BO_ 2565406709 ACKM_F5: 8 NODE_F5
 SG_ Pgn_Ack_E8FFF5 m0 : 40|24@1+ (1,0) [0|16777215] "binary"  PCM
 SG_ Pgn_Nack_E8FFF5 m1 : 40|24@1+ (1,0) [0|16777215] "binary"  PCM
 SG_ Pgn_Ad_E8FFF5 m2 : 40|24@1+ (1,0) [0|16777215] "binary"  PCM
 SG_ Pgn_Busy_E8FFF5 m3 : 40|24@1+ (1,0) [0|16777215] "binary"  PCM
 SG_ AddrAckd_E8FFF5 m0 : 32|8@1+ (1,0) [0|255] ""  PCM
 SG_ AddrNack_E8FFF5 m1 : 32|8@1+ (1,0) [0|255] ""  PCM
 SG_ AddrAccessDenied_E8FFF5 m2 : 32|8@1+ (1,0) [0|255] ""  PCM
 SG_ AddrBusy_E8FFF5 m3 : 32|8@1+ (1,0) [0|255] ""  PCM
 SG_ CtrlByte_Ackm_E8FFF5 M : 0|8@1+ (1,0) [0|255] "binary"  PCM

BO_ 2565406710 ACKM_F6: 8 NODE_F6
 SG_ Pgn_Ack_E8FFF6 m0 : 40|24@1+ (1,0) [0|16777215] "binary"  PCM
 SG_ Pgn_Nack_E8FFF6 m1 : 40|24@1+ (1,0) [0|16777215] "binary"  PCM
 SG_ Pgn_Ad_E8FFF6 m2 : 40|24@1+ (1,0) [0|16777215] "binary"  PCM
 SG_ Pgn_Busy_E8FFF6 m3 : 40|24@1+ (1,0) [0|16777215] "binary"  PCM
 SG_ AddrAckd_E8FFF6 m0 : 32|8@1+ (1,0) [0|255] ""  PCM
 SG_ AddrNack_E8FFF6 m1 : 32|8@1+ (1,0) [0|255] ""  PCM
 SG_ AddrAccessDenied_E8FFF6 m2 : 32|8@1+ (1,0) [0|255] ""  PCM
 SG_ AddrBusy_E8FFF6 m3 : 32|8@1+ (1,0) [0|255] ""  PCM
 SG_ CtrlByte_Ackm_E8FFF6 M : 0|8@1+ (1,0) [0|255] "binary"  PCM

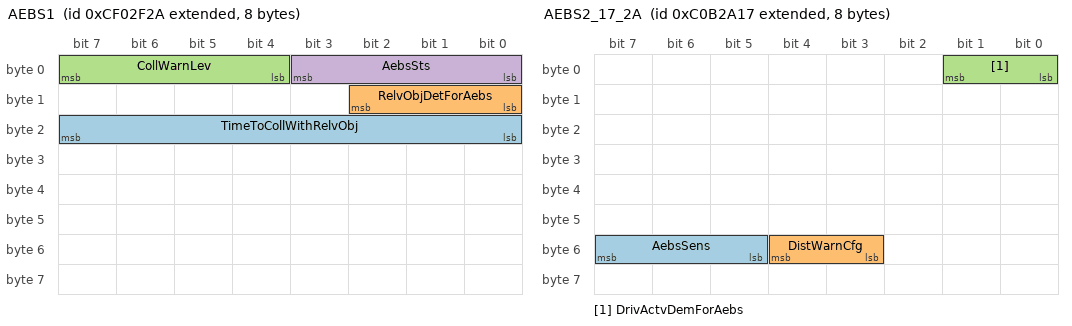
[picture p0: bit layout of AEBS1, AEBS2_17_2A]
BO_ 2364550954 AEBS1: 8 LDW
 SG_ TimeToCollWithRelvObj : 16|8@1+ (0.05,0) [0|12.5] "s"  PCM
 SG_ RelvObjDetForAebs : 8|3@1+ (1,0) [0|7] ""  PCM
 SG_ CollWarnLev : 4|4@1+ (1,0) [0|15] ""  PCM
 SG_ AebsSts : 0|4@1+ (1,0) [0|15] ""  PCM

BO_ 2349541911 AEBS2_17_2A: 8 ICC
 SG_ AebsSens : 53|3@1+ (1,0) [0|7] ""  PCM,LDW
 SG_ DistWarnCfg : 51|2@1+ (1,0) [0|3] ""  PCM,LDW
 SG_ DrivActvDemForAebs : 0|2@1+ (1,0) [0|3] ""  PCM,LDW

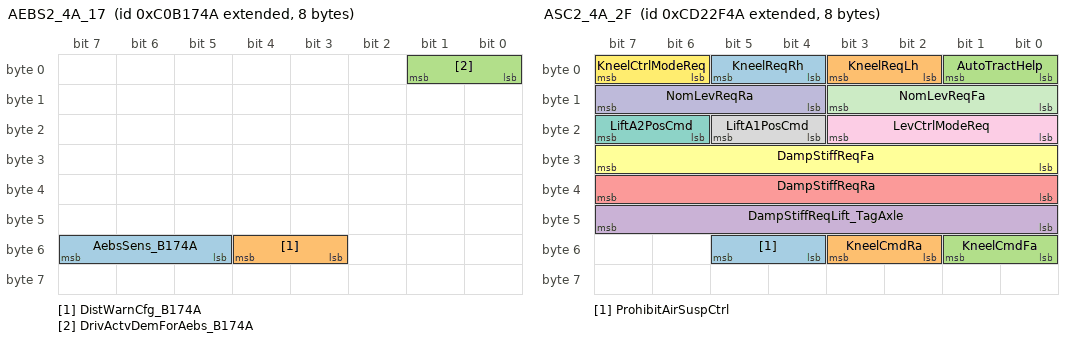
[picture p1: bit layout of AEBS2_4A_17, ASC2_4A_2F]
BO_ 2349537098 AEBS2_4A_17: 8 PCM
 SG_ AebsSens_B174A : 53|3@1+ (1,0) [0|7] ""  ICC
 SG_ DistWarnCfg_B174A : 51|2@1+ (1,0) [0|3] ""  ICC
 SG_ DrivActvDemForAebs_B174A : 0|2@1+ (1,0) [0|3] ""  ICC

BO_ 2566845696 AMB_00: 8 ECM
 SG_ BaromPrs : 0|8@1+ (0.5,0) [0|125] "kPa"  PCM

BO_ 2566845729 AMB_21: 8 BCM
 SG_ AmbAirTemp : 24|16@1+ (0.03125,-273) [-273|1734.96875] "�C"  PCM

BO_ 2566774807 AMB2_17: 8 ICC
 SG_ SolarIntensPc : 0|8@1+ (0.4,0) [0|100] "%"  PCM

BO_ 2566837537 AS_21: 8 BCM
 SG_ Altern1Sts : 16|2@1+ (1,0) [0|3] ""  PCM

BO_ 2365479471 ASC1_2F: 8 ECAS
 SG_ SuspCtrlRefusalInfo : 56|4@1+ (1,0) [0|15] ""  PCM
 SG_ SpeedDepLevCtrlSts : 54|2@1+ (1,0) [0|3] ""  PCM
 SG_ AllowLevCtrlDurBrkSts : 52|2@1+ (1,0) [0|3] ""  PCM
 SG_ SuspRemCtrl2 : 50|2@1+ (1,0) [0|3] ""  PCM
 SG_ SuspRemCtrl1 : 48|2@1+ (1,0) [0|3] ""  PCM
 SG_ LiftA2Pos : 46|2@1+ (1,0) [0|3] ""  PCM
 SG_ RaInBumperRng : 42|2@1+ (1,0) [0|3] ""  PCM
 SG_ FaInBumperRng : 40|2@1+ (1,0) [0|3] ""  PCM
 SG_ LiftA1Pos : 38|2@1+ (1,0) [0|3] ""  PCM
 SG_ DoorRels : 36|2@1+ (1,0) [0|3] ""  PCM
 SG_ VehMotInh : 34|2@1+ (1,0) [0|3] ""  PCM
 SG_ SecurDev : 32|2@1+ (1,0) [0|3] ""  PCM
 SG_ LevCtrlMode : 28|4@1+ (1,0) [0|15] ""  PCM
 SG_ KneelInfo : 24|4@1+ (1,0) [0|15] ""  PCM
 SG_ LiftCtrlModeRa : 22|2@1+ (1,0) [0|3] ""  PCM
 SG_ LiftCtrlModeFa : 20|2@1+ (1,0) [0|3] ""  PCM
 SG_ LowCtrlModeRa : 18|2@1+ (1,0) [0|3] ""  PCM
 SG_ LowCtrlModeFa : 16|2@1+ (1,0) [0|3] ""  PCM
 SG_ AbvNomLevRa : 14|2@1+ (1,0) [0|3] ""  PCM
 SG_ AbvNomLevFa : 12|2@1+ (1,0) [0|3] ""  PCM
 SG_ BlwNomLevRa : 10|2@1+ (1,0) [0|3] ""  PCM
 SG_ BlwNomLevFa : 8|2@1+ (1,0) [0|3] ""  PCM
 SG_ NomLevRa : 4|4@1+ (1,0) [0|15] ""  PCM
 SG_ NomLevFa : 0|4@1+ (1,0) [0|15] ""  PCM

BO_ 2362584906 ASC2_4A_2F: 8 PCM
 SG_ ProhibitAirSuspCtrl : 52|2@1+ (1,0) [0|3] ""  ECAS
 SG_ KneelCmdRa : 50|2@1+ (1,0) [0|3] ""  ECAS
 SG_ KneelCmdFa : 48|2@1+ (1,0) [0|3] ""  ECAS
 SG_ DampStiffReqLift_TagAxle : 40|8@1+ (0.4,0) [0|100] "%"  ECAS
 SG_ DampStiffReqRa : 32|8@1+ (0.4,0) [0|100] "%"  ECAS
 SG_ DampStiffReqFa : 24|8@1+ (0.4,0) [0|100] "%"  ECAS
 SG_ LiftA2PosCmd : 22|2@1+ (1,0) [0|3] ""  ECAS
 SG_ LiftA1PosCmd : 20|2@1+ (1,0) [0|3] ""  ECAS
 SG_ LevCtrlModeReq : 16|4@1+ (1,0) [0|15] ""  ECAS
 SG_ NomLevReqRa : 12|4@1+ (1,0) [0|15] ""  ECAS
 SG_ NomLevReqFa : 8|4@1+ (1,0) [0|15] ""  ECAS
 SG_ KneelCtrlModeReq : 6|2@1+ (1,0) [0|3] ""  ECAS
 SG_ KneelReqRh : 4|2@1+ (1,0) [0|3] ""  ECAS
 SG_ KneelReqLh : 2|2@1+ (1,0) [0|3] ""  ECAS
 SG_ AutoTractHelp : 0|2@1+ (1,0) [0|3] ""  ECAS

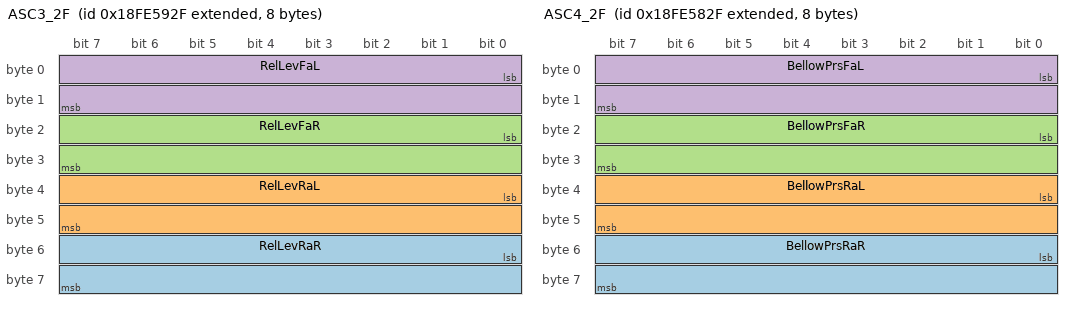
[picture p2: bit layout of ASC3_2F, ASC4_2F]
BO_ 2566805807 ASC3_2F: 8 ECAS
 SG_ RelLevRaR : 48|16@1+ (0.1,-3200) [-3200|3225.5] "mm"  PCM
 SG_ RelLevRaL : 32|16@1+ (0.1,-3200) [-3200|3225.5] "mm"  PCM
 SG_ RelLevFaR : 16|16@1+ (0.1,-3200) [-3200|3225.5] "mm"  PCM
 SG_ RelLevFaL : 0|16@1+ (0.1,-3200) [-3200|3225.5] "mm"  PCM

BO_ 2566805551 ASC4_2F: 8 ECAS
 SG_ BellowPrsRaR : 48|16@1+ (0.1,0) [0|6425.5] "kPa"  PCM
 SG_ BellowPrsRaL : 32|16@1+ (0.1,0) [0|6425.5] "kPa"  PCM
 SG_ BellowPrsFaR : 16|16@1+ (0.1,0) [0|6425.5] "kPa"  PCM
 SG_ BellowPrsFaL : 0|16@1+ (0.1,0) [0|6425.5] "kPa"  PCM

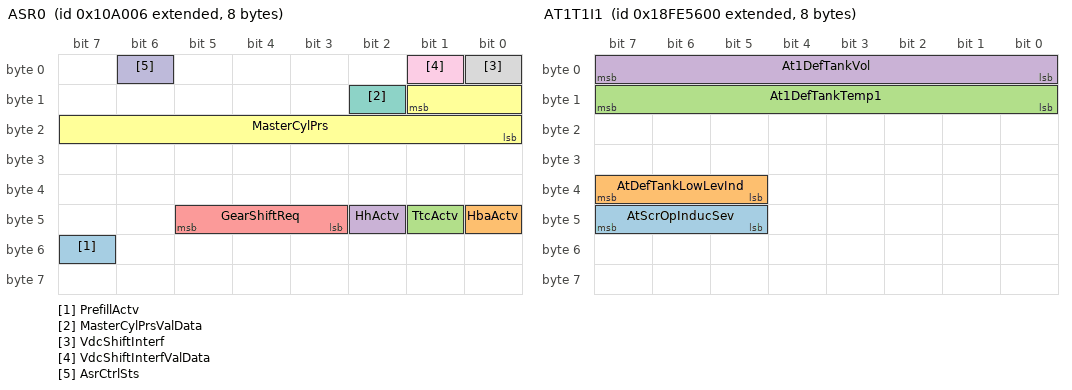
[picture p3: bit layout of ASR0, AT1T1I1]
BO_ 2148573190 ASR0: 8 NODE_6
 SG_ PrefillActv : 55|1@0+ (1,0) [0|1] ""  PCM,AEBS
 SG_ HbaActv : 40|1@0+ (1,0) [0|1] ""  PCM,AEBS
 SG_ TtcActv : 41|1@0+ (1,0) [0|1] ""  PCM,AEBS
 SG_ HhActv : 42|1@0+ (1,0) [0|1] ""  PCM,AEBS
 SG_ GearShiftReq : 45|3@0+ (1,0) [0|7] ""  PCM,AEBS
 SG_ MasterCylPrs : 9|10@0+ (0.25,0) [0|200] "bar"  PCM,AEBS
 SG_ MasterCylPrsValData : 10|1@0+ (1,0) [0|1] ""  PCM,AEBS
 SG_ VdcShiftInterf : 0|1@0+ (1,0) [0|1] ""  PCM,AEBS
 SG_ VdcShiftInterfValData : 1|1@0+ (1,0) [0|1] ""  PCM,AEBS
 SG_ AsrCtrlSts : 6|1@0+ (1,0) [0|1] ""  PCM,AEBS

BO_ 2566763008 AT1IMG: 8 ECM
 SG_ At1DpfDiffPrs : 32|16@1+ (0.1,0) [0|6425.5] "kPa"  PCM

BO_ 2566804992 AT1T1I1: 8 ECM
 SG_ AtScrOpInducSev : 45|3@1+ (1,0) [0|7] ""  PCM
 SG_ AtDefTankLowLevInd : 37|3@1+ (1,0) [0|7] ""  PCM
 SG_ At1DefTankTemp1 : 8|8@1+ (1,-40) [-40|210] "�C"  PCM
 SG_ At1DefTankVol : 0|8@1+ (0.4,0) [0|100] "%"  PCM

BO_ 2564685591 ATR_17: 8 ICC
 SG_ AntiTheftPswRepr : 8|56@1+ (1,0) [0|255] "ASCII"  PCM
 SG_ AntiTheftCmdSts : 5|3@1+ (1,0) [0|7] ""  PCM

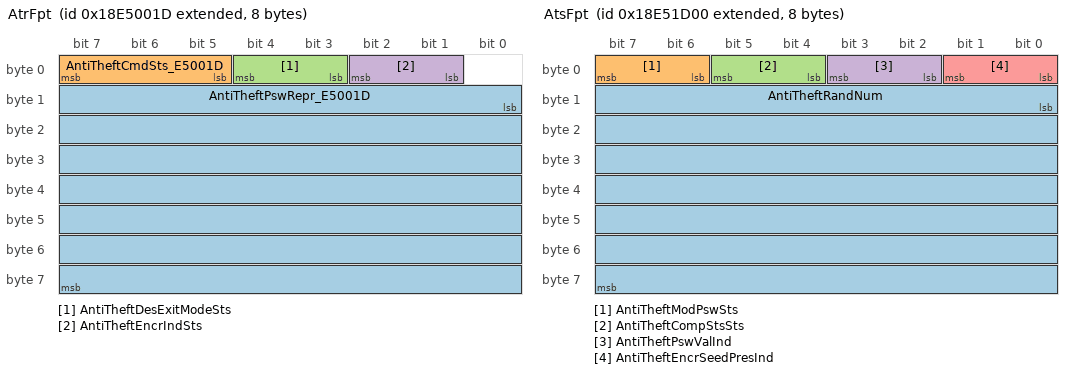
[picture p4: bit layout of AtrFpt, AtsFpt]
BO_ 2565144605 AtrFpt: 8 SGW
 SG_ AntiTheftPswRepr_E5001D : 8|56@1+ (1,0) [0|255] "ASCII"  PCM,ECM
 SG_ AntiTheftCmdSts_E5001D : 5|3@1+ (1,0) [0|7] ""  PCM,ECM
 SG_ AntiTheftDesExitModeSts : 3|2@1+ (1,0) [0|3] ""  PCM,ECM
 SG_ AntiTheftEncrIndSts : 1|2@1+ (1,0) [0|3] ""  PCM,ECM

BO_ 2565152000 AtsFpt: 8 ECM
 SG_ AntiTheftRandNum : 8|56@1+ (1,0) [0|255] "ASCII"  PCM,SGW
 SG_ AntiTheftModPswSts : 6|2@1+ (1,0) [0|3] ""  PCM,SGW
 SG_ AntiTheftCompStsSts : 4|2@1+ (1,0) [0|3] ""  PCM,SGW
 SG_ AntiTheftPswValInd : 2|2@1+ (1,0) [0|3] ""  PCM,SGW
 SG_ AntiTheftEncrSeedPresInd : 0|2@1+ (1,0) [0|3] ""  PCM,SGW

BO_ 2561146657 AUXIO2_SW_21: 8 BCM
 SG_ MsgCks : 60|4@1+ (1,0) [0|15] "count"  PCM
 SG_ MsgCnt : 56|4@1+ (1,0) [0|15] "count"  PCM
 SG_ RightStackBtn : 54|2@1+ (1,0) [0|3] ""  PCM
 SG_ Sw8_Vsla_IcMenuRtn : 46|2@1+ (1,0) [0|3] ""  PCM
 SG_ Sw7_AccDist_IcMenu2 : 44|2@1+ (1,0) [0|3] ""  PCM
 SG_ Sw6_AccEna_IcMenu1 : 42|2@1+ (1,0) [0|3] ""  PCM
 SG_ Sw2_CcEna_AccEna : 40|2@1+ (1,0) [0|3] ""  PCM
 SG_ Sw3_CcRes_Canc : 38|2@1+ (1,0) [0|3] ""  PCM
 SG_ Sw5_CcCanc_Vsla : 36|2@1+ (1,0) [0|3] ""  PCM
 SG_ Sw4_CcSetDec : 34|2@1+ (1,0) [0|3] ""  PCM
 SG_ Sw1_CcSetAcc : 32|2@1+ (1,0) [0|3] ""  PCM
 SG_ SwB_NextSrc : 28|2@1+ (1,0) [0|3] ""  PCM
 SG_ SwC_ScanDw : 26|2@1+ (1,0) [0|3] ""  PCM
 SG_ SwA_ScanUp : 24|2@1+ (1,0) [0|3] ""  PCM
 SG_ SwE_Mute : 20|2@1+ (1,0) [0|3] ""  PCM
 SG_ SwF_VolDw : 18|2@1+ (1,0) [0|3] ""  PCM
 SG_ SwD_VolUp : 16|2@1+ (1,0) [0|3] ""  PCM
 SG_ SwR_IcMenu_Hwa : 14|2@1+ (1,0) [0|3] ""  PCM
 SG_ SwQ_VoiceRec : 12|2@1+ (1,0) [0|3] ""  PCM
 SG_ SwP_PhoneCall : 10|2@1+ (1,0) [0|3] ""  PCM
 SG_ SwN_Ok : 8|2@1+ (1,0) [0|3] ""  PCM
 SG_ SwH_Right : 6|2@1+ (1,0) [0|3] ""  PCM
 SG_ SwM_Left : 4|2@1+ (1,0) [0|3] ""  PCM
 SG_ SwL_Dw : 2|2@1+ (1,0) [0|3] ""  PCM
 SG_ SwG_Up : 0|2@1+ (1,0) [0|3] ""  PCM

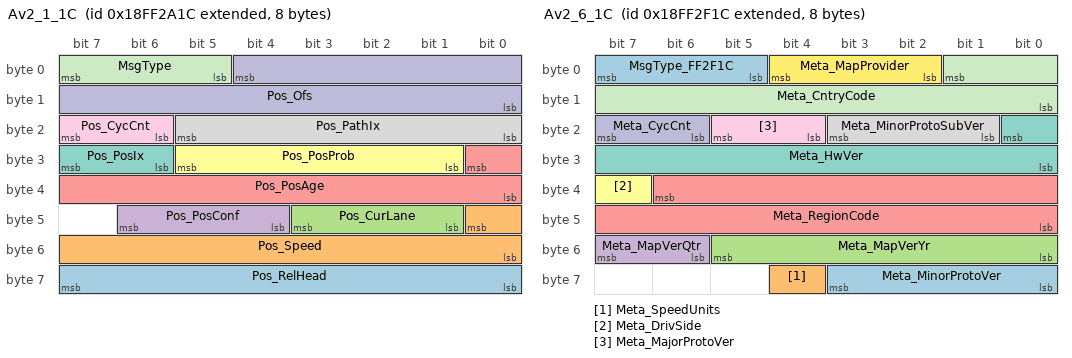
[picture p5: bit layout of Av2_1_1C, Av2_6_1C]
BO_ 2566859292 Av2_1_1C: 8 PCM
 SG_ Pos_RelHead : 63|8@0+ (1.41732283464567,0) [0|358.583] "deg" Vector__XXX
 SG_ Pos_Speed : 40|9@0+ (0.2,-12.8) [-12.8|89.4] "m/s" Vector__XXX
 SG_ Pos_CurLane : 43|3@0+ (1,0) [0|7] "" Vector__XXX
 SG_ Pos_PosConf : 46|3@0+ (1,0) [0|7] "" Vector__XXX
 SG_ Pos_PosAge : 24|9@0+ (5,0) [0|2545] "ms" Vector__XXX
 SG_ Pos_PosProb : 29|5@0+ (3.33333333333333,0) [0|100] "%" Vector__XXX
 SG_ Pos_PosIx : 31|2@0+ (1,0) [0|3] "" Vector__XXX
 SG_ Pos_PathIx : 21|6@0+ (1,0) [8|63] "" Vector__XXX
 SG_ Pos_CycCnt : 23|2@0+ (1,0) [0|3] "" Vector__XXX
 SG_ Pos_Ofs : 4|13@0+ (1,0) [0|8190] "m" Vector__XXX
 SG_ MsgType : 7|3@0+ (1,0) [0|7] "" Vector__XXX

BO_ 2566859548 Av2_2_1C: 8 PCM
 SG_ Seg_NumOfLanesInDrivDir : 58|3@0+ (1,0) [0|7] "" Vector__XXX
 SG_ Seg_NumOfLanesInOppDir : 60|2@0+ (1,0) [0|3] "" Vector__XXX
 SG_ Seg_DividedRoad : 62|2@0+ (1,0) [0|3] "" Vector__XXX
 SG_ Seg_EffSpeedLimType : 50|3@0+ (1,0) [0|7] "" Vector__XXX
 SG_ Seg_EffSpeedLim : 55|5@0+ (1,0) [0|31] "km/h or mph" Vector__XXX
 SG_ Seg_FormOfWay : 43|4@0+ (1,0) [0|14] "" Vector__XXX
 SG_ Seg_ComplexInters : 45|2@0+ (1,0) [0|3] "" Vector__XXX
 SG_ Seg_PartOfCalcRoute : 47|2@0+ (1,0) [0|3] "" Vector__XXX
 SG_ Seg_FunctRoadClass : 34|3@0+ (1,0) [0|6] "" Vector__XXX
 SG_ Seg_RelProb : 39|5@0+ (3.33333333333333,0) [0|100] "%" Vector__XXX
 SG_ Seg_Update : 24|1@0+ (1,0) [0|1] "" Vector__XXX
 SG_ Seg_Retr : 25|1@0+ (1,0) [0|1] "" Vector__XXX
 SG_ Seg_BuiltUpArea : 27|2@0+ (1,0) [0|3] "" Vector__XXX
 SG_ Seg_Bridge : 29|2@0+ (1,0) [0|3] "" Vector__XXX
 SG_ Seg_Tunnel : 31|2@0+ (1,0) [0|3] "" Vector__XXX
 SG_ Seg_PathIx : 21|6@0+ (1,0) [8|63] "" Vector__XXX
 SG_ Seg_CycCnt : 23|2@0+ (1,0) [0|3] "" Vector__XXX
 SG_ Seg_Ofs : 4|13@0+ (1,0) [0|8190] "m" Vector__XXX
 SG_ MsgType_FF2B1C : 7|3@0+ (1,0) [0|7] "" Vector__XXX

BO_ 2566859804 Av2_3_1C: 8 PCM
 SG_ Stub_NumOfLanesInDrivDir : 58|3@0+ (1,0) [0|7] "" Vector__XXX
 SG_ Stub_NumOfLanesInOppDir : 60|2@0+ (1,0) [0|3] "" Vector__XXX
 SG_ Stub_RightOfWay : 62|2@0+ (1,0) [0|3] "" Vector__XXX
 SG_ Stub_LastStubAtOfs : 63|1@0+ (1,0) [0|1] "" Vector__XXX
 SG_ Stub_TurnAngle : 55|8@0+ (1.41732283464567,0) [0|358.583] "deg" Vector__XXX
 SG_ Stub_FormOfWay : 43|4@0+ (1,0) [0|14] "" Vector__XXX
 SG_ Stub_ComplexInters : 45|2@0+ (1,0) [0|3] "" Vector__XXX
 SG_ Stub_PartOfCalcRoute : 47|2@0+ (1,0) [0|3] "" Vector__XXX
 SG_ Stub_FunctRoadClass : 34|3@0+ (1,0) [0|6] "" Vector__XXX
 SG_ Stub_RelProb : 39|5@0+ (3.33333333333333,0) [0|100] "%" Vector__XXX
 SG_ Stub_Update : 24|1@0+ (1,0) [0|1] "" Vector__XXX
 SG_ Stub_Retr : 25|1@0+ (1,0) [0|1] "" Vector__XXX
 SG_ Stub_SubPathIx : 31|6@0+ (1,0) [8|63] "" Vector__XXX
 SG_ Stub_PathIx : 21|6@0+ (1,0) [8|63] "" Vector__XXX
 SG_ Stub_CycCnt : 23|2@0+ (1,0) [0|3] "" Vector__XXX
 SG_ Stub_Ofs : 4|13@0+ (1,0) [0|8190] "m" Vector__XXX
 SG_ MsgType_FF2C1C : 7|3@0+ (1,0) [0|7] "" Vector__XXX

BO_ 2566860060 Av2_4_1C: 8 PCM
 SG_ ProfShort_Val1_1_Curv m1 : 49|10@0+ (1,0) [0|1022] "1/m or m" Vector__XXX
 SG_ ProfShort_Val1_2_RouteNumTypes m2 : 49|10@0+ (1,0) [0|1022] "bit-mapped" Vector__XXX
 SG_ ProfShort_Val1_3_Slope m3 : 49|10@0+ (0.1,-51.1) [-51.1|51.1] "%" Vector__XXX
 SG_ ProfShort_Val1_4_Slope m4 : 49|10@0+ (0.1,-51.1) [-51.1|51.1] "%" Vector__XXX
 SG_ ProfShort_Val1_5_RoadAcc m5 : 49|10@0+ (1,0) [0|1022] "bit-mapped" Vector__XXX
 SG_ ProfShort_Val1_6_RoadCond m6 : 49|10@0+ (1,0) [0|1022] "bit-mapped" Vector__XXX
 SG_ ProfShort_Val1_7_VarSpeedSignPos m7 : 49|10@0+ (1,0) [0|1023] "bit-mapped" Vector__XXX
 SG_ ProfShort_Val1_8_HeadChg m8 : 49|10@0+ (1.41732283464567,0) [0|358.583] "deg" Vector__XXX
 SG_ ProfShort_Val1_9_RsvdForStdTypes m9 : 49|10@0+ (1,0) [0|1023] "" Vector__XXX
 SG_ ProfShort_Val1_16_RsvdForSysSpec m16 : 49|10@0+ (1,0) [0|1023] "" Vector__XXX
 SG_ ProfShort_Val0_1_Curv m1 : 43|10@0+ (1,0) [0|1022] "1/m or m" Vector__XXX
 SG_ ProfShort_Val0_2_RouteNumTypes m2 : 43|10@0+ (1,0) [0|1022] "bit-mapped" Vector__XXX
 SG_ ProfShort_Val0_3_Slope m3 : 43|10@0+ (0.1,-51.1) [-51.1|51.1] "%" Vector__XXX
 SG_ ProfShort_Val0_4_Slope m4 : 43|10@0+ (0.1,-51.1) [-51.1|51.1] "%" Vector__XXX
 SG_ ProfShort_Val0_5_RoadAcc m5 : 43|10@0+ (1,0) [0|1022] "bit-mapped" Vector__XXX
 SG_ ProfShort_Val0_6_RoadCond m6 : 43|10@0+ (1,0) [0|1022] "bit-mapped" Vector__XXX
 SG_ ProfShort_Val0_7_VarSpeedSignPos m7 : 43|10@0+ (1,0) [0|1023] "bit-mapped" Vector__XXX
 SG_ ProfShort_Val0_8_HeadChg m8 : 43|10@0+ (1.41732283464567,0) [0|358.583] "deg" Vector__XXX
 SG_ ProfShort_Val0_9_RsvdForStdTypes m9 : 43|10@0+ (1,0) [0|1023] "" Vector__XXX
 SG_ ProfShort_Val0_16_RsvdForSysSpec m16 : 43|10@0+ (1,0) [0|1023] "" Vector__XXX
 SG_ ProfShort_Dist1 : 37|10@0+ (1,0) [0|1022] "m" Vector__XXX
 SG_ ProfShort_Accur : 39|2@0+ (1,0) [0|3] "" Vector__XXX
 SG_ ProfShort_Update : 24|1@0+ (1,0) [0|1] "" Vector__XXX
 SG_ ProfShort_Retr : 25|1@0+ (1,0) [0|1] "" Vector__XXX
 SG_ ProfShort_CtrlPnt : 26|1@0+ (1,0) [0|1] "" Vector__XXX
 SG_ ProfShort_ProfType M : 31|5@0+ (1,0) [0|31] "" Vector__XXX
 SG_ ProfShort_PathIx : 21|6@0+ (1,0) [8|63] "" Vector__XXX
 SG_ ProfShort_CycCnt : 23|2@0+ (1,0) [0|3] "" Vector__XXX
 SG_ ProfShort_Ofs : 4|13@0+ (1,0) [0|8190] "m" Vector__XXX
 SG_ MsgType_FF2D1C : 7|3@0+ (1,0) [0|7] "" Vector__XXX

BO_ 2566860316 Av2_5_1C: 8 PCM
 SG_ ProfLong_Val96_TimeVal m9 : 57|2@0+ (1,0) [0|3] "" Vector__XXX
 SG_ ProfLong_Val97_TimeDep m9 : 58|1@0+ (1,0) [0|1] "" Vector__XXX
 SG_ ProfLong_Val93_HazardousGoods m9 : 50|3@0+ (1,0) [0|7] "" Vector__XXX
 SG_ ProfLong_Val94_WeatherRestr m9 : 53|3@0+ (1,0) [0|7] "" Vector__XXX
 SG_ ProfLong_Val95_Type m9 : 55|2@0+ (1,0) [0|3] "" Vector__XXX
 SG_ ProfLong_Val92_Wt m9 : 47|8@0+ (0.5,0) [0|127] "tons" Vector__XXX
 SG_ ProfLong_Val1_Long m1 : 39|32@0+ (1E-007,-180) [-180|241.1081215] "deg" Vector__XXX
 SG_ ProfLong_Val2_Lat m2 : 39|32@0+ (1E-007,-90) [-90|331.1081215] "deg" Vector__XXX
 SG_ ProfLong_Val3_Altitude m3 : 39|32@0+ (0.01,-1000) [-1000|10000] "m" Vector__XXX
 SG_ ProfLong_Val4_CtrlPntLong m4 : 39|32@0+ (1E-007,-180) [-180|241.1081215] "deg" Vector__XXX
 SG_ ProfLong_Val5_CtrlPntLat m5 : 39|32@0+ (1E-007,-90) [-90|331.1081215] "deg" Vector__XXX
 SG_ ProfLong_Val6_CtrlPntAltitude m6 : 39|32@0+ (0.01,-1000) [-1000|10000] "m" Vector__XXX
 SG_ ProfLong_Val7_LinkId m7 : 39|32@0+ (1,0) [0|4211081215] "" Vector__XXX
 SG_ ProfLong_Val8_TrafficSign m8 : 39|32@0+ (1,0) [0|4211081215] "" Vector__XXX
 SG_ ProfLong_Val91_Speed m9 : 39|8@0+ (1,0) [0|255] "km/h or mph" Vector__XXX
 SG_ ProfLong_Val10_ExLane m10 : 39|32@0+ (1,0) [0|4211081215] "" Vector__XXX
 SG_ ProfLong_Val11_RsvdForStdTypes m11 : 39|32@0+ (1,0) [0|0] "" Vector__XXX
 SG_ ProfLong_Val12_RsvdForStdTypes m12 : 39|32@0+ (1,0) [0|0] "" Vector__XXX
 SG_ ProfLong_Val13_RsvdForStdTypes m13 : 39|32@0+ (1,0) [0|0] "" Vector__XXX
 SG_ ProfLong_Val14_RsvdForStdTypes m14 : 39|32@0+ (1,0) [0|0] "" Vector__XXX
 SG_ ProfLong_Val15_RsvdForStdTypes m15 : 39|32@0+ (1,0) [0|0] "" Vector__XXX
 SG_ ProfLong_Val16_RsvdForSysSpecTyp m16 : 39|32@0+ (1,0) [0|0] "" Vector__XXX
 SG_ ProfLong_Val17_RsvdForSysSpecTyp m17 : 39|32@0+ (1,0) [0|0] "" Vector__XXX
 SG_ ProfLong_Val18_RsvdForSysSpecTyp m18 : 39|32@0+ (1,0) [0|0] "" Vector__XXX
 SG_ ProfLong_Val19_RsvdForSysSpecTyp m19 : 39|32@0+ (1,0) [0|0] "" Vector__XXX
 SG_ ProfLong_Val20_RsvdForSysSpecTyp m20 : 39|32@0+ (1,0) [0|0] "" Vector__XXX
 SG_ ProfLong_Val21_RsvdForSysSpecTyp m21 : 39|32@0+ (1,0) [0|0] "" Vector__XXX
 SG_ ProfLong_Val22_RsvdForSysSpecTyp m22 : 39|32@0+ (1,0) [0|0] "" Vector__XXX
 SG_ ProfLong_Val23_RsvdForSysSpecTyp m23 : 39|32@0+ (1,0) [0|0] "" Vector__XXX
 SG_ ProfLong_Val24_RsvdForSysSpecTyp m24 : 39|32@0+ (1,0) [0|0] "" Vector__XXX
 SG_ ProfLong_Val25_RsvdForSysSpecTyp m25 : 39|32@0+ (1,0) [0|0] "" Vector__XXX
 SG_ ProfLong_Val26_RsvdForSysSpecTyp m26 : 39|32@0+ (1,0) [0|0] "" Vector__XXX
 SG_ ProfLong_Val27_RsvdForSysSpecTyp m27 : 39|32@0+ (1,0) [0|0] "" Vector__XXX
 SG_ ProfLong_Val28_RsvdForSysSpecTyp m28 : 39|32@0+ (1,0) [0|0] "" Vector__XXX
 SG_ ProfLong_Val29_RsvdForSysSpecTyp m29 : 39|32@0+ (1,0) [0|0] "" Vector__XXX
 SG_ ProfLong_Val30_RsvdForSysSpecTyp m30 : 39|32@0+ (1,0) [0|0] "" Vector__XXX
 SG_ ProfLong_Val31_RsvdForSysSpecTyp m31 : 39|32@0+ (1,0) [0|0] "" Vector__XXX
 SG_ ProfLong_Update : 24|1@0+ (1,0) [0|1] "" Vector__XXX
 SG_ ProfLong_Retr : 25|1@0+ (1,0) [0|1] "" Vector__XXX
 SG_ ProfLong_CtrlPnt : 26|1@0+ (1,0) [0|1] "" Vector__XXX
 SG_ ProfLong_ProfType M : 31|5@0+ (1,0) [0|31] "" Vector__XXX
 SG_ ProfLong_PathIx : 21|6@0+ (1,0) [8|63] "" Vector__XXX
 SG_ ProfLong_CycCnt : 23|2@0+ (1,0) [0|3] "" Vector__XXX
 SG_ ProfLong_Ofs : 4|13@0+ (1,0) [0|8190] "m" Vector__XXX
 SG_ MsgType_FF2E1C : 7|3@0+ (1,0) [0|7] "" Vector__XXX

BO_ 2566860572 Av2_6_1C: 8 PCM
 SG_ Meta_MinorProtoVer : 59|4@0+ (1,0) [0|15] "" Vector__XXX
 SG_ Meta_SpeedUnits : 60|1@0+ (1,0) [0|1] "" Vector__XXX
 SG_ Meta_MapVerYr : 53|6@0+ (1,2000) [2000|2063] "year" Vector__XXX
 SG_ Meta_MapVerQtr : 55|2@0+ (1,1) [1|4] "Quarter" Vector__XXX
 SG_ Meta_RegionCode : 38|15@0+ (1,0) [0|32767] "" Vector__XXX
 SG_ Meta_DrivSide : 39|1@0+ (1,0) [0|1] "" Vector__XXX
 SG_ Meta_HwVer : 16|9@0+ (1,0) [0|511] "" Vector__XXX
 SG_ Meta_MinorProtoSubVer : 19|3@0+ (1,0) [0|7] "" Vector__XXX
 SG_ Meta_MajorProtoVer : 21|2@0+ (1,0) [0|3] "" Vector__XXX
 SG_ Meta_CycCnt : 23|2@0+ (1,0) [0|3] "" Vector__XXX
 SG_ Meta_CntryCode : 1|10@0+ (1,0) [0|1023] "" Vector__XXX
 SG_ Meta_MapProvider : 4|3@0+ (1,0) [0|7] "" Vector__XXX
 SG_ MsgType_FF2F1C : 7|3@0+ (1,0) [0|7] "" Vector__XXX

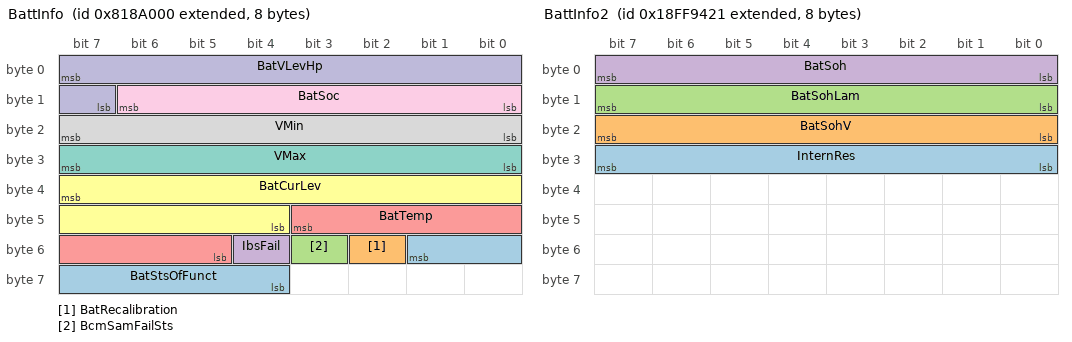
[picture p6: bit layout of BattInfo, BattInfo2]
BO_ 2283315200 BattInfo: 8 ECM
 SG_ BatStsOfFunct : 49|6@0+ (0.094,6) [0|63] "V"  PCM,AEBS
 SG_ BatRecalibration : 50|1@0+ (1,0) [0|1] ""  PCM,AEBS
 SG_ BcmSamFailSts : 51|1@0+ (1,0) [0|1] ""  PCM,AEBS
 SG_ IbsFail : 52|1@0+ (1,0) [0|1] ""  PCM,AEBS
 SG_ BatTemp : 43|7@0+ (1,-30) [-30|97] "�C"  PCM,AEBS
 SG_ BatCurLev : 39|12@0+ (0.1,-250) [-250|159.5] "A"  PCM,AEBS
 SG_ VMax : 31|8@0+ (0.025,10.6) [10.6|16.975] "V"  PCM,AEBS
 SG_ VMin : 23|8@0+ (0.025,10.6) [10.6|16.975] "V"  PCM,AEBS
 SG_ BatSoc : 14|7@0+ (1,0) [0|100] "%"  PCM,AEBS
 SG_ BatVLevHp : 7|9@0+ (0.025,4) [4|16.775] "V"  PCM,AEBS

BO_ 2566886433 BattInfo2: 8 BCM
 SG_ InternRes : 24|8@1+ (0.1,0) [0|25] "mOhm"  PCM
 SG_ BatSohV : 16|8@1+ (0.5,0) [0|125] "%"  PCM
 SG_ BatSohLam : 8|8@1+ (0.5,0) [0|125] "%"  PCM
 SG_ BatSoh : 0|8@1+ (0.5,0) [0|125] "%"  PCM

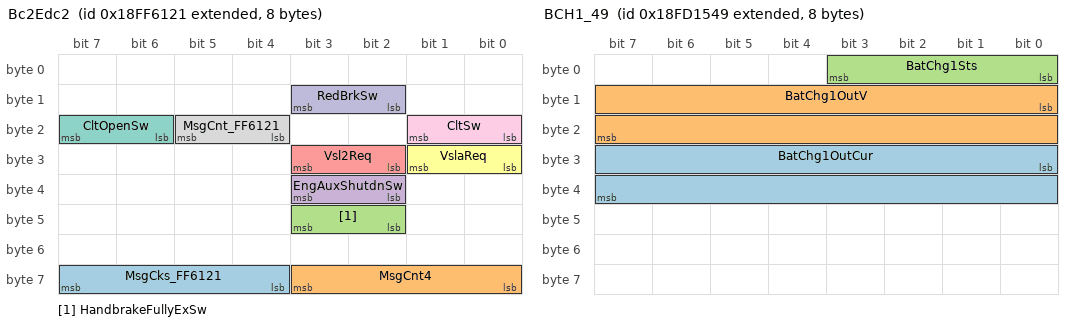
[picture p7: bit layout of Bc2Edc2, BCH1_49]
BO_ 2566873377 Bc2Edc2: 8 BCM
 SG_ MsgCks_FF6121 : 60|4@1+ (1,0) [0|15] "count"  PCM
 SG_ MsgCnt4 : 56|4@1+ (1,0) [0|15] "count"  PCM
 SG_ HandbrakeFullyExSw : 42|2@1+ (1,0) [0|3] ""  PCM
 SG_ EngAuxShutdnSw : 34|2@1+ (1,0) [0|3] ""  PCM
 SG_ Vsl2Req : 26|2@1+ (1,0) [0|3] ""  PCM
 SG_ VslaReq : 24|2@1+ (1,0) [0|3] ""  PCM
 SG_ CltOpenSw : 22|2@1+ (1,0) [0|3] ""  PCM
 SG_ MsgCnt_FF6121 : 20|2@1+ (1,0) [0|3] ""  PCM
 SG_ CltSw : 16|2@1+ (1,0) [0|3] ""  PCM
 SG_ RedBrkSw : 10|2@1+ (1,0) [0|3] ""  PCM

BO_ 2566722889 BCH1_49: 8 NODE_49
 SG_ BatChg1OutCur : 24|16@1+ (0.05,-1600) [-1600|1612.75] "A"  PCM
 SG_ BatChg1OutV : 8|16@1+ (0.05,0) [0|3212.75] "V"  PCM
 SG_ BatChg1Sts : 0|4@1+ (1,0) [0|15] ""  PCM

BO_ 2566723351 BDS_17: 8 ICC
 SG_ AllAirbagDeactSwSts : 46|2@1+ (1,0) [0|3] ""  PCM
 SG_ PassAirbagDeactSwSts : 20|2@1+ (1,0) [0|3] ""  PCM

BO_ 2566723361 BDS_21: 8 BCM
 SG_ PassBeltlockSts : 2|2@1+ (1,0) [0|3] ""  PCM
 SG_ DrivBeltlockSts : 0|2@1+ (1,0) [0|3] ""  PCM

CM_ BO_ 2565406709 "- NACK required as a response to a destination specific request that cannot be served, ACK/NACK not permitted for a global request (SAE J1939/21).";
CM_ SG_ 2565406709 Pgn_Ack_E8FFF5 "- Value Table filled with the most commonly used PGNs in Iveco applications, ECU implementation may differ";
CM_ SG_ 2565406709 Pgn_Nack_E8FFF5 "- Value Table filled with the most commonly used PGNs in Iveco applications, ECU implementation may differ";
CM_ SG_ 2565406709 Pgn_Ad_E8FFF5 "- Value Table filled with the most commonly used PGNs in Iveco applications, ECU implementation may differ";
CM_ SG_ 2565406709 Pgn_Busy_E8FFF5 "- Value Table filled with the most commonly used PGNs in Iveco applications, ECU implementation may differ";
CM_ BO_ 2565406710 "- NACK required as a response to a destination specific request that cannot be served, ACK/NACK not permitted for a global request (SAE J1939/21).";
CM_ SG_ 2565406710 Pgn_Ack_E8FFF6 "- Value Table filled with the most commonly used PGNs in Iveco applications, ECU implementation may differ";
CM_ SG_ 2565406710 Pgn_Nack_E8FFF6 "- Value Table filled with the most commonly used PGNs in Iveco applications, ECU implementation may differ";
CM_ SG_ 2565406710 Pgn_Ad_E8FFF6 "- Value Table filled with the most commonly used PGNs in Iveco applications, ECU implementation may differ";
CM_ SG_ 2565406710 Pgn_Busy_E8FFF6 "- Value Table filled with the most commonly used PGNs in Iveco applications, ECU implementation may differ";
CM_ SG_ 2364550954 RelvObjDetForAebs "- Proprietary Value Table, as a deviation from SAE";
CM_ SG_ 2566837537 Altern1Sts "- Error Indicator value also used for No Battery recharge condition";
CM_ SG_ 2365479471 NomLevRa "- 0010b = Lower Level 2
-  0011b = Upper Level 2";
CM_ SG_ 2362584906 NomLevReqRa "- 0x0 No Request
-  0x1 Norm Lev Requested
-  0x5 Cust Lev requested
-  0x6 Upper Level requested
-  0x7 Lower Level requested
-  0x8 Stop actuation
-  0x9 Manual raise while true
-  0xA Manual lower while true";
CM_ BO_ 2566805807 "- Only Enabled at EOL for Debug purposes";
CM_ BO_ 2566805551 "- Only Enabled at EOL for Debug purposes";
CM_ SG_ 2566804992 AtScrOpInducSev "- FPT used values are: 0 No Inducement, 1 Warning, 3 Torque red. (75%), 5 Creep mode (, 20km/h)
-  Vehicle speed limited to 20km/h when Severity==5 (Creep mode)";
CM_ SG_ 2564685591 AntiTheftPswRepr "- 5 digits PIN code for Lock/unlock, sent in bytes 4..8 as string in left-to-right reading order. Bytes 2..3 set to 0x20 but not used by the receiver.";
CM_ SG_ 2564685591 AntiTheftCmdSts "- 3 for Lock/Unlock";
CM_ BO_ 2565144605 "- SAE conflicting PGN, shall be replaced by 0x00DD00 (ATR)";
CM_ BO_ 2565152000 "- SAE conflicting PGN, shall be replaced by 0x00DC00 (ATS)";
CM_ BO_ 2561146657 "- Transmission repeated 2 times for each asynchronous trigger (unless another change occurs). Users of the message may then use the first, for quick reaction, or the last for confirmation.
-  Transmitted every 1s and on change of state but no faster than every 100 ms";
CM_ SG_ 2561146657 Sw3_CcRes_Canc "- Used as Res/Off toggle on Heavy Range";
CM_ SG_ 2561146657 SwP_PhoneCall "- Set to 00 if Button Not Pressed";
CM_ SG_ 2566859292 Pos_PosIx "- Always 0 in Iveco application";
CM_ SG_ 2566859292 Pos_PathIx "- Values 1, 2, 6, 8-63 supported";
CM_ SG_ 2566859292 MsgType "- Always 1";
CM_ SG_ 2566859548 MsgType_FF2B1C "- Always 2";
CM_ SG_ 2566859804 MsgType_FF2C1C "- Always 3";
CM_ SG_ 2566860060 ProfShort_Val1_1_Curv "- Not used in Iveco application";
CM_ SG_ 2566860060 ProfShort_Val1_2_RouteNumTypes "- Not used in Iveco application";
CM_ SG_ 2566860060 ProfShort_Val1_3_Slope "- Not used in Iveco application";
CM_ SG_ 2566860060 ProfShort_Val1_5_RoadAcc "- Not used in Iveco application";
CM_ SG_ 2566860060 ProfShort_Val1_6_RoadCond "- Not used in Iveco application";
CM_ SG_ 2566860060 ProfShort_Val1_7_VarSpeedSignPos "- Not used in Iveco application";
CM_ SG_ 2566860060 ProfShort_Val1_8_HeadChg "- Not used in Iveco application";
CM_ SG_ 2566860060 ProfShort_Val1_9_RsvdForStdTypes "- Not used in Iveco application";
CM_ SG_ 2566860060 ProfShort_Val1_16_RsvdForSysSpec "- Not used in Iveco application";
CM_ SG_ 2566860060 ProfShort_Val0_1_Curv "- Not used in Iveco application";
CM_ SG_ 2566860060 ProfShort_Val0_2_RouteNumTypes "- Not used in Iveco application";
CM_ SG_ 2566860060 ProfShort_Val0_3_Slope "- Not used in Iveco application";
CM_ SG_ 2566860060 ProfShort_Val0_5_RoadAcc "- Not used in Iveco application";
CM_ SG_ 2566860060 ProfShort_Val0_6_RoadCond "- Not used in Iveco application";
CM_ SG_ 2566860060 ProfShort_Val0_7_VarSpeedSignPos "- Not used in Iveco application";
CM_ SG_ 2566860060 ProfShort_Val0_8_HeadChg "- Not used in Iveco application";
CM_ SG_ 2566860060 ProfShort_Val0_9_RsvdForStdTypes "- Not used in Iveco application";
CM_ SG_ 2566860060 ProfShort_Val0_16_RsvdForSysSpec "- Not used in Iveco application";
CM_ SG_ 2566860060 ProfShort_Update "- Always 0 in Iveco application";
CM_ SG_ 2566860060 ProfShort_ProfType "- Always 4 in Iveco application";
CM_ SG_ 2566860060 MsgType_FF2D1C "- Always 4";
CM_ SG_ 2566860316 MsgType_FF2E1C "- Always 5";
CM_ SG_ 2566860572 Meta_RegionCode "- Not used in Iveco application";
CM_ SG_ 2566860572 MsgType_FF2F1C "- Always 6";
CM_ BO_ 2566873377 "- Conflicting with BCAO1";
CM_ SG_ 2566723351 AllAirbagDeactSwSts "- Proprietary Addition";
CM_ SG_ 2566723361 PassBeltlockSts "- 00b (Unlocked) only set if the seat is occupied
-  Used for  all passenger front seats";
BA_DEF_ BO_  "CI_MsgDefinition" STRING ;
BA_DEF_ BO_  "CI_MsgId" INT 0 2147483647;
BA_DEF_ BO_  "CI_MsgName" STRING ;
BA_DEF_ BO_  "GenMsgCycleTime" INT 0 3600000;
BA_DEF_ BO_  "GenMsgCycleTimeFast" INT 0 3600000;
BA_DEF_ BO_  "GenMsgDelayTime" INT 0 3600000;
BA_DEF_ BO_  "GenMsgILSupport" ENUM  "No","Yes";
BA_DEF_ BO_  "GenMsgNrOfRepetition" INT 0 1000000;
BA_DEF_ BO_  "GenMsgRequestable" INT 0 1;
BA_DEF_ BO_  "GenMsgSendType" ENUM  "cyclic","NotUsed","NotUsed","NotUsed","NotUsed","NotUsed","NotUsed","IfActive","noMsgSendType";
BA_DEF_ BO_  "GenMsgStartDelayTime" INT 0 100000;
BA_DEF_ BO_  "TpJ1939VarDlc" ENUM  "No","Yes";
BA_DEF_ BO_  "VFrameFormat" ENUM  "StandardCAN","ExtendedCAN","reserved","J1939PG";
BA_DEF_ SG_  "CI_ParId" STRING ;
BA_DEF_ SG_  "CI_SigId" INT 0 2147483647;
BA_DEF_ SG_  "CI_SigName" STRING ;
BA_DEF_ SG_  "GenSigEVName" STRING ;
BA_DEF_ SG_  "GenSigILSupport" ENUM  "No","Yes";
BA_DEF_ SG_  "GenSigInactiveValue" INT 0 2147483647;
BA_DEF_ SG_  "GenSigSendType" ENUM  "Cyclic","OnWrite","OnWriteWithRepetition","OnChange","OnChangeWithRepetition","IfActive","IfActiveWithRepetition","NoSigSendType";
BA_DEF_ SG_  "GenSigStartValue" INT 0 2147483647;
BA_DEF_ SG_  "GenSigTimeoutTime_PCM" INT 0 3600000;
BA_DEF_ SG_  "GenSigTimeoutTime_SGW" INT 0 3600000;
BA_DEF_ SG_  "SPN" INT 0 524287;
BA_DEF_ SG_  "SigType" ENUM  "Default","Range","RangeSigned","ASCII","Discrete","Control","ReferencePGN","DTC","StringDelimiter","StringLength","StringLengthControl";
BA_DEF_DEF_  "CI_MsgDefinition" "";
BA_DEF_DEF_  "CI_MsgId" 0;
BA_DEF_DEF_  "CI_MsgName" "";
BA_DEF_DEF_  "GenMsgCycleTime" 0;
BA_DEF_DEF_  "GenMsgCycleTimeFast" 0;
BA_DEF_DEF_  "GenMsgDelayTime" 1;
BA_DEF_DEF_  "GenMsgILSupport" "Yes";
BA_DEF_DEF_  "GenMsgNrOfRepetition" 0;
BA_DEF_DEF_  "GenMsgRequestable" 0;
BA_DEF_DEF_  "GenMsgSendType" "noMsgSendType";
BA_DEF_DEF_  "GenMsgStartDelayTime" 0;
BA_DEF_DEF_  "TpJ1939VarDlc" "No";
BA_DEF_DEF_  "VFrameFormat" "J1939PG";
BA_DEF_DEF_  "CI_ParId" "";
BA_DEF_DEF_  "CI_SigId" 0;
BA_DEF_DEF_  "CI_SigName" "";
BA_DEF_DEF_  "GenSigEVName" "Env@Nodename_@Signame";
BA_DEF_DEF_  "GenSigILSupport" "Yes";
BA_DEF_DEF_  "GenSigInactiveValue" 0;
BA_DEF_DEF_  "GenSigSendType" "NoSigSendType";
BA_DEF_DEF_  "GenSigStartValue" 0;
BA_DEF_DEF_  "GenSigTimeoutTime_PCM" 0;
BA_DEF_DEF_  "GenSigTimeoutTime_SGW" 0;
BA_DEF_DEF_  "SPN" 0;
BA_DEF_DEF_  "SigType" "Default";
BA_ "CI_MsgDefinition" BO_ 2565406709 "J1939-21";
BA_ "CI_MsgId" BO_ 2565406709 32919;
BA_ "CI_MsgName" BO_ 2565406709 "ACKM_F5 - Acknowledgment Message";
BA_ "CI_MsgDefinition" BO_ 2565406710 "J1939-21";
BA_ "CI_MsgId" BO_ 2565406710 32933;
BA_ "CI_MsgName" BO_ 2565406710 "ACKM_F6 - Acknowledgment Message";
BA_ "CI_MsgDefinition" BO_ 2364550954 "J1939DA";
BA_ "CI_MsgId" BO_ 2364550954 43739;
BA_ "CI_MsgName" BO_ 2364550954 "AEBS1 - Advanced Emergency Braking System 1";
BA_ "GenMsgCycleTime" BO_ 2364550954 50;
BA_ "GenMsgCycleTimeFast" BO_ 2364550954 50;
BA_ "GenMsgDelayTime" BO_ 2364550954 10;
BA_ "GenMsgSendType" BO_ 2364550954 0;
BA_ "GenMsgStartDelayTime" BO_ 2364550954 36;
BA_ "CI_MsgDefinition" BO_ 2349541911 "J1939DA";
BA_ "CI_MsgId" BO_ 2349541911 42823;
BA_ "CI_MsgName" BO_ 2349541911 "AEBS2_17_2A - Advanced Emergency Braking System 2";
BA_ "GenMsgCycleTime" BO_ 2349541911 250;
BA_ "GenMsgCycleTimeFast" BO_ 2349541911 250;
BA_ "GenMsgDelayTime" BO_ 2349541911 125;
BA_ "GenMsgSendType" BO_ 2349541911 0;
BA_ "GenMsgStartDelayTime" BO_ 2349541911 102;
BA_ "CI_MsgDefinition" BO_ 2349537098 "J1939DA";
BA_ "CI_MsgId" BO_ 2349537098 42829;
BA_ "CI_MsgName" BO_ 2349537098 "AEBS2_4A_17 - Advanced Emergency Braking System 2";
BA_ "CI_MsgDefinition" BO_ 2566845696 "J1939DA";
BA_ "CI_MsgId" BO_ 2566845696 2995;
BA_ "CI_MsgName" BO_ 2566845696 "AMB_00 - Ambient Conditions";
BA_ "GenMsgCycleTime" BO_ 2566845696 1000;
BA_ "GenMsgCycleTimeFast" BO_ 2566845696 1000;
BA_ "GenMsgDelayTime" BO_ 2566845696 500;
BA_ "GenMsgSendType" BO_ 2566845696 0;
BA_ "GenMsgStartDelayTime" BO_ 2566845696 239;
BA_ "CI_MsgDefinition" BO_ 2566845729 "J1939DA";
BA_ "CI_MsgId" BO_ 2566845729 3005;
BA_ "CI_MsgName" BO_ 2566845729 "AMB_21 - Ambient Conditions";
BA_ "GenMsgCycleTime" BO_ 2566845729 1000;
BA_ "GenMsgCycleTimeFast" BO_ 2566845729 1000;
BA_ "GenMsgDelayTime" BO_ 2566845729 500;
BA_ "GenMsgSendType" BO_ 2566845729 0;
BA_ "GenMsgStartDelayTime" BO_ 2566845729 241;
BA_ "CI_MsgDefinition" BO_ 2566774807 "J1939DA";
BA_ "CI_MsgId" BO_ 2566774807 3012;
BA_ "CI_MsgName" BO_ 2566774807 "AMB2_17 - Ambient Conditions 2";
BA_ "GenMsgCycleTime" BO_ 2566774807 1000;
BA_ "GenMsgCycleTimeFast" BO_ 2566774807 1000;
BA_ "GenMsgDelayTime" BO_ 2566774807 500;
BA_ "GenMsgSendType" BO_ 2566774807 0;
BA_ "GenMsgStartDelayTime" BO_ 2566774807 174;
BA_ "CI_MsgDefinition" BO_ 2566837537 "J1939DA";
BA_ "CI_MsgId" BO_ 2566837537 3525;
BA_ "CI_MsgName" BO_ 2566837537 "AS_21 - Alternator Information";
BA_ "GenMsgCycleTime" BO_ 2566837537 1000;
BA_ "GenMsgCycleTimeFast" BO_ 2566837537 1000;
BA_ "GenMsgDelayTime" BO_ 2566837537 100;
BA_ "GenMsgSendType" BO_ 2566837537 0;
BA_ "GenMsgStartDelayTime" BO_ 2566837537 226;
BA_ "CI_MsgDefinition" BO_ 2365479471 "J1939DA";
BA_ "CI_MsgId" BO_ 2365479471 33050;
BA_ "CI_MsgName" BO_ 2365479471 "ASC1_2F - Air Suspension Control 1";
BA_ "GenMsgCycleTime" BO_ 2365479471 100;
BA_ "GenMsgCycleTimeFast" BO_ 2365479471 100;
BA_ "GenMsgDelayTime" BO_ 2365479471 50;
BA_ "GenMsgSendType" BO_ 2365479471 0;
BA_ "GenMsgStartDelayTime" BO_ 2365479471 61;
BA_ "CI_MsgDefinition" BO_ 2362584906 "J1939DA";
BA_ "CI_MsgId" BO_ 2362584906 33101;
BA_ "CI_MsgName" BO_ 2362584906 "ASC2_4A_2F - Air Suspension Control 2";
BA_ "GenMsgCycleTime" BO_ 2362584906 100;
BA_ "GenMsgCycleTimeFast" BO_ 2362584906 100;
BA_ "GenMsgDelayTime" BO_ 2362584906 50;
BA_ "GenMsgSendType" BO_ 2362584906 0;
BA_ "GenMsgStartDelayTime" BO_ 2362584906 4;
BA_ "CI_MsgDefinition" BO_ 2566805807 "J1939DA";
BA_ "CI_MsgId" BO_ 2566805807 33075;
BA_ "CI_MsgName" BO_ 2566805807 "ASC3_2F - Air Suspension Control 3";
BA_ "GenMsgCycleTime" BO_ 2566805807 100;
BA_ "GenMsgCycleTimeFast" BO_ 2566805807 100;
BA_ "GenMsgDelayTime" BO_ 2566805807 50;
BA_ "GenMsgSendType" BO_ 2566805807 0;
BA_ "GenMsgStartDelayTime" BO_ 2566805807 74;
BA_ "CI_MsgDefinition" BO_ 2566805551 "J1939DA";
BA_ "CI_MsgId" BO_ 2566805551 33080;
BA_ "CI_MsgName" BO_ 2566805551 "ASC4_2F - Air Suspension Control 4";
BA_ "GenMsgCycleTime" BO_ 2566805551 100;
BA_ "GenMsgCycleTimeFast" BO_ 2566805551 100;
BA_ "GenMsgDelayTime" BO_ 2566805551 50;
BA_ "GenMsgSendType" BO_ 2566805551 0;
BA_ "GenMsgStartDelayTime" BO_ 2566805551 73;
BA_ "CI_MsgDefinition" BO_ 2148573190 "Iveco Daily Proprietary";
BA_ "CI_MsgId" BO_ 2148573190 43075;
BA_ "CI_MsgName" BO_ 2148573190 "ASR0 - ASR0";
BA_ "GenMsgCycleTime" BO_ 2148573190 50;
BA_ "GenMsgCycleTimeFast" BO_ 2148573190 50;
BA_ "GenMsgDelayTime" BO_ 2148573190 20;
BA_ "GenMsgSendType" BO_ 2148573190 0;
BA_ "GenMsgStartDelayTime" BO_ 2148573190 31;
BA_ "VFrameFormat" BO_ 2148573190 1;
BA_ "CI_MsgDefinition" BO_ 2566763008 "J1939DA";
BA_ "CI_MsgId" BO_ 2566763008 2369;
BA_ "CI_MsgName" BO_ 2566763008 "AT1IMG - Aftertreatment 1 Intermediate Gas";
BA_ "GenMsgCycleTime" BO_ 2566763008 500;
BA_ "GenMsgCycleTimeFast" BO_ 2566763008 500;
BA_ "GenMsgDelayTime" BO_ 2566763008 250;
BA_ "GenMsgSendType" BO_ 2566763008 0;
BA_ "GenMsgStartDelayTime" BO_ 2566763008 125;
BA_ "CI_MsgDefinition" BO_ 2566804992 "J1939DA";
BA_ "CI_MsgId" BO_ 2566804992 2412;
BA_ "CI_MsgName" BO_ 2566804992 "AT1T1I1 - Aftertreatment 1 Diesel Exhaust Fluid Tank 1 Information 1";
BA_ "GenMsgCycleTime" BO_ 2566804992 1000;
BA_ "GenMsgCycleTimeFast" BO_ 2566804992 1000;
BA_ "GenMsgDelayTime" BO_ 2566804992 500;
BA_ "GenMsgSendType" BO_ 2566804992 0;
BA_ "GenMsgStartDelayTime" BO_ 2566804992 179;
BA_ "CI_MsgDefinition" BO_ 2564685591 "J1939DA";
BA_ "CI_MsgId" BO_ 2564685591 2973;
BA_ "CI_MsgName" BO_ 2564685591 "ATR_17 - Anti-theft Request";
BA_ "CI_MsgDefinition" BO_ 2565144605 "FPT Proprietary";
BA_ "CI_MsgId" BO_ 2565144605 2957;
BA_ "CI_MsgName" BO_ 2565144605 "AtrFpt - Anti-theft Request";
BA_ "VFrameFormat" BO_ 2565144605 1;
BA_ "CI_MsgDefinition" BO_ 2565152000 "FPT Proprietary";
BA_ "CI_MsgId" BO_ 2565152000 2962;
BA_ "CI_MsgName" BO_ 2565152000 "AtsFpt - Anti-theft Status";
BA_ "VFrameFormat" BO_ 2565152000 1;
BA_ "CI_MsgDefinition" BO_ 2561146657 "Iveco Proprietary";
BA_ "CI_MsgId" BO_ 2561146657 6677;
BA_ "CI_MsgName" BO_ 2561146657 "AUXIO2_SW_21 - Auxiliary Input/Output Status 2 - Steering Wheel Commands";
BA_ "GenMsgCycleTime" BO_ 2561146657 1000;
BA_ "GenMsgCycleTimeFast" BO_ 2561146657 1000;
BA_ "GenMsgDelayTime" BO_ 2561146657 50;
BA_ "GenMsgNrOfRepetition" BO_ 2561146657 1;
BA_ "GenMsgSendType" BO_ 2561146657 0;
BA_ "GenMsgStartDelayTime" BO_ 2561146657 149;
BA_ "CI_MsgDefinition" BO_ 2566859292 "Iveco Proprietary";
BA_ "CI_MsgId" BO_ 2566859292 10159;
BA_ "CI_MsgName" BO_ 2566859292 "Av2_1_1C - ADASIS v2 (non-multiplexed) - POSITION Type ";
BA_ "GenMsgCycleTime" BO_ 2566859292 1000;
BA_ "GenMsgCycleTimeFast" BO_ 2566859292 1000;
BA_ "GenMsgDelayTime" BO_ 2566859292 500;
BA_ "GenMsgSendType" BO_ 2566859292 0;
BA_ "GenMsgStartDelayTime" BO_ 2566859292 22;
BA_ "CI_MsgDefinition" BO_ 2566859548 "Iveco Proprietary";
BA_ "CI_MsgId" BO_ 2566859548 10171;
BA_ "CI_MsgName" BO_ 2566859548 "Av2_2_1C - ADASIS v2 (non-multiplexed) - SEGMENT Type ";
BA_ "GenMsgDelayTime" BO_ 2566859548 100;
BA_ "CI_MsgDefinition" BO_ 2566859804 "Iveco Proprietary";
BA_ "CI_MsgId" BO_ 2566859804 10191;
BA_ "CI_MsgName" BO_ 2566859804 "Av2_3_1C - ADASIS v2 (non-multiplexed) - STUB Type ";
BA_ "GenMsgDelayTime" BO_ 2566859804 100;
BA_ "CI_MsgDefinition" BO_ 2566860060 "Iveco Proprietary";
BA_ "CI_MsgId" BO_ 2566860060 10209;
BA_ "CI_MsgName" BO_ 2566860060 "Av2_4_1C - ADASIS v2 (non-multiplexed) - PROFILE SHORT Type ";
BA_ "GenMsgDelayTime" BO_ 2566860060 100;
BA_ "CI_MsgDefinition" BO_ 2566860316 "Iveco Proprietary";
BA_ "CI_MsgId" BO_ 2566860316 10242;
BA_ "CI_MsgName" BO_ 2566860316 "Av2_5_1C - ADASIS v2 (non-multiplexed) - PROFILE LONG Type ";
BA_ "GenMsgDelayTime" BO_ 2566860316 100;
BA_ "CI_MsgDefinition" BO_ 2566860572 "Iveco Proprietary";
BA_ "CI_MsgId" BO_ 2566860572 10283;
BA_ "CI_MsgName" BO_ 2566860572 "Av2_6_1C - ADASIS v2 (non-multiplexed) - META-DATA Type ";
BA_ "GenMsgCycleTime" BO_ 2566860572 5000;
BA_ "GenMsgCycleTimeFast" BO_ 2566860572 5000;
BA_ "GenMsgDelayTime" BO_ 2566860572 2500;
BA_ "GenMsgSendType" BO_ 2566860572 0;
BA_ "GenMsgStartDelayTime" BO_ 2566860572 40;
BA_ "CI_MsgDefinition" BO_ 2283315200 "Iveco Daily Proprietary";
BA_ "CI_MsgId" BO_ 2283315200 43070;
BA_ "CI_MsgName" BO_ 2283315200 "BattInfo - Battery Info";
BA_ "GenMsgCycleTime" BO_ 2283315200 500;
BA_ "GenMsgCycleTimeFast" BO_ 2283315200 500;
BA_ "GenMsgDelayTime" BO_ 2283315200 250;
BA_ "GenMsgSendType" BO_ 2283315200 0;
BA_ "GenMsgStartDelayTime" BO_ 2283315200 123;
BA_ "VFrameFormat" BO_ 2283315200 1;
BA_ "CI_MsgDefinition" BO_ 2566886433 "Iveco Proprietary";
BA_ "CI_MsgId" BO_ 2566886433 44462;
BA_ "CI_MsgName" BO_ 2566886433 "BattInfo2 - Proprietary B - Battery Information 2";
BA_ "GenMsgCycleTime" BO_ 2566886433 1000;
BA_ "GenMsgCycleTimeFast" BO_ 2566886433 1000;
BA_ "GenMsgDelayTime" BO_ 2566886433 500;
BA_ "GenMsgSendType" BO_ 2566886433 0;
BA_ "GenMsgStartDelayTime" BO_ 2566886433 256;
BA_ "CI_MsgDefinition" BO_ 2566873377 "Iveco SPR1 Proprietary";
BA_ "CI_MsgId" BO_ 2566873377 11495;
BA_ "CI_MsgName" BO_ 2566873377 "Bc2Edc2 - BC2EDC2";
BA_ "GenMsgCycleTime" BO_ 2566873377 50;
BA_ "GenMsgCycleTimeFast" BO_ 2566873377 50;
BA_ "GenMsgDelayTime" BO_ 2566873377 25;
BA_ "GenMsgSendType" BO_ 2566873377 0;
BA_ "GenMsgStartDelayTime" BO_ 2566873377 45;
BA_ "CI_MsgDefinition" BO_ 2566722889 "J1939DA";
BA_ "CI_MsgId" BO_ 2566722889 33787;
BA_ "CI_MsgName" BO_ 2566722889 "BCH1_49 - Battery Charger 1";
BA_ "GenMsgCycleTime" BO_ 2566722889 1000;
BA_ "GenMsgCycleTimeFast" BO_ 2566722889 1000;
BA_ "GenMsgDelayTime" BO_ 2566722889 500;
BA_ "GenMsgSendType" BO_ 2566722889 0;
BA_ "GenMsgStartDelayTime" BO_ 2566722889 165;
BA_ "CI_MsgDefinition" BO_ 2566723351 "J1939DA";
BA_ "CI_MsgId" BO_ 2566723351 4403;
BA_ "CI_MsgName" BO_ 2566723351 "BDS_17 - Beltlock and Airbag Deactivation Switch Information";
BA_ "GenMsgCycleTime" BO_ 2566723351 250;
BA_ "GenMsgCycleTimeFast" BO_ 2566723351 250;
BA_ "GenMsgDelayTime" BO_ 2566723351 100;
BA_ "GenMsgSendType" BO_ 2566723351 0;
BA_ "GenMsgStartDelayTime" BO_ 2566723351 105;
BA_ "CI_MsgDefinition" BO_ 2566723361 "J1939DA";
BA_ "CI_MsgId" BO_ 2566723361 4405;
BA_ "CI_MsgName" BO_ 2566723361 "BDS_21 - Beltlock and Airbag Deactivation Switch Information";
BA_ "GenMsgCycleTime" BO_ 2566723361 250;
BA_ "GenMsgCycleTimeFast" BO_ 2566723361 250;
BA_ "GenMsgDelayTime" BO_ 2566723361 100;
BA_ "GenMsgSendType" BO_ 2566723361 0;
BA_ "GenMsgStartDelayTime" BO_ 2566723361 106;
BA_ "CI_ParId" SG_ 2565406709 Pgn_Ack_E8FFF5 "2543";
BA_ "CI_SigId" SG_ 2565406709 Pgn_Ack_E8FFF5 32929;
BA_ "CI_SigName" SG_ 2565406709 Pgn_Ack_E8FFF5 "Parameter Group Number (ACK)";
BA_ "SPN" SG_ 2565406709 Pgn_Ack_E8FFF5 2543;
BA_ "CI_ParId" SG_ 2565406709 Pgn_Nack_E8FFF5 "2545";
BA_ "CI_SigId" SG_ 2565406709 Pgn_Nack_E8FFF5 32930;
BA_ "CI_SigName" SG_ 2565406709 Pgn_Nack_E8FFF5 "Parameter Group Number (NACK)";
BA_ "SPN" SG_ 2565406709 Pgn_Nack_E8FFF5 2545;
BA_ "CI_ParId" SG_ 2565406709 Pgn_Ad_E8FFF5 "2547";
BA_ "CI_SigId" SG_ 2565406709 Pgn_Ad_E8FFF5 32931;
BA_ "CI_SigName" SG_ 2565406709 Pgn_Ad_E8FFF5 "Parameter Group Number (NACK_AD)";
BA_ "SPN" SG_ 2565406709 Pgn_Ad_E8FFF5 2547;
BA_ "CI_ParId" SG_ 2565406709 Pgn_Busy_E8FFF5 "2549";
BA_ "CI_SigId" SG_ 2565406709 Pgn_Busy_E8FFF5 32932;
BA_ "CI_SigName" SG_ 2565406709 Pgn_Busy_E8FFF5 "Parameter Group Number (NACK_Busy)";
BA_ "SPN" SG_ 2565406709 Pgn_Busy_E8FFF5 2549;
BA_ "CI_ParId" SG_ 2565406709 AddrAckd_E8FFF5 "3290";
BA_ "CI_SigId" SG_ 2565406709 AddrAckd_E8FFF5 32925;
BA_ "CI_SigName" SG_ 2565406709 AddrAckd_E8FFF5 "Address Acknowledged";
BA_ "SPN" SG_ 2565406709 AddrAckd_E8FFF5 3290;
BA_ "CI_ParId" SG_ 2565406709 AddrNack_E8FFF5 "3291";
BA_ "CI_SigId" SG_ 2565406709 AddrNack_E8FFF5 32926;
BA_ "CI_SigName" SG_ 2565406709 AddrNack_E8FFF5 "Address Negative Acknowledgement";
BA_ "SPN" SG_ 2565406709 AddrNack_E8FFF5 3291;
BA_ "CI_ParId" SG_ 2565406709 AddrAccessDenied_E8FFF5 "3292";
BA_ "CI_SigId" SG_ 2565406709 AddrAccessDenied_E8FFF5 32927;
BA_ "CI_SigName" SG_ 2565406709 AddrAccessDenied_E8FFF5 "Address Access Denied";
BA_ "SPN" SG_ 2565406709 AddrAccessDenied_E8FFF5 3292;
BA_ "CI_ParId" SG_ 2565406709 AddrBusy_E8FFF5 "3293";
BA_ "CI_SigId" SG_ 2565406709 AddrBusy_E8FFF5 32928;
BA_ "CI_SigName" SG_ 2565406709 AddrBusy_E8FFF5 "Address Busy";
BA_ "SPN" SG_ 2565406709 AddrBusy_E8FFF5 3293;
BA_ "CI_ParId" SG_ 2565406709 CtrlByte_Ackm_E8FFF5 "2541";
BA_ "CI_SigId" SG_ 2565406709 CtrlByte_Ackm_E8FFF5 32920;
BA_ "CI_SigName" SG_ 2565406709 CtrlByte_Ackm_E8FFF5 "Control Byte (ACKM)";
BA_ "SPN" SG_ 2565406709 CtrlByte_Ackm_E8FFF5 2541;
BA_ "CI_ParId" SG_ 2565406710 Pgn_Ack_E8FFF6 "2543";
BA_ "CI_SigId" SG_ 2565406710 Pgn_Ack_E8FFF6 32943;
BA_ "CI_SigName" SG_ 2565406710 Pgn_Ack_E8FFF6 "Parameter Group Number (ACK)";
BA_ "SPN" SG_ 2565406710 Pgn_Ack_E8FFF6 2543;
BA_ "CI_ParId" SG_ 2565406710 Pgn_Nack_E8FFF6 "2545";
BA_ "CI_SigId" SG_ 2565406710 Pgn_Nack_E8FFF6 32944;
BA_ "CI_SigName" SG_ 2565406710 Pgn_Nack_E8FFF6 "Parameter Group Number (NACK)";
BA_ "SPN" SG_ 2565406710 Pgn_Nack_E8FFF6 2545;
BA_ "CI_ParId" SG_ 2565406710 Pgn_Ad_E8FFF6 "2547";
BA_ "CI_SigId" SG_ 2565406710 Pgn_Ad_E8FFF6 32945;
BA_ "CI_SigName" SG_ 2565406710 Pgn_Ad_E8FFF6 "Parameter Group Number (NACK_AD)";
BA_ "SPN" SG_ 2565406710 Pgn_Ad_E8FFF6 2547;
BA_ "CI_ParId" SG_ 2565406710 Pgn_Busy_E8FFF6 "2549";
BA_ "CI_SigId" SG_ 2565406710 Pgn_Busy_E8FFF6 32946;
BA_ "CI_SigName" SG_ 2565406710 Pgn_Busy_E8FFF6 "Parameter Group Number (NACK_Busy)";
BA_ "SPN" SG_ 2565406710 Pgn_Busy_E8FFF6 2549;
BA_ "CI_ParId" SG_ 2565406710 AddrAckd_E8FFF6 "3290";
BA_ "CI_SigId" SG_ 2565406710 AddrAckd_E8FFF6 32939;
BA_ "CI_SigName" SG_ 2565406710 AddrAckd_E8FFF6 "Address Acknowledged";
BA_ "SPN" SG_ 2565406710 AddrAckd_E8FFF6 3290;
BA_ "CI_ParId" SG_ 2565406710 AddrNack_E8FFF6 "3291";
BA_ "CI_SigId" SG_ 2565406710 AddrNack_E8FFF6 32940;
BA_ "CI_SigName" SG_ 2565406710 AddrNack_E8FFF6 "Address Negative Acknowledgement";
BA_ "SPN" SG_ 2565406710 AddrNack_E8FFF6 3291;
BA_ "CI_ParId" SG_ 2565406710 AddrAccessDenied_E8FFF6 "3292";
BA_ "CI_SigId" SG_ 2565406710 AddrAccessDenied_E8FFF6 32941;
BA_ "CI_SigName" SG_ 2565406710 AddrAccessDenied_E8FFF6 "Address Access Denied";
BA_ "SPN" SG_ 2565406710 AddrAccessDenied_E8FFF6 3292;
BA_ "CI_ParId" SG_ 2565406710 AddrBusy_E8FFF6 "3293";
BA_ "CI_SigId" SG_ 2565406710 AddrBusy_E8FFF6 32942;
BA_ "CI_SigName" SG_ 2565406710 AddrBusy_E8FFF6 "Address Busy";
BA_ "SPN" SG_ 2565406710 AddrBusy_E8FFF6 3293;
BA_ "CI_ParId" SG_ 2565406710 CtrlByte_Ackm_E8FFF6 "2541";
BA_ "CI_SigId" SG_ 2565406710 CtrlByte_Ackm_E8FFF6 32934;
BA_ "CI_SigName" SG_ 2565406710 CtrlByte_Ackm_E8FFF6 "Control Byte (ACKM)";
BA_ "SPN" SG_ 2565406710 CtrlByte_Ackm_E8FFF6 2541;
BA_ "CI_ParId" SG_ 2364550954 TimeToCollWithRelvObj "5680";
BA_ "CI_SigId" SG_ 2364550954 TimeToCollWithRelvObj 861;
BA_ "CI_SigName" SG_ 2364550954 TimeToCollWithRelvObj "Time to collision with relevant object";
BA_ "GenSigSendType" SG_ 2364550954 TimeToCollWithRelvObj 3;
BA_ "GenSigTimeoutTime_PCM" SG_ 2364550954 TimeToCollWithRelvObj 500;
BA_ "SPN" SG_ 2364550954 TimeToCollWithRelvObj 5680;
BA_ "SigType" SG_ 2364550954 TimeToCollWithRelvObj 1;
BA_ "CI_ParId" SG_ 2364550954 RelvObjDetForAebs "5678";
BA_ "CI_SigId" SG_ 2364550954 RelvObjDetForAebs 43018;
BA_ "CI_SigName" SG_ 2364550954 RelvObjDetForAebs "Relevant object detected for advanced emergency braking system";
BA_ "GenSigSendType" SG_ 2364550954 RelvObjDetForAebs 3;
BA_ "GenSigTimeoutTime_PCM" SG_ 2364550954 RelvObjDetForAebs 500;
BA_ "SPN" SG_ 2364550954 RelvObjDetForAebs 5678;
BA_ "CI_ParId" SG_ 2364550954 CollWarnLev "5677";
BA_ "CI_SigId" SG_ 2364550954 CollWarnLev 858;
BA_ "CI_SigName" SG_ 2364550954 CollWarnLev "Collision warning level";
BA_ "GenSigSendType" SG_ 2364550954 CollWarnLev 3;
BA_ "GenSigTimeoutTime_PCM" SG_ 2364550954 CollWarnLev 500;
BA_ "SPN" SG_ 2364550954 CollWarnLev 5677;
BA_ "CI_ParId" SG_ 2364550954 AebsSts "5676";
BA_ "CI_SigId" SG_ 2364550954 AebsSts 857;
BA_ "CI_SigName" SG_ 2364550954 AebsSts "Forward Collision Advanced Emergency Braking System State";
BA_ "GenSigSendType" SG_ 2364550954 AebsSts 3;
BA_ "GenSigTimeoutTime_PCM" SG_ 2364550954 AebsSts 500;
BA_ "SPN" SG_ 2364550954 AebsSts 5676;
BA_ "CI_ParId" SG_ 2349541911 AebsSens "I376";
BA_ "CI_SigId" SG_ 2349541911 AebsSens 42826;
BA_ "CI_SigName" SG_ 2349541911 AebsSens "Advanced Emergency Braking System sensitivity";
BA_ "GenSigTimeoutTime_PCM" SG_ 2349541911 AebsSens 1250;
BA_ "CI_ParId" SG_ 2349541911 DistWarnCfg "ID2338";
BA_ "CI_SigId" SG_ 2349541911 DistWarnCfg 42825;
BA_ "CI_SigName" SG_ 2349541911 DistWarnCfg "Distance Warning Configuration";
BA_ "GenSigTimeoutTime_PCM" SG_ 2349541911 DistWarnCfg 1250;
BA_ "SigType" SG_ 2349541911 DistWarnCfg 4;
BA_ "CI_ParId" SG_ 2349541911 DrivActvDemForAebs "5681";
BA_ "CI_SigId" SG_ 2349541911 DrivActvDemForAebs 42824;
BA_ "CI_SigName" SG_ 2349541911 DrivActvDemForAebs "Driver activation demand for Advanced Emergency Braking System";
BA_ "GenSigTimeoutTime_PCM" SG_ 2349541911 DrivActvDemForAebs 1250;
BA_ "SPN" SG_ 2349541911 DrivActvDemForAebs 5681;
BA_ "SigType" SG_ 2349541911 DrivActvDemForAebs 4;
BA_ "CI_ParId" SG_ 2349537098 AebsSens_B174A "I376";
BA_ "CI_SigId" SG_ 2349537098 AebsSens_B174A 42832;
BA_ "CI_SigName" SG_ 2349537098 AebsSens_B174A "Advanced Emergency Braking System sensitivity";
BA_ "CI_ParId" SG_ 2349537098 DistWarnCfg_B174A "ID2338";
BA_ "CI_SigId" SG_ 2349537098 DistWarnCfg_B174A 42831;
BA_ "CI_SigName" SG_ 2349537098 DistWarnCfg_B174A "Distance Warning Configuration";
BA_ "SigType" SG_ 2349537098 DistWarnCfg_B174A 4;
BA_ "CI_ParId" SG_ 2349537098 DrivActvDemForAebs_B174A "5681";
BA_ "CI_SigId" SG_ 2349537098 DrivActvDemForAebs_B174A 42830;
BA_ "CI_SigName" SG_ 2349537098 DrivActvDemForAebs_B174A "Driver activation demand for Advanced Emergency Braking System";
BA_ "SPN" SG_ 2349537098 DrivActvDemForAebs_B174A 5681;
BA_ "SigType" SG_ 2349537098 DrivActvDemForAebs_B174A 4;
BA_ "CI_ParId" SG_ 2566845696 BaromPrs "108";
BA_ "CI_SigId" SG_ 2566845696 BaromPrs 2996;
BA_ "CI_SigName" SG_ 2566845696 BaromPrs "Barometric Pressure";
BA_ "GenSigTimeoutTime_PCM" SG_ 2566845696 BaromPrs 5000;
BA_ "SPN" SG_ 2566845696 BaromPrs 108;
BA_ "SigType" SG_ 2566845696 BaromPrs 1;
BA_ "CI_ParId" SG_ 2566845729 AmbAirTemp "171";
BA_ "CI_SigId" SG_ 2566845729 AmbAirTemp 3008;
BA_ "CI_SigName" SG_ 2566845729 AmbAirTemp "Ambient Air Temperature";
BA_ "GenSigTimeoutTime_PCM" SG_ 2566845729 AmbAirTemp 5000;
BA_ "SPN" SG_ 2566845729 AmbAirTemp 171;
BA_ "SigType" SG_ 2566845729 AmbAirTemp 1;
BA_ "CI_ParId" SG_ 2566774807 SolarIntensPc "2610";
BA_ "CI_SigId" SG_ 2566774807 SolarIntensPc 3013;
BA_ "CI_SigName" SG_ 2566774807 SolarIntensPc "Solar Intensity Percent";
BA_ "GenSigTimeoutTime_PCM" SG_ 2566774807 SolarIntensPc 5000;
BA_ "SPN" SG_ 2566774807 SolarIntensPc 2610;
BA_ "SigType" SG_ 2566774807 SolarIntensPc 1;
BA_ "CI_ParId" SG_ 2566837537 Altern1Sts "3353";
BA_ "CI_SigId" SG_ 2566837537 Altern1Sts 3527;
BA_ "CI_SigName" SG_ 2566837537 Altern1Sts "Alternator 1 Status";
BA_ "GenSigSendType" SG_ 2566837537 Altern1Sts 3;
BA_ "GenSigTimeoutTime_PCM" SG_ 2566837537 Altern1Sts 5000;
BA_ "SPN" SG_ 2566837537 Altern1Sts 3353;
BA_ "SigType" SG_ 2566837537 Altern1Sts 4;
BA_ "CI_ParId" SG_ 2365479471 SuspCtrlRefusalInfo "1827";
BA_ "CI_SigId" SG_ 2365479471 SuspCtrlRefusalInfo 33074;
BA_ "CI_SigName" SG_ 2365479471 SuspCtrlRefusalInfo "Suspension Control Refusal Information";
BA_ "GenSigTimeoutTime_PCM" SG_ 2365479471 SuspCtrlRefusalInfo 500;
BA_ "SPN" SG_ 2365479471 SuspCtrlRefusalInfo 1827;
BA_ "CI_ParId" SG_ 2365479471 SpeedDepLevCtrlSts "5296";
BA_ "CI_SigId" SG_ 2365479471 SpeedDepLevCtrlSts 33073;
BA_ "CI_SigName" SG_ 2365479471 SpeedDepLevCtrlSts "Speed Dependant Level Control Status";
BA_ "GenSigTimeoutTime_PCM" SG_ 2365479471 SpeedDepLevCtrlSts 500;
BA_ "SPN" SG_ 2365479471 SpeedDepLevCtrlSts 5296;
BA_ "SigType" SG_ 2365479471 SpeedDepLevCtrlSts 4;
BA_ "CI_ParId" SG_ 2365479471 AllowLevCtrlDurBrkSts "5294";
BA_ "CI_SigId" SG_ 2365479471 AllowLevCtrlDurBrkSts 33072;
BA_ "CI_SigName" SG_ 2365479471 AllowLevCtrlDurBrkSts "Allow Level Control During Braking Status";
BA_ "GenSigTimeoutTime_PCM" SG_ 2365479471 AllowLevCtrlDurBrkSts 500;
BA_ "SPN" SG_ 2365479471 AllowLevCtrlDurBrkSts 5294;
BA_ "SigType" SG_ 2365479471 AllowLevCtrlDurBrkSts 4;
BA_ "CI_ParId" SG_ 2365479471 SuspRemCtrl2 "1825";
BA_ "CI_SigId" SG_ 2365479471 SuspRemCtrl2 33071;
BA_ "CI_SigName" SG_ 2365479471 SuspRemCtrl2 "Suspension Remote control 2";
BA_ "GenSigTimeoutTime_PCM" SG_ 2365479471 SuspRemCtrl2 500;
BA_ "SPN" SG_ 2365479471 SuspRemCtrl2 1825;
BA_ "SigType" SG_ 2365479471 SuspRemCtrl2 4;
BA_ "CI_ParId" SG_ 2365479471 SuspRemCtrl1 "1826";
BA_ "CI_SigId" SG_ 2365479471 SuspRemCtrl1 33070;
BA_ "CI_SigName" SG_ 2365479471 SuspRemCtrl1 "Suspension Remote Control 1";
BA_ "GenSigTimeoutTime_PCM" SG_ 2365479471 SuspRemCtrl1 500;
BA_ "SPN" SG_ 2365479471 SuspRemCtrl1 1826;
BA_ "SigType" SG_ 2365479471 SuspRemCtrl1 4;
BA_ "CI_ParId" SG_ 2365479471 LiftA2Pos "1822";
BA_ "CI_SigId" SG_ 2365479471 LiftA2Pos 33069;
BA_ "CI_SigName" SG_ 2365479471 LiftA2Pos "Lift Axle 2 Position";
BA_ "GenSigTimeoutTime_PCM" SG_ 2365479471 LiftA2Pos 500;
BA_ "SPN" SG_ 2365479471 LiftA2Pos 1822;
BA_ "SigType" SG_ 2365479471 LiftA2Pos 4;
BA_ "CI_ParId" SG_ 2365479471 RaInBumperRng "1823";
BA_ "CI_SigId" SG_ 2365479471 RaInBumperRng 33068;
BA_ "CI_SigName" SG_ 2365479471 RaInBumperRng "Rear Axle in Bumper Range";
BA_ "GenSigTimeoutTime_PCM" SG_ 2365479471 RaInBumperRng 500;
BA_ "SPN" SG_ 2365479471 RaInBumperRng 1823;
BA_ "SigType" SG_ 2365479471 RaInBumperRng 4;
BA_ "CI_ParId" SG_ 2365479471 FaInBumperRng "1824";
BA_ "CI_SigId" SG_ 2365479471 FaInBumperRng 33067;
BA_ "CI_SigName" SG_ 2365479471 FaInBumperRng "Front Axle in Bumper Range";
BA_ "GenSigTimeoutTime_PCM" SG_ 2365479471 FaInBumperRng 500;
BA_ "SPN" SG_ 2365479471 FaInBumperRng 1824;
BA_ "SigType" SG_ 2365479471 FaInBumperRng 4;
BA_ "CI_ParId" SG_ 2365479471 LiftA1Pos "1743";
BA_ "CI_SigId" SG_ 2365479471 LiftA1Pos 33066;
BA_ "CI_SigName" SG_ 2365479471 LiftA1Pos "Lift Axle 1 Position";
BA_ "GenSigTimeoutTime_PCM" SG_ 2365479471 LiftA1Pos 500;
BA_ "SPN" SG_ 2365479471 LiftA1Pos 1743;
BA_ "SigType" SG_ 2365479471 LiftA1Pos 4;
BA_ "CI_ParId" SG_ 2365479471 DoorRels "1744";
BA_ "CI_SigId" SG_ 2365479471 DoorRels 33065;
BA_ "CI_SigName" SG_ 2365479471 DoorRels "Door Release";
BA_ "GenSigTimeoutTime_PCM" SG_ 2365479471 DoorRels 500;
BA_ "SPN" SG_ 2365479471 DoorRels 1744;
BA_ "SigType" SG_ 2365479471 DoorRels 4;
BA_ "CI_ParId" SG_ 2365479471 VehMotInh "1745";
BA_ "CI_SigId" SG_ 2365479471 VehMotInh 33064;
BA_ "CI_SigName" SG_ 2365479471 VehMotInh "Vehicle Motion Inhibit";
BA_ "GenSigTimeoutTime_PCM" SG_ 2365479471 VehMotInh 500;
BA_ "SPN" SG_ 2365479471 VehMotInh 1745;
BA_ "SigType" SG_ 2365479471 VehMotInh 4;
BA_ "CI_ParId" SG_ 2365479471 SecurDev "1746";
BA_ "CI_SigId" SG_ 2365479471 SecurDev 33063;
BA_ "CI_SigName" SG_ 2365479471 SecurDev "Security Device";
BA_ "GenSigTimeoutTime_PCM" SG_ 2365479471 SecurDev 500;
BA_ "SPN" SG_ 2365479471 SecurDev 1746;
BA_ "SigType" SG_ 2365479471 SecurDev 4;
BA_ "CI_ParId" SG_ 2365479471 LevCtrlMode "1741";
BA_ "CI_SigId" SG_ 2365479471 LevCtrlMode 33062;
BA_ "CI_SigName" SG_ 2365479471 LevCtrlMode "Level Control Mode";
BA_ "GenSigTimeoutTime_PCM" SG_ 2365479471 LevCtrlMode 500;
BA_ "SPN" SG_ 2365479471 LevCtrlMode 1741;
BA_ "CI_ParId" SG_ 2365479471 KneelInfo "1742";
BA_ "CI_SigId" SG_ 2365479471 KneelInfo 33061;
BA_ "CI_SigName" SG_ 2365479471 KneelInfo "Kneeling Information";
BA_ "GenSigTimeoutTime_PCM" SG_ 2365479471 KneelInfo 500;
BA_ "SPN" SG_ 2365479471 KneelInfo 1742;
BA_ "CI_ParId" SG_ 2365479471 LiftCtrlModeRa "1756";
BA_ "CI_SigId" SG_ 2365479471 LiftCtrlModeRa 33060;
BA_ "CI_SigName" SG_ 2365479471 LiftCtrlModeRa "Lifting Control Mode Rear Axle";
BA_ "GenSigTimeoutTime_PCM" SG_ 2365479471 LiftCtrlModeRa 500;
BA_ "SPN" SG_ 2365479471 LiftCtrlModeRa 1756;
BA_ "SigType" SG_ 2365479471 LiftCtrlModeRa 4;
BA_ "CI_ParId" SG_ 2365479471 LiftCtrlModeFa "1739";
BA_ "CI_SigId" SG_ 2365479471 LiftCtrlModeFa 33059;
BA_ "CI_SigName" SG_ 2365479471 LiftCtrlModeFa "Lifting Control Mode Front Axle";
BA_ "GenSigTimeoutTime_PCM" SG_ 2365479471 LiftCtrlModeFa 500;
BA_ "SPN" SG_ 2365479471 LiftCtrlModeFa 1739;
BA_ "SigType" SG_ 2365479471 LiftCtrlModeFa 4;
BA_ "CI_ParId" SG_ 2365479471 LowCtrlModeRa "1755";
BA_ "CI_SigId" SG_ 2365479471 LowCtrlModeRa 33058;
BA_ "CI_SigName" SG_ 2365479471 LowCtrlModeRa "Lowering Control Mode Rear Axle";
BA_ "GenSigTimeoutTime_PCM" SG_ 2365479471 LowCtrlModeRa 500;
BA_ "SPN" SG_ 2365479471 LowCtrlModeRa 1755;
BA_ "SigType" SG_ 2365479471 LowCtrlModeRa 4;
BA_ "CI_ParId" SG_ 2365479471 LowCtrlModeFa "1740";
BA_ "CI_SigId" SG_ 2365479471 LowCtrlModeFa 33057;
BA_ "CI_SigName" SG_ 2365479471 LowCtrlModeFa "Lowering Control Mode Front Axle";
BA_ "GenSigTimeoutTime_PCM" SG_ 2365479471 LowCtrlModeFa 500;
BA_ "SPN" SG_ 2365479471 LowCtrlModeFa 1740;
BA_ "SigType" SG_ 2365479471 LowCtrlModeFa 4;
BA_ "CI_ParId" SG_ 2365479471 AbvNomLevRa "1736";
BA_ "CI_SigId" SG_ 2365479471 AbvNomLevRa 33056;
BA_ "CI_SigName" SG_ 2365479471 AbvNomLevRa "Above Nominal Level Rear Axle";
BA_ "GenSigTimeoutTime_PCM" SG_ 2365479471 AbvNomLevRa 500;
BA_ "SPN" SG_ 2365479471 AbvNomLevRa 1736;
BA_ "SigType" SG_ 2365479471 AbvNomLevRa 4;
BA_ "CI_ParId" SG_ 2365479471 AbvNomLevFa "1737";
BA_ "CI_SigId" SG_ 2365479471 AbvNomLevFa 33055;
BA_ "CI_SigName" SG_ 2365479471 AbvNomLevFa "Above Nominal Level Front Axle";
BA_ "GenSigTimeoutTime_PCM" SG_ 2365479471 AbvNomLevFa 500;
BA_ "SPN" SG_ 2365479471 AbvNomLevFa 1737;
BA_ "SigType" SG_ 2365479471 AbvNomLevFa 4;
BA_ "CI_ParId" SG_ 2365479471 BlwNomLevRa "1754";
BA_ "CI_SigId" SG_ 2365479471 BlwNomLevRa 33054;
BA_ "CI_SigName" SG_ 2365479471 BlwNomLevRa "Below Nominal Level Rear Axle";
BA_ "GenSigTimeoutTime_PCM" SG_ 2365479471 BlwNomLevRa 500;
BA_ "SPN" SG_ 2365479471 BlwNomLevRa 1754;
BA_ "SigType" SG_ 2365479471 BlwNomLevRa 4;
BA_ "CI_ParId" SG_ 2365479471 BlwNomLevFa "1738";
BA_ "CI_SigId" SG_ 2365479471 BlwNomLevFa 33053;
BA_ "CI_SigName" SG_ 2365479471 BlwNomLevFa "Below Nominal Level Front Axle";
BA_ "GenSigTimeoutTime_PCM" SG_ 2365479471 BlwNomLevFa 500;
BA_ "SPN" SG_ 2365479471 BlwNomLevFa 1738;
BA_ "SigType" SG_ 2365479471 BlwNomLevFa 4;
BA_ "CI_ParId" SG_ 2365479471 NomLevRa "1733";
BA_ "CI_SigId" SG_ 2365479471 NomLevRa 33052;
BA_ "CI_SigName" SG_ 2365479471 NomLevRa "Nominal Level Rear Axle";
BA_ "GenSigTimeoutTime_PCM" SG_ 2365479471 NomLevRa 500;
BA_ "SPN" SG_ 2365479471 NomLevRa 1733;
BA_ "CI_ParId" SG_ 2365479471 NomLevFa "1734";
BA_ "CI_SigId" SG_ 2365479471 NomLevFa 33051;
BA_ "CI_SigName" SG_ 2365479471 NomLevFa "Nominal Level Front Axle";
BA_ "GenSigTimeoutTime_PCM" SG_ 2365479471 NomLevFa 500;
BA_ "SPN" SG_ 2365479471 NomLevFa 1734;
BA_ "CI_ParId" SG_ 2362584906 ProhibitAirSuspCtrl "3215";
BA_ "CI_SigId" SG_ 2362584906 ProhibitAirSuspCtrl 33116;
BA_ "CI_SigName" SG_ 2362584906 ProhibitAirSuspCtrl "Prohibit air suspension control";
BA_ "GenSigTimeoutTime_SGW" SG_ 2362584906 ProhibitAirSuspCtrl 500;
BA_ "SPN" SG_ 2362584906 ProhibitAirSuspCtrl 3215;
BA_ "SigType" SG_ 2362584906 ProhibitAirSuspCtrl 4;
BA_ "CI_ParId" SG_ 2362584906 KneelCmdRa "1829";
BA_ "CI_SigId" SG_ 2362584906 KneelCmdRa 33115;
BA_ "CI_SigName" SG_ 2362584906 KneelCmdRa "Kneeling Command - Rear Axle";
BA_ "GenSigTimeoutTime_SGW" SG_ 2362584906 KneelCmdRa 500;
BA_ "SPN" SG_ 2362584906 KneelCmdRa 1829;
BA_ "SigType" SG_ 2362584906 KneelCmdRa 4;
BA_ "CI_ParId" SG_ 2362584906 KneelCmdFa "1830";
BA_ "CI_SigId" SG_ 2362584906 KneelCmdFa 33114;
BA_ "CI_SigName" SG_ 2362584906 KneelCmdFa "Kneeling Command - Front Axle";
BA_ "GenSigTimeoutTime_SGW" SG_ 2362584906 KneelCmdFa 500;
BA_ "SPN" SG_ 2362584906 KneelCmdFa 1830;
BA_ "SigType" SG_ 2362584906 KneelCmdFa 4;
BA_ "CI_ParId" SG_ 2362584906 DampStiffReqLift_TagAxle "1720";
BA_ "CI_SigId" SG_ 2362584906 DampStiffReqLift_TagAxle 33113;
BA_ "CI_SigName" SG_ 2362584906 DampStiffReqLift_TagAxle "Damper Stiffness Request Lift / Tag Axle";
BA_ "GenSigTimeoutTime_SGW" SG_ 2362584906 DampStiffReqLift_TagAxle 500;
BA_ "SPN" SG_ 2362584906 DampStiffReqLift_TagAxle 1720;
BA_ "SigType" SG_ 2362584906 DampStiffReqLift_TagAxle 1;
BA_ "CI_ParId" SG_ 2362584906 DampStiffReqRa "1719";
BA_ "CI_SigId" SG_ 2362584906 DampStiffReqRa 33112;
BA_ "CI_SigName" SG_ 2362584906 DampStiffReqRa "Damper Stiffness Request Rear Axle";
BA_ "GenSigTimeoutTime_SGW" SG_ 2362584906 DampStiffReqRa 500;
BA_ "SPN" SG_ 2362584906 DampStiffReqRa 1719;
BA_ "SigType" SG_ 2362584906 DampStiffReqRa 1;
BA_ "CI_ParId" SG_ 2362584906 DampStiffReqFa "1718";
BA_ "CI_SigId" SG_ 2362584906 DampStiffReqFa 33111;
BA_ "CI_SigName" SG_ 2362584906 DampStiffReqFa "Damper Stiffness Request Front Axle";
BA_ "GenSigTimeoutTime_SGW" SG_ 2362584906 DampStiffReqFa 500;
BA_ "SPN" SG_ 2362584906 DampStiffReqFa 1718;
BA_ "SigType" SG_ 2362584906 DampStiffReqFa 1;
BA_ "CI_ParId" SG_ 2362584906 LiftA2PosCmd "1828";
BA_ "CI_SigId" SG_ 2362584906 LiftA2PosCmd 33110;
BA_ "CI_SigName" SG_ 2362584906 LiftA2PosCmd "Lift Axle 2 Position Command";
BA_ "GenSigTimeoutTime_SGW" SG_ 2362584906 LiftA2PosCmd 500;
BA_ "SPN" SG_ 2362584906 LiftA2PosCmd 1828;
BA_ "SigType" SG_ 2362584906 LiftA2PosCmd 4;
BA_ "CI_ParId" SG_ 2362584906 LiftA1PosCmd "1752";
BA_ "CI_SigId" SG_ 2362584906 LiftA1PosCmd 33109;
BA_ "CI_SigName" SG_ 2362584906 LiftA1PosCmd "Lift Axle 1 Position Command";
BA_ "GenSigTimeoutTime_SGW" SG_ 2362584906 LiftA1PosCmd 500;
BA_ "SPN" SG_ 2362584906 LiftA1PosCmd 1752;
BA_ "SigType" SG_ 2362584906 LiftA1PosCmd 4;
BA_ "CI_ParId" SG_ 2362584906 LevCtrlModeReq "1753";
BA_ "CI_SigId" SG_ 2362584906 LevCtrlModeReq 33108;
BA_ "CI_SigName" SG_ 2362584906 LevCtrlModeReq "Level Control Mode Request";
BA_ "GenSigTimeoutTime_SGW" SG_ 2362584906 LevCtrlModeReq 500;
BA_ "SPN" SG_ 2362584906 LevCtrlModeReq 1753;
BA_ "CI_ParId" SG_ 2362584906 NomLevReqRa "1750";
BA_ "CI_SigId" SG_ 2362584906 NomLevReqRa 33107;
BA_ "CI_SigName" SG_ 2362584906 NomLevReqRa "Nominal Level Request Rear Axle";
BA_ "GenSigTimeoutTime_SGW" SG_ 2362584906 NomLevReqRa 500;
BA_ "SPN" SG_ 2362584906 NomLevReqRa 1750;
BA_ "CI_ParId" SG_ 2362584906 NomLevReqFa "1751";
BA_ "CI_SigId" SG_ 2362584906 NomLevReqFa 33106;
BA_ "CI_SigName" SG_ 2362584906 NomLevReqFa "Nominal Level Request Front Axle";
BA_ "GenSigTimeoutTime_SGW" SG_ 2362584906 NomLevReqFa 500;
BA_ "SPN" SG_ 2362584906 NomLevReqFa 1751;
BA_ "CI_ParId" SG_ 2362584906 KneelCtrlModeReq "1747";
BA_ "CI_SigId" SG_ 2362584906 KneelCtrlModeReq 33105;
BA_ "CI_SigName" SG_ 2362584906 KneelCtrlModeReq "Kneeling Control Mode Request";
BA_ "GenSigTimeoutTime_SGW" SG_ 2362584906 KneelCtrlModeReq 500;
BA_ "SPN" SG_ 2362584906 KneelCtrlModeReq 1747;
BA_ "SigType" SG_ 2362584906 KneelCtrlModeReq 4;
BA_ "CI_ParId" SG_ 2362584906 KneelReqRh "1748";
BA_ "CI_SigId" SG_ 2362584906 KneelReqRh 33104;
BA_ "CI_SigName" SG_ 2362584906 KneelReqRh "Kneeling Request Right Side";
BA_ "GenSigTimeoutTime_SGW" SG_ 2362584906 KneelReqRh 500;
BA_ "SPN" SG_ 2362584906 KneelReqRh 1748;
BA_ "SigType" SG_ 2362584906 KneelReqRh 4;
BA_ "CI_ParId" SG_ 2362584906 KneelReqLh "1749";
BA_ "CI_SigId" SG_ 2362584906 KneelReqLh 33103;
BA_ "CI_SigName" SG_ 2362584906 KneelReqLh "Kneeling Request Left Side";
BA_ "GenSigTimeoutTime_SGW" SG_ 2362584906 KneelReqLh 500;
BA_ "SPN" SG_ 2362584906 KneelReqLh 1749;
BA_ "SigType" SG_ 2362584906 KneelReqLh 4;
BA_ "CI_ParId" SG_ 2362584906 AutoTractHelp "2984";
BA_ "CI_SigId" SG_ 2362584906 AutoTractHelp 33102;
BA_ "CI_SigName" SG_ 2362584906 AutoTractHelp "Automatic traction help (load transfer)";
BA_ "GenSigTimeoutTime_SGW" SG_ 2362584906 AutoTractHelp 500;
BA_ "SPN" SG_ 2362584906 AutoTractHelp 2984;
BA_ "SigType" SG_ 2362584906 AutoTractHelp 4;
BA_ "CI_ParId" SG_ 2566805807 RelLevRaR "1723";
BA_ "CI_SigId" SG_ 2566805807 RelLevRaR 33079;
BA_ "CI_SigName" SG_ 2566805807 RelLevRaR "Relative Level Rear Axle Right";
BA_ "GenSigTimeoutTime_PCM" SG_ 2566805807 RelLevRaR 500;
BA_ "SPN" SG_ 2566805807 RelLevRaR 1723;
BA_ "SigType" SG_ 2566805807 RelLevRaR 1;
BA_ "CI_ParId" SG_ 2566805807 RelLevRaL "1724";
BA_ "CI_SigId" SG_ 2566805807 RelLevRaL 33078;
BA_ "CI_SigName" SG_ 2566805807 RelLevRaL "Relative Level Rear Axle Left";
BA_ "GenSigTimeoutTime_PCM" SG_ 2566805807 RelLevRaL 500;
BA_ "SPN" SG_ 2566805807 RelLevRaL 1724;
BA_ "SigType" SG_ 2566805807 RelLevRaL 1;
BA_ "CI_ParId" SG_ 2566805807 RelLevFaR "1722";
BA_ "CI_SigId" SG_ 2566805807 RelLevFaR 33077;
BA_ "CI_SigName" SG_ 2566805807 RelLevFaR "Relative Level Front Axle Right";
BA_ "GenSigTimeoutTime_PCM" SG_ 2566805807 RelLevFaR 500;
BA_ "SPN" SG_ 2566805807 RelLevFaR 1722;
BA_ "SigType" SG_ 2566805807 RelLevFaR 1;
BA_ "CI_ParId" SG_ 2566805807 RelLevFaL "1721";
BA_ "CI_SigId" SG_ 2566805807 RelLevFaL 33076;
BA_ "CI_SigName" SG_ 2566805807 RelLevFaL "Relative Level Front Axle Left";
BA_ "GenSigTimeoutTime_PCM" SG_ 2566805807 RelLevFaL 500;
BA_ "SPN" SG_ 2566805807 RelLevFaL 1721;
BA_ "SigType" SG_ 2566805807 RelLevFaL 1;
BA_ "CI_ParId" SG_ 2566805551 BellowPrsRaR "1728";
BA_ "CI_SigId" SG_ 2566805551 BellowPrsRaR 33084;
BA_ "CI_SigName" SG_ 2566805551 BellowPrsRaR "Bellow Pressure Rear Axle Right";
BA_ "GenSigTimeoutTime_PCM" SG_ 2566805551 BellowPrsRaR 500;
BA_ "SPN" SG_ 2566805551 BellowPrsRaR 1728;
BA_ "SigType" SG_ 2566805551 BellowPrsRaR 1;
BA_ "CI_ParId" SG_ 2566805551 BellowPrsRaL "1727";
BA_ "CI_SigId" SG_ 2566805551 BellowPrsRaL 33083;
BA_ "CI_SigName" SG_ 2566805551 BellowPrsRaL "Bellow Pressure Rear Axle Left";
BA_ "GenSigTimeoutTime_PCM" SG_ 2566805551 BellowPrsRaL 500;
BA_ "SPN" SG_ 2566805551 BellowPrsRaL 1727;
BA_ "SigType" SG_ 2566805551 BellowPrsRaL 1;
BA_ "CI_ParId" SG_ 2566805551 BellowPrsFaR "1726";
BA_ "CI_SigId" SG_ 2566805551 BellowPrsFaR 33082;
BA_ "CI_SigName" SG_ 2566805551 BellowPrsFaR "Bellow Pressure Front Axle Right";
BA_ "GenSigTimeoutTime_PCM" SG_ 2566805551 BellowPrsFaR 500;
BA_ "SPN" SG_ 2566805551 BellowPrsFaR 1726;
BA_ "SigType" SG_ 2566805551 BellowPrsFaR 1;
BA_ "CI_ParId" SG_ 2566805551 BellowPrsFaL "1725";
BA_ "CI_SigId" SG_ 2566805551 BellowPrsFaL 33081;
BA_ "CI_SigName" SG_ 2566805551 BellowPrsFaL "Bellow Pressure Front Axle Left";
BA_ "GenSigTimeoutTime_PCM" SG_ 2566805551 BellowPrsFaL 500;
BA_ "SPN" SG_ 2566805551 BellowPrsFaL 1725;
BA_ "SigType" SG_ 2566805551 BellowPrsFaL 1;
BA_ "CI_ParId" SG_ 2148573190 PrefillActv "ID0020";
BA_ "CI_SigId" SG_ 2148573190 PrefillActv 29451;
BA_ "CI_SigName" SG_ 2148573190 PrefillActv "Prefill Active";
BA_ "GenSigSendType" SG_ 2148573190 PrefillActv 3;
BA_ "GenSigTimeoutTime_PCM" SG_ 2148573190 PrefillActv 500;
BA_ "CI_ParId" SG_ 2148573190 HbaActv "ID0016";
BA_ "CI_SigId" SG_ 2148573190 HbaActv 29447;
BA_ "CI_SigName" SG_ 2148573190 HbaActv "HBA Active";
BA_ "GenSigSendType" SG_ 2148573190 HbaActv 3;
BA_ "GenSigTimeoutTime_PCM" SG_ 2148573190 HbaActv 500;
BA_ "CI_ParId" SG_ 2148573190 TtcActv "ID0017";
BA_ "CI_SigId" SG_ 2148573190 TtcActv 29448;
BA_ "CI_SigName" SG_ 2148573190 TtcActv "TTC Active";
BA_ "GenSigSendType" SG_ 2148573190 TtcActv 3;
BA_ "GenSigTimeoutTime_PCM" SG_ 2148573190 TtcActv 500;
BA_ "CI_ParId" SG_ 2148573190 HhActv "ID0018";
BA_ "CI_SigId" SG_ 2148573190 HhActv 29449;
BA_ "CI_SigName" SG_ 2148573190 HhActv "Hill Holder Active";
BA_ "GenSigSendType" SG_ 2148573190 HhActv 3;
BA_ "GenSigTimeoutTime_PCM" SG_ 2148573190 HhActv 500;
BA_ "CI_ParId" SG_ 2148573190 GearShiftReq "ID2223";
BA_ "CI_SigId" SG_ 2148573190 GearShiftReq 43963;
BA_ "CI_SigName" SG_ 2148573190 GearShiftReq "Gear Shift Request";
BA_ "GenSigSendType" SG_ 2148573190 GearShiftReq 3;
BA_ "GenSigTimeoutTime_PCM" SG_ 2148573190 GearShiftReq 500;
BA_ "CI_ParId" SG_ 2148573190 MasterCylPrs "ID0006";
BA_ "CI_SigId" SG_ 2148573190 MasterCylPrs 29437;
BA_ "CI_SigName" SG_ 2148573190 MasterCylPrs "Master Cylinder Pressure (unfiltered)";
BA_ "GenSigSendType" SG_ 2148573190 MasterCylPrs 3;
BA_ "GenSigTimeoutTime_PCM" SG_ 2148573190 MasterCylPrs 500;
BA_ "CI_ParId" SG_ 2148573190 MasterCylPrsValData "ID0007";
BA_ "CI_SigId" SG_ 2148573190 MasterCylPrsValData 29438;
BA_ "CI_SigName" SG_ 2148573190 MasterCylPrsValData "Master Cylinder Pressure Valid Data";
BA_ "GenSigSendType" SG_ 2148573190 MasterCylPrsValData 3;
BA_ "GenSigTimeoutTime_PCM" SG_ 2148573190 MasterCylPrsValData 500;
BA_ "CI_ParId" SG_ 2148573190 VdcShiftInterf "ID0001";
BA_ "CI_SigId" SG_ 2148573190 VdcShiftInterf 29432;
BA_ "CI_SigName" SG_ 2148573190 VdcShiftInterf "VDC Shift Interference";
BA_ "GenSigSendType" SG_ 2148573190 VdcShiftInterf 3;
BA_ "GenSigTimeoutTime_PCM" SG_ 2148573190 VdcShiftInterf 500;
BA_ "CI_ParId" SG_ 2148573190 VdcShiftInterfValData "ID0002";
BA_ "CI_SigId" SG_ 2148573190 VdcShiftInterfValData 29433;
BA_ "CI_SigName" SG_ 2148573190 VdcShiftInterfValData "VDC Shift Interference Valid Data";
BA_ "GenSigSendType" SG_ 2148573190 VdcShiftInterfValData 3;
BA_ "GenSigTimeoutTime_PCM" SG_ 2148573190 VdcShiftInterfValData 500;
BA_ "CI_ParId" SG_ 2148573190 AsrCtrlSts "ID0005";
BA_ "CI_SigId" SG_ 2148573190 AsrCtrlSts 29436;
BA_ "CI_SigName" SG_ 2148573190 AsrCtrlSts "ASR Control Status";
BA_ "GenSigSendType" SG_ 2148573190 AsrCtrlSts 3;
BA_ "GenSigTimeoutTime_PCM" SG_ 2148573190 AsrCtrlSts 500;
BA_ "CI_ParId" SG_ 2566763008 At1DpfDiffPrs "3251";
BA_ "CI_SigId" SG_ 2566763008 At1DpfDiffPrs 2372;
BA_ "CI_SigName" SG_ 2566763008 At1DpfDiffPrs "Aftertreatment 1 Diesel Particulate Filter Differential Pressure";
BA_ "GenSigTimeoutTime_PCM" SG_ 2566763008 At1DpfDiffPrs 2500;
BA_ "SPN" SG_ 2566763008 At1DpfDiffPrs 3251;
BA_ "SigType" SG_ 2566763008 At1DpfDiffPrs 1;
BA_ "CI_ParId" SG_ 2566804992 AtScrOpInducSev "5246";
BA_ "CI_SigId" SG_ 2566804992 AtScrOpInducSev 2419;
BA_ "CI_SigName" SG_ 2566804992 AtScrOpInducSev "Aftertreatment SCR Operator Inducement Severity";
BA_ "GenSigTimeoutTime_PCM" SG_ 2566804992 AtScrOpInducSev 5000;
BA_ "SPN" SG_ 2566804992 AtScrOpInducSev 5246;
BA_ "CI_ParId" SG_ 2566804992 AtDefTankLowLevInd "5245";
BA_ "CI_SigId" SG_ 2566804992 AtDefTankLowLevInd 2417;
BA_ "CI_SigName" SG_ 2566804992 AtDefTankLowLevInd "Aftertreatment Diesel Exhaust Fluid Tank Low Level Indicator";
BA_ "GenSigTimeoutTime_PCM" SG_ 2566804992 AtDefTankLowLevInd 5000;
BA_ "SPN" SG_ 2566804992 AtDefTankLowLevInd 5245;
BA_ "CI_ParId" SG_ 2566804992 At1DefTankTemp1 "3031";
BA_ "CI_SigId" SG_ 2566804992 At1DefTankTemp1 2414;
BA_ "CI_SigName" SG_ 2566804992 At1DefTankTemp1 "Aftertreatment 1 Diesel Exhaust Fluid Tank Temperature 1";
BA_ "GenSigTimeoutTime_PCM" SG_ 2566804992 At1DefTankTemp1 5000;
BA_ "SPN" SG_ 2566804992 At1DefTankTemp1 3031;
BA_ "SigType" SG_ 2566804992 At1DefTankTemp1 1;
BA_ "CI_ParId" SG_ 2566804992 At1DefTankVol "1761";
BA_ "CI_SigId" SG_ 2566804992 At1DefTankVol 2413;
BA_ "CI_SigName" SG_ 2566804992 At1DefTankVol "Aftertreatment 1 Diesel Exhaust Fluid Tank Volume";
BA_ "GenSigTimeoutTime_PCM" SG_ 2566804992 At1DefTankVol 5000;
BA_ "SPN" SG_ 2566804992 At1DefTankVol 1761;
BA_ "SigType" SG_ 2566804992 At1DefTankVol 1;
BA_ "CI_ParId" SG_ 2564685591 AntiTheftPswRepr "1202";
BA_ "CI_SigId" SG_ 2564685591 AntiTheftPswRepr 2977;
BA_ "CI_SigName" SG_ 2564685591 AntiTheftPswRepr "Anti-theft Password Representation";
BA_ "SPN" SG_ 2564685591 AntiTheftPswRepr 1202;
BA_ "SigType" SG_ 2564685591 AntiTheftPswRepr 3;
BA_ "CI_ParId" SG_ 2564685591 AntiTheftCmdSts "1201";
BA_ "CI_SigId" SG_ 2564685591 AntiTheftCmdSts 2976;
BA_ "CI_SigName" SG_ 2564685591 AntiTheftCmdSts "Anti-theft Command States";
BA_ "SPN" SG_ 2564685591 AntiTheftCmdSts 1201;
BA_ "CI_ParId" SG_ 2565144605 AntiTheftPswRepr_E5001D "1202";
BA_ "CI_SigId" SG_ 2565144605 AntiTheftPswRepr_E5001D 2961;
BA_ "CI_SigName" SG_ 2565144605 AntiTheftPswRepr_E5001D "Anti-theft Password Representation";
BA_ "SPN" SG_ 2565144605 AntiTheftPswRepr_E5001D 1202;
BA_ "SigType" SG_ 2565144605 AntiTheftPswRepr_E5001D 3;
BA_ "CI_ParId" SG_ 2565144605 AntiTheftCmdSts_E5001D "1201";
BA_ "CI_SigId" SG_ 2565144605 AntiTheftCmdSts_E5001D 2960;
BA_ "CI_SigName" SG_ 2565144605 AntiTheftCmdSts_E5001D "Anti-theft Command States";
BA_ "SPN" SG_ 2565144605 AntiTheftCmdSts_E5001D 1201;
BA_ "CI_ParId" SG_ 2565144605 AntiTheftDesExitModeSts "1200";
BA_ "CI_SigId" SG_ 2565144605 AntiTheftDesExitModeSts 2959;
BA_ "CI_SigName" SG_ 2565144605 AntiTheftDesExitModeSts "Anti-theft Desired Exit Mode States";
BA_ "SPN" SG_ 2565144605 AntiTheftDesExitModeSts 1200;
BA_ "SigType" SG_ 2565144605 AntiTheftDesExitModeSts 4;
BA_ "CI_ParId" SG_ 2565144605 AntiTheftEncrIndSts "1199";
BA_ "CI_SigId" SG_ 2565144605 AntiTheftEncrIndSts 2958;
BA_ "CI_SigName" SG_ 2565144605 AntiTheftEncrIndSts "Anti-theft Encryption Indicator States";
BA_ "SPN" SG_ 2565144605 AntiTheftEncrIndSts 1199;
BA_ "SigType" SG_ 2565144605 AntiTheftEncrIndSts 4;
BA_ "CI_ParId" SG_ 2565152000 AntiTheftRandNum "1198";
BA_ "CI_SigId" SG_ 2565152000 AntiTheftRandNum 2967;
BA_ "CI_SigName" SG_ 2565152000 AntiTheftRandNum "Anti-theft Random Number";
BA_ "SPN" SG_ 2565152000 AntiTheftRandNum 1198;
BA_ "SigType" SG_ 2565152000 AntiTheftRandNum 3;
BA_ "CI_ParId" SG_ 2565152000 AntiTheftModPswSts "1197";
BA_ "CI_SigId" SG_ 2565152000 AntiTheftModPswSts 2966;
BA_ "CI_SigName" SG_ 2565152000 AntiTheftModPswSts "Anti-theft Modify Password States";
BA_ "SPN" SG_ 2565152000 AntiTheftModPswSts 1197;
BA_ "SigType" SG_ 2565152000 AntiTheftModPswSts 4;
BA_ "CI_ParId" SG_ 2565152000 AntiTheftCompStsSts "1196";
BA_ "CI_SigId" SG_ 2565152000 AntiTheftCompStsSts 2965;
BA_ "CI_SigName" SG_ 2565152000 AntiTheftCompStsSts "Anti-theft Component Status States";
BA_ "SPN" SG_ 2565152000 AntiTheftCompStsSts 1196;
BA_ "SigType" SG_ 2565152000 AntiTheftCompStsSts 4;
BA_ "CI_ParId" SG_ 2565152000 AntiTheftPswValInd "1195";
BA_ "CI_SigId" SG_ 2565152000 AntiTheftPswValInd 2964;
BA_ "CI_SigName" SG_ 2565152000 AntiTheftPswValInd "Anti-theft Password Valid Indicator";
BA_ "SPN" SG_ 2565152000 AntiTheftPswValInd 1195;
BA_ "SigType" SG_ 2565152000 AntiTheftPswValInd 4;
BA_ "CI_ParId" SG_ 2565152000 AntiTheftEncrSeedPresInd "1194";
BA_ "CI_SigId" SG_ 2565152000 AntiTheftEncrSeedPresInd 2963;
BA_ "CI_SigName" SG_ 2565152000 AntiTheftEncrSeedPresInd "Anti-theft Encryption Seed Present Indicator";
BA_ "SPN" SG_ 2565152000 AntiTheftEncrSeedPresInd 1194;
BA_ "SigType" SG_ 2565152000 AntiTheftEncrSeedPresInd 4;
BA_ "CI_ParId" SG_ 2561146657 MsgCks "4207";
BA_ "CI_SigId" SG_ 2561146657 MsgCks 6707;
BA_ "CI_SigName" SG_ 2561146657 MsgCks "Message Checksum";
BA_ "GenSigSendType" SG_ 2561146657 MsgCks 3;
BA_ "GenSigTimeoutTime_PCM" SG_ 2561146657 MsgCks 5000;
BA_ "SPN" SG_ 2561146657 MsgCks 4207;
BA_ "CI_ParId" SG_ 2561146657 MsgCnt "4206";
BA_ "CI_SigId" SG_ 2561146657 MsgCnt 6706;
BA_ "CI_SigName" SG_ 2561146657 MsgCnt "Message Counter";
BA_ "GenSigSendType" SG_ 2561146657 MsgCnt 3;
BA_ "GenSigTimeoutTime_PCM" SG_ 2561146657 MsgCnt 5000;
BA_ "SPN" SG_ 2561146657 MsgCnt 4206;
BA_ "CI_ParId" SG_ 2561146657 RightStackBtn "ID2565";
BA_ "CI_SigId" SG_ 2561146657 RightStackBtn 6705;
BA_ "CI_SigName" SG_ 2561146657 RightStackBtn "Right Stack Button";
BA_ "GenSigSendType" SG_ 2561146657 RightStackBtn 3;
BA_ "GenSigTimeoutTime_PCM" SG_ 2561146657 RightStackBtn 5000;
BA_ "SigType" SG_ 2561146657 RightStackBtn 4;
BA_ "CI_ParId" SG_ 2561146657 Sw8_Vsla_IcMenuRtn "I484";
BA_ "CI_SigId" SG_ 2561146657 Sw8_Vsla_IcMenuRtn 6701;
BA_ "CI_SigName" SG_ 2561146657 Sw8_Vsla_IcMenuRtn "Switch 8 � Adjustable Speed Limiter / IC Menu Return";
BA_ "GenSigSendType" SG_ 2561146657 Sw8_Vsla_IcMenuRtn 3;
BA_ "GenSigTimeoutTime_PCM" SG_ 2561146657 Sw8_Vsla_IcMenuRtn 5000;
BA_ "SigType" SG_ 2561146657 Sw8_Vsla_IcMenuRtn 4;
BA_ "CI_ParId" SG_ 2561146657 Sw7_AccDist_IcMenu2 "I396";
BA_ "CI_SigId" SG_ 2561146657 Sw7_AccDist_IcMenu2 6700;
BA_ "CI_SigName" SG_ 2561146657 Sw7_AccDist_IcMenu2 "Switch 7 � Adaptive Cruise Control Distance / IC Menu 2";
BA_ "GenSigSendType" SG_ 2561146657 Sw7_AccDist_IcMenu2 3;
BA_ "GenSigTimeoutTime_PCM" SG_ 2561146657 Sw7_AccDist_IcMenu2 5000;
BA_ "SigType" SG_ 2561146657 Sw7_AccDist_IcMenu2 4;
BA_ "CI_ParId" SG_ 2561146657 Sw6_AccEna_IcMenu1 "I395";
BA_ "CI_SigId" SG_ 2561146657 Sw6_AccEna_IcMenu1 6699;
BA_ "CI_SigName" SG_ 2561146657 Sw6_AccEna_IcMenu1 "Switch 6 � Adaptive Cruise Control Enable / IC Menu 1";
BA_ "GenSigSendType" SG_ 2561146657 Sw6_AccEna_IcMenu1 3;
BA_ "GenSigTimeoutTime_PCM" SG_ 2561146657 Sw6_AccEna_IcMenu1 5000;
BA_ "SigType" SG_ 2561146657 Sw6_AccEna_IcMenu1 4;
BA_ "CI_ParId" SG_ 2561146657 Sw2_CcEna_AccEna "I392";
BA_ "CI_SigId" SG_ 2561146657 Sw2_CcEna_AccEna 6698;
BA_ "CI_SigName" SG_ 2561146657 Sw2_CcEna_AccEna "Switch 2 � Cruise Control Enable / Adaptive Cruise Control Enable";
BA_ "GenSigSendType" SG_ 2561146657 Sw2_CcEna_AccEna 3;
BA_ "GenSigTimeoutTime_PCM" SG_ 2561146657 Sw2_CcEna_AccEna 5000;
BA_ "SigType" SG_ 2561146657 Sw2_CcEna_AccEna 4;
BA_ "CI_ParId" SG_ 2561146657 Sw3_CcRes_Canc "I394";
BA_ "CI_SigId" SG_ 2561146657 Sw3_CcRes_Canc 6697;
BA_ "CI_SigName" SG_ 2561146657 Sw3_CcRes_Canc "Switch 3 � Cruise Control Resume / Cancel";
BA_ "GenSigSendType" SG_ 2561146657 Sw3_CcRes_Canc 3;
BA_ "GenSigTimeoutTime_PCM" SG_ 2561146657 Sw3_CcRes_Canc 5000;
BA_ "SigType" SG_ 2561146657 Sw3_CcRes_Canc 4;
BA_ "CI_ParId" SG_ 2561146657 Sw5_CcCanc_Vsla "I393";
BA_ "CI_SigId" SG_ 2561146657 Sw5_CcCanc_Vsla 6696;
BA_ "CI_SigName" SG_ 2561146657 Sw5_CcCanc_Vsla "Switch 5 � Cruise Control Cancel / Adjustable Speed Limiter";
BA_ "GenSigSendType" SG_ 2561146657 Sw5_CcCanc_Vsla 3;
BA_ "GenSigTimeoutTime_PCM" SG_ 2561146657 Sw5_CcCanc_Vsla 5000;
BA_ "SigType" SG_ 2561146657 Sw5_CcCanc_Vsla 4;
BA_ "CI_ParId" SG_ 2561146657 Sw4_CcSetDec "I491";
BA_ "CI_SigId" SG_ 2561146657 Sw4_CcSetDec 6695;
BA_ "CI_SigName" SG_ 2561146657 Sw4_CcSetDec "Switch 4 � Cruise Control Set Dec";
BA_ "GenSigSendType" SG_ 2561146657 Sw4_CcSetDec 3;
BA_ "GenSigTimeoutTime_PCM" SG_ 2561146657 Sw4_CcSetDec 5000;
BA_ "SigType" SG_ 2561146657 Sw4_CcSetDec 4;
BA_ "CI_ParId" SG_ 2561146657 Sw1_CcSetAcc "I490";
BA_ "CI_SigId" SG_ 2561146657 Sw1_CcSetAcc 6694;
BA_ "CI_SigName" SG_ 2561146657 Sw1_CcSetAcc "Switch 1 � Cruise Control Set Acc";
BA_ "GenSigSendType" SG_ 2561146657 Sw1_CcSetAcc 3;
BA_ "GenSigTimeoutTime_PCM" SG_ 2561146657 Sw1_CcSetAcc 5000;
BA_ "SigType" SG_ 2561146657 Sw1_CcSetAcc 4;
BA_ "CI_ParId" SG_ 2561146657 SwB_NextSrc "I391";
BA_ "CI_SigId" SG_ 2561146657 SwB_NextSrc 6692;
BA_ "CI_SigName" SG_ 2561146657 SwB_NextSrc "Switch B � Next Source";
BA_ "GenSigSendType" SG_ 2561146657 SwB_NextSrc 3;
BA_ "GenSigTimeoutTime_PCM" SG_ 2561146657 SwB_NextSrc 5000;
BA_ "SigType" SG_ 2561146657 SwB_NextSrc 4;
BA_ "CI_ParId" SG_ 2561146657 SwC_ScanDw "I390";
BA_ "CI_SigId" SG_ 2561146657 SwC_ScanDw 6691;
BA_ "CI_SigName" SG_ 2561146657 SwC_ScanDw "Switch C � Scan Down";
BA_ "GenSigSendType" SG_ 2561146657 SwC_ScanDw 3;
BA_ "GenSigTimeoutTime_PCM" SG_ 2561146657 SwC_ScanDw 5000;
BA_ "SigType" SG_ 2561146657 SwC_ScanDw 4;
BA_ "CI_ParId" SG_ 2561146657 SwA_ScanUp "I389";
BA_ "CI_SigId" SG_ 2561146657 SwA_ScanUp 6690;
BA_ "CI_SigName" SG_ 2561146657 SwA_ScanUp "Switch A � Scan Up";
BA_ "GenSigSendType" SG_ 2561146657 SwA_ScanUp 3;
BA_ "GenSigTimeoutTime_PCM" SG_ 2561146657 SwA_ScanUp 5000;
BA_ "SigType" SG_ 2561146657 SwA_ScanUp 4;
BA_ "CI_ParId" SG_ 2561146657 SwE_Mute "I383";
BA_ "CI_SigId" SG_ 2561146657 SwE_Mute 6688;
BA_ "CI_SigName" SG_ 2561146657 SwE_Mute "Switch E � Mute";
BA_ "GenSigSendType" SG_ 2561146657 SwE_Mute 3;
BA_ "GenSigTimeoutTime_PCM" SG_ 2561146657 SwE_Mute 5000;
BA_ "SigType" SG_ 2561146657 SwE_Mute 4;
BA_ "CI_ParId" SG_ 2561146657 SwF_VolDw "I388";
BA_ "CI_SigId" SG_ 2561146657 SwF_VolDw 6687;
BA_ "CI_SigName" SG_ 2561146657 SwF_VolDw "Switch F � Volume Down";
BA_ "GenSigSendType" SG_ 2561146657 SwF_VolDw 3;
BA_ "GenSigTimeoutTime_PCM" SG_ 2561146657 SwF_VolDw 5000;
BA_ "SigType" SG_ 2561146657 SwF_VolDw 4;
BA_ "CI_ParId" SG_ 2561146657 SwD_VolUp "I387";
BA_ "CI_SigId" SG_ 2561146657 SwD_VolUp 6686;
BA_ "CI_SigName" SG_ 2561146657 SwD_VolUp "Switch D � Volume Up";
BA_ "GenSigSendType" SG_ 2561146657 SwD_VolUp 3;
BA_ "GenSigTimeoutTime_PCM" SG_ 2561146657 SwD_VolUp 5000;
BA_ "SigType" SG_ 2561146657 SwD_VolUp 4;
BA_ "CI_ParId" SG_ 2561146657 SwR_IcMenu_Hwa "I385";
BA_ "CI_SigId" SG_ 2561146657 SwR_IcMenu_Hwa 42148;
BA_ "CI_SigName" SG_ 2561146657 SwR_IcMenu_Hwa "Switch R � IC Menu / Highway Assist";
BA_ "GenSigSendType" SG_ 2561146657 SwR_IcMenu_Hwa 3;
BA_ "GenSigTimeoutTime_PCM" SG_ 2561146657 SwR_IcMenu_Hwa 5000;
BA_ "SigType" SG_ 2561146657 SwR_IcMenu_Hwa 4;
BA_ "CI_ParId" SG_ 2561146657 SwQ_VoiceRec "I386";
BA_ "CI_SigId" SG_ 2561146657 SwQ_VoiceRec 6684;
BA_ "CI_SigName" SG_ 2561146657 SwQ_VoiceRec "Switch Q � Voice Recognition";
BA_ "GenSigSendType" SG_ 2561146657 SwQ_VoiceRec 3;
BA_ "GenSigTimeoutTime_PCM" SG_ 2561146657 SwQ_VoiceRec 5000;
BA_ "SigType" SG_ 2561146657 SwQ_VoiceRec 4;
BA_ "CI_ParId" SG_ 2561146657 SwP_PhoneCall "I384";
BA_ "CI_SigId" SG_ 2561146657 SwP_PhoneCall 6683;
BA_ "CI_SigName" SG_ 2561146657 SwP_PhoneCall "Switch P � Phone Call";
BA_ "GenSigSendType" SG_ 2561146657 SwP_PhoneCall 3;
BA_ "GenSigTimeoutTime_PCM" SG_ 2561146657 SwP_PhoneCall 5000;
BA_ "SigType" SG_ 2561146657 SwP_PhoneCall 4;
BA_ "CI_ParId" SG_ 2561146657 SwN_Ok "I489";
BA_ "CI_SigId" SG_ 2561146657 SwN_Ok 6682;
BA_ "CI_SigName" SG_ 2561146657 SwN_Ok "Switch N � OK";
BA_ "GenSigSendType" SG_ 2561146657 SwN_Ok 3;
BA_ "GenSigTimeoutTime_PCM" SG_ 2561146657 SwN_Ok 5000;
BA_ "SigType" SG_ 2561146657 SwN_Ok 4;
BA_ "CI_ParId" SG_ 2561146657 SwH_Right "I488";
BA_ "CI_SigId" SG_ 2561146657 SwH_Right 6681;
BA_ "CI_SigName" SG_ 2561146657 SwH_Right "Switch H � Right";
BA_ "GenSigSendType" SG_ 2561146657 SwH_Right 3;
BA_ "GenSigTimeoutTime_PCM" SG_ 2561146657 SwH_Right 5000;
BA_ "SigType" SG_ 2561146657 SwH_Right 4;
BA_ "CI_ParId" SG_ 2561146657 SwM_Left "I487";
BA_ "CI_SigId" SG_ 2561146657 SwM_Left 6680;
BA_ "CI_SigName" SG_ 2561146657 SwM_Left "Switch M � Left";
BA_ "GenSigSendType" SG_ 2561146657 SwM_Left 3;
BA_ "GenSigTimeoutTime_PCM" SG_ 2561146657 SwM_Left 5000;
BA_ "SigType" SG_ 2561146657 SwM_Left 4;
BA_ "CI_ParId" SG_ 2561146657 SwL_Dw "I486";
BA_ "CI_SigId" SG_ 2561146657 SwL_Dw 6679;
BA_ "CI_SigName" SG_ 2561146657 SwL_Dw "Switch L � Down";
BA_ "GenSigSendType" SG_ 2561146657 SwL_Dw 3;
BA_ "GenSigTimeoutTime_PCM" SG_ 2561146657 SwL_Dw 5000;
BA_ "SigType" SG_ 2561146657 SwL_Dw 4;
BA_ "CI_ParId" SG_ 2561146657 SwG_Up "I485";
BA_ "CI_SigId" SG_ 2561146657 SwG_Up 6678;
BA_ "CI_SigName" SG_ 2561146657 SwG_Up "Switch G � Up";
BA_ "GenSigSendType" SG_ 2561146657 SwG_Up 3;
BA_ "GenSigTimeoutTime_PCM" SG_ 2561146657 SwG_Up 5000;
BA_ "SigType" SG_ 2561146657 SwG_Up 4;
BA_ "CI_ParId" SG_ 2566859292 Pos_RelHead "AS008";
BA_ "CI_SigId" SG_ 2566859292 Pos_RelHead 10170;
BA_ "CI_SigName" SG_ 2566859292 Pos_RelHead "Position � Relative Heading";
BA_ "GenSigStartValue" SG_ 2566859292 Pos_RelHead 255;
BA_ "GenSigTimeoutTime_SGW" SG_ 2566859292 Pos_RelHead 5000;
BA_ "SigType" SG_ 2566859292 Pos_RelHead 1;
BA_ "CI_ParId" SG_ 2566859292 Pos_Speed "AS007";
BA_ "CI_SigId" SG_ 2566859292 Pos_Speed 10169;
BA_ "CI_SigName" SG_ 2566859292 Pos_Speed "Position � Speed";
BA_ "GenSigStartValue" SG_ 2566859292 Pos_Speed 511;
BA_ "GenSigTimeoutTime_SGW" SG_ 2566859292 Pos_Speed 5000;
BA_ "CI_ParId" SG_ 2566859292 Pos_CurLane "AS011";
BA_ "CI_SigId" SG_ 2566859292 Pos_CurLane 10167;
BA_ "CI_SigName" SG_ 2566859292 Pos_CurLane "Position � Current Lane";
BA_ "GenSigTimeoutTime_SGW" SG_ 2566859292 Pos_CurLane 5000;
BA_ "CI_ParId" SG_ 2566859292 Pos_PosConf "AS010";
BA_ "CI_SigId" SG_ 2566859292 Pos_PosConf 10168;
BA_ "CI_SigName" SG_ 2566859292 Pos_PosConf "Position � Position Confidence";
BA_ "GenSigStartValue" SG_ 2566859292 Pos_PosConf 7;
BA_ "GenSigTimeoutTime_SGW" SG_ 2566859292 Pos_PosConf 5000;
BA_ "CI_ParId" SG_ 2566859292 Pos_PosAge "AS006";
BA_ "CI_SigId" SG_ 2566859292 Pos_PosAge 10166;
BA_ "CI_SigName" SG_ 2566859292 Pos_PosAge "Position � Position Age";
BA_ "GenSigStartValue" SG_ 2566859292 Pos_PosAge 511;
BA_ "GenSigTimeoutTime_SGW" SG_ 2566859292 Pos_PosAge 5000;
BA_ "CI_ParId" SG_ 2566859292 Pos_PosProb "AS009";
BA_ "CI_SigId" SG_ 2566859292 Pos_PosProb 10164;
BA_ "CI_SigName" SG_ 2566859292 Pos_PosProb "Position � Position Probability";
BA_ "GenSigStartValue" SG_ 2566859292 Pos_PosProb 31;
BA_ "GenSigTimeoutTime_SGW" SG_ 2566859292 Pos_PosProb 5000;
BA_ "CI_ParId" SG_ 2566859292 Pos_PosIx "AS005";
BA_ "CI_SigId" SG_ 2566859292 Pos_PosIx 10165;
BA_ "CI_SigName" SG_ 2566859292 Pos_PosIx "Position � Position Index";
BA_ "GenSigTimeoutTime_SGW" SG_ 2566859292 Pos_PosIx 5000;
BA_ "CI_ParId" SG_ 2566859292 Pos_PathIx "AS003";
BA_ "CI_SigId" SG_ 2566859292 Pos_PathIx 10162;
BA_ "CI_SigName" SG_ 2566859292 Pos_PathIx "Position � Path Index";
BA_ "GenSigStartValue" SG_ 2566859292 Pos_PathIx 8;
BA_ "GenSigTimeoutTime_SGW" SG_ 2566859292 Pos_PathIx 5000;
BA_ "CI_ParId" SG_ 2566859292 Pos_CycCnt "AS002";
BA_ "CI_SigId" SG_ 2566859292 Pos_CycCnt 10163;
BA_ "CI_SigName" SG_ 2566859292 Pos_CycCnt "Position � Cyclic Counter";
BA_ "GenSigTimeoutTime_SGW" SG_ 2566859292 Pos_CycCnt 5000;
BA_ "CI_ParId" SG_ 2566859292 Pos_Ofs "AS004";
BA_ "CI_SigId" SG_ 2566859292 Pos_Ofs 10161;
BA_ "CI_SigName" SG_ 2566859292 Pos_Ofs "Position � Offset";
BA_ "GenSigStartValue" SG_ 2566859292 Pos_Ofs 8191;
BA_ "GenSigTimeoutTime_SGW" SG_ 2566859292 Pos_Ofs 5000;
BA_ "CI_ParId" SG_ 2566859292 MsgType "AS001";
BA_ "CI_SigId" SG_ 2566859292 MsgType 10160;
BA_ "CI_SigName" SG_ 2566859292 MsgType "Message Type";
BA_ "GenSigStartValue" SG_ 2566859292 MsgType 6;
BA_ "GenSigTimeoutTime_SGW" SG_ 2566859292 MsgType 5000;
BA_ "CI_ParId" SG_ 2566859548 Seg_NumOfLanesInDrivDir "AS021";
BA_ "CI_SigId" SG_ 2566859548 Seg_NumOfLanesInDrivDir 10188;
BA_ "CI_SigName" SG_ 2566859548 Seg_NumOfLanesInDrivDir "Segment � Number of lanes in driving direction";
BA_ "GenSigStartValue" SG_ 2566859548 Seg_NumOfLanesInDrivDir 7;
BA_ "CI_ParId" SG_ 2566859548 Seg_NumOfLanesInOppDir "AS022";
BA_ "CI_SigId" SG_ 2566859548 Seg_NumOfLanesInOppDir 10189;
BA_ "CI_SigName" SG_ 2566859548 Seg_NumOfLanesInOppDir "Segment � Number of lanes in opposite direction";
BA_ "GenSigStartValue" SG_ 2566859548 Seg_NumOfLanesInOppDir 3;
BA_ "SigType" SG_ 2566859548 Seg_NumOfLanesInOppDir 4;
BA_ "CI_ParId" SG_ 2566859548 Seg_DividedRoad "AS025";
BA_ "CI_SigId" SG_ 2566859548 Seg_DividedRoad 10190;
BA_ "CI_SigName" SG_ 2566859548 Seg_DividedRoad "Segment � Divided Road";
BA_ "GenSigStartValue" SG_ 2566859548 Seg_DividedRoad 3;
BA_ "SigType" SG_ 2566859548 Seg_DividedRoad 4;
BA_ "CI_ParId" SG_ 2566859548 Seg_EffSpeedLimType "AS020";
BA_ "CI_SigId" SG_ 2566859548 Seg_EffSpeedLimType 10186;
BA_ "CI_SigName" SG_ 2566859548 Seg_EffSpeedLimType "Segment � Effective Speed Limit Type";
BA_ "GenSigStartValue" SG_ 2566859548 Seg_EffSpeedLimType 7;
BA_ "CI_ParId" SG_ 2566859548 Seg_EffSpeedLim "AS019";
BA_ "CI_SigId" SG_ 2566859548 Seg_EffSpeedLim 10187;
BA_ "CI_SigName" SG_ 2566859548 Seg_EffSpeedLim "Segment � Effective Speed Limit";
BA_ "GenSigStartValue" SG_ 2566859548 Seg_EffSpeedLim 31;
BA_ "CI_ParId" SG_ 2566859548 Seg_FormOfWay "AS018";
BA_ "CI_SigId" SG_ 2566859548 Seg_FormOfWay 10183;
BA_ "CI_SigName" SG_ 2566859548 Seg_FormOfWay "Segment � Form of Way";
BA_ "GenSigStartValue" SG_ 2566859548 Seg_FormOfWay 3;
BA_ "CI_ParId" SG_ 2566859548 Seg_ComplexInters "AS027";
BA_ "CI_SigId" SG_ 2566859548 Seg_ComplexInters 10184;
BA_ "CI_SigName" SG_ 2566859548 Seg_ComplexInters "Segment � Complex Intersection";
BA_ "GenSigStartValue" SG_ 2566859548 Seg_ComplexInters 3;
BA_ "SigType" SG_ 2566859548 Seg_ComplexInters 4;
BA_ "CI_ParId" SG_ 2566859548 Seg_PartOfCalcRoute "AS029";
BA_ "CI_SigId" SG_ 2566859548 Seg_PartOfCalcRoute 10185;
BA_ "CI_SigName" SG_ 2566859548 Seg_PartOfCalcRoute "Segment � Part of Calculated Route";
BA_ "GenSigStartValue" SG_ 2566859548 Seg_PartOfCalcRoute 3;
BA_ "SigType" SG_ 2566859548 Seg_PartOfCalcRoute 4;
BA_ "CI_ParId" SG_ 2566859548 Seg_FunctRoadClass "AS017";
BA_ "CI_SigId" SG_ 2566859548 Seg_FunctRoadClass 10181;
BA_ "CI_SigName" SG_ 2566859548 Seg_FunctRoadClass "Segment � Functional Road Class";
BA_ "GenSigStartValue" SG_ 2566859548 Seg_FunctRoadClass 7;
BA_ "CI_ParId" SG_ 2566859548 Seg_RelProb "AS028";
BA_ "CI_SigId" SG_ 2566859548 Seg_RelProb 10182;
BA_ "CI_SigName" SG_ 2566859548 Seg_RelProb "Segment � Relative Probability";
BA_ "GenSigStartValue" SG_ 2566859548 Seg_RelProb 31;
BA_ "CI_ParId" SG_ 2566859548 Seg_Update "AS016";
BA_ "CI_SigId" SG_ 2566859548 Seg_Update 10176;
BA_ "CI_SigName" SG_ 2566859548 Seg_Update "Segment � Update";
BA_ "CI_ParId" SG_ 2566859548 Seg_Retr "AS013";
BA_ "CI_SigId" SG_ 2566859548 Seg_Retr 10177;
BA_ "CI_SigName" SG_ 2566859548 Seg_Retr "Segment � Retransmission";
BA_ "CI_ParId" SG_ 2566859548 Seg_BuiltUpArea "AS026";
BA_ "CI_SigId" SG_ 2566859548 Seg_BuiltUpArea 10178;
BA_ "CI_SigName" SG_ 2566859548 Seg_BuiltUpArea "Segment � Built-up Area";
BA_ "GenSigStartValue" SG_ 2566859548 Seg_BuiltUpArea 3;
BA_ "SigType" SG_ 2566859548 Seg_BuiltUpArea 4;
BA_ "CI_ParId" SG_ 2566859548 Seg_Bridge "AS024";
BA_ "CI_SigId" SG_ 2566859548 Seg_Bridge 10179;
BA_ "CI_SigName" SG_ 2566859548 Seg_Bridge "Segment � Bridge";
BA_ "GenSigStartValue" SG_ 2566859548 Seg_Bridge 3;
BA_ "SigType" SG_ 2566859548 Seg_Bridge 4;
BA_ "CI_ParId" SG_ 2566859548 Seg_Tunnel "AS023";
BA_ "CI_SigId" SG_ 2566859548 Seg_Tunnel 10180;
BA_ "CI_SigName" SG_ 2566859548 Seg_Tunnel "Segment � Tunnel";
BA_ "GenSigStartValue" SG_ 2566859548 Seg_Tunnel 3;
BA_ "SigType" SG_ 2566859548 Seg_Tunnel 4;
BA_ "CI_ParId" SG_ 2566859548 Seg_PathIx "AS014";
BA_ "CI_SigId" SG_ 2566859548 Seg_PathIx 10174;
BA_ "CI_SigName" SG_ 2566859548 Seg_PathIx "Segment � Path Index";
BA_ "GenSigStartValue" SG_ 2566859548 Seg_PathIx 8;
BA_ "CI_ParId" SG_ 2566859548 Seg_CycCnt "AS012";
BA_ "CI_SigId" SG_ 2566859548 Seg_CycCnt 10175;
BA_ "CI_SigName" SG_ 2566859548 Seg_CycCnt "Segment � Cyclic Counter";
BA_ "CI_ParId" SG_ 2566859548 Seg_Ofs "AS015";
BA_ "CI_SigId" SG_ 2566859548 Seg_Ofs 10173;
BA_ "CI_SigName" SG_ 2566859548 Seg_Ofs "Segment � Offset";
BA_ "GenSigStartValue" SG_ 2566859548 Seg_Ofs 8191;
BA_ "CI_ParId" SG_ 2566859548 MsgType_FF2B1C "AS001";
BA_ "CI_SigId" SG_ 2566859548 MsgType_FF2B1C 10172;
BA_ "CI_SigName" SG_ 2566859548 MsgType_FF2B1C "Message Type";
BA_ "GenSigStartValue" SG_ 2566859548 MsgType_FF2B1C 6;
BA_ "CI_ParId" SG_ 2566859804 Stub_NumOfLanesInDrivDir "AS039";
BA_ "CI_SigId" SG_ 2566859804 Stub_NumOfLanesInDrivDir 10205;
BA_ "CI_SigName" SG_ 2566859804 Stub_NumOfLanesInDrivDir "Stub � Number of lanes in driving direction";
BA_ "GenSigStartValue" SG_ 2566859804 Stub_NumOfLanesInDrivDir 7;
BA_ "CI_ParId" SG_ 2566859804 Stub_NumOfLanesInOppDir "AS040";
BA_ "CI_SigId" SG_ 2566859804 Stub_NumOfLanesInOppDir 10206;
BA_ "CI_SigName" SG_ 2566859804 Stub_NumOfLanesInOppDir "Stub � Number of lanes in opposite direction";
BA_ "GenSigStartValue" SG_ 2566859804 Stub_NumOfLanesInOppDir 3;
BA_ "SigType" SG_ 2566859804 Stub_NumOfLanesInOppDir 4;
BA_ "CI_ParId" SG_ 2566859804 Stub_RightOfWay "AS042";
BA_ "CI_SigId" SG_ 2566859804 Stub_RightOfWay 10207;
BA_ "CI_SigName" SG_ 2566859804 Stub_RightOfWay "Stub � Right of Way";
BA_ "GenSigStartValue" SG_ 2566859804 Stub_RightOfWay 3;
BA_ "SigType" SG_ 2566859804 Stub_RightOfWay 4;
BA_ "CI_ParId" SG_ 2566859804 Stub_LastStubAtOfs "AS045";
BA_ "CI_SigId" SG_ 2566859804 Stub_LastStubAtOfs 10208;
BA_ "CI_SigName" SG_ 2566859804 Stub_LastStubAtOfs "Stub � Last Stub at Offset";
BA_ "CI_ParId" SG_ 2566859804 Stub_TurnAngle "AS036";
BA_ "CI_SigId" SG_ 2566859804 Stub_TurnAngle 10204;
BA_ "CI_SigName" SG_ 2566859804 Stub_TurnAngle "Stub � Turn Angle";
BA_ "GenSigStartValue" SG_ 2566859804 Stub_TurnAngle 255;
BA_ "SigType" SG_ 2566859804 Stub_TurnAngle 1;
BA_ "CI_ParId" SG_ 2566859804 Stub_FormOfWay "AS038";
BA_ "CI_SigId" SG_ 2566859804 Stub_FormOfWay 10201;
BA_ "CI_SigName" SG_ 2566859804 Stub_FormOfWay "Stub � Form of Way";
BA_ "GenSigStartValue" SG_ 2566859804 Stub_FormOfWay 3;
BA_ "CI_ParId" SG_ 2566859804 Stub_ComplexInters "AS041";
BA_ "CI_SigId" SG_ 2566859804 Stub_ComplexInters 10202;
BA_ "CI_SigName" SG_ 2566859804 Stub_ComplexInters "Stub � Complex Intersection";
BA_ "GenSigStartValue" SG_ 2566859804 Stub_ComplexInters 3;
BA_ "SigType" SG_ 2566859804 Stub_ComplexInters 4;
BA_ "CI_ParId" SG_ 2566859804 Stub_PartOfCalcRoute "AS044";
BA_ "CI_SigId" SG_ 2566859804 Stub_PartOfCalcRoute 10203;
BA_ "CI_SigName" SG_ 2566859804 Stub_PartOfCalcRoute "Stub � Part of Calculated Route";
BA_ "GenSigStartValue" SG_ 2566859804 Stub_PartOfCalcRoute 3;
BA_ "SigType" SG_ 2566859804 Stub_PartOfCalcRoute 4;
BA_ "CI_ParId" SG_ 2566859804 Stub_FunctRoadClass "AS043";
BA_ "CI_SigId" SG_ 2566859804 Stub_FunctRoadClass 10199;
BA_ "CI_SigName" SG_ 2566859804 Stub_FunctRoadClass "Stub � Functional Road Class";
BA_ "GenSigStartValue" SG_ 2566859804 Stub_FunctRoadClass 7;
BA_ "CI_ParId" SG_ 2566859804 Stub_RelProb "AS037";
BA_ "CI_SigId" SG_ 2566859804 Stub_RelProb 10200;
BA_ "CI_SigName" SG_ 2566859804 Stub_RelProb "Stub � Relative Probability";
BA_ "GenSigStartValue" SG_ 2566859804 Stub_RelProb 31;
BA_ "CI_ParId" SG_ 2566859804 Stub_Update "AS034";
BA_ "CI_SigId" SG_ 2566859804 Stub_Update 10196;
BA_ "CI_SigName" SG_ 2566859804 Stub_Update "Stub � Update";
BA_ "CI_ParId" SG_ 2566859804 Stub_Retr "AS031";
BA_ "CI_SigId" SG_ 2566859804 Stub_Retr 10197;
BA_ "CI_SigName" SG_ 2566859804 Stub_Retr "Stub � Retransmission";
BA_ "CI_ParId" SG_ 2566859804 Stub_SubPathIx "AS035";
BA_ "CI_SigId" SG_ 2566859804 Stub_SubPathIx 10198;
BA_ "CI_SigName" SG_ 2566859804 Stub_SubPathIx "Stub � Sub-Path Index";
BA_ "GenSigStartValue" SG_ 2566859804 Stub_SubPathIx 8;
BA_ "CI_ParId" SG_ 2566859804 Stub_PathIx "AS032";
BA_ "CI_SigId" SG_ 2566859804 Stub_PathIx 10194;
BA_ "CI_SigName" SG_ 2566859804 Stub_PathIx "Stub � Path Index";
BA_ "GenSigStartValue" SG_ 2566859804 Stub_PathIx 8;
BA_ "CI_ParId" SG_ 2566859804 Stub_CycCnt "AS030";
BA_ "CI_SigId" SG_ 2566859804 Stub_CycCnt 10195;
BA_ "CI_SigName" SG_ 2566859804 Stub_CycCnt "Stub � Cyclic Counter";
BA_ "CI_ParId" SG_ 2566859804 Stub_Ofs "AS033";
BA_ "CI_SigId" SG_ 2566859804 Stub_Ofs 10193;
BA_ "CI_SigName" SG_ 2566859804 Stub_Ofs "Stub � Offset";
BA_ "GenSigStartValue" SG_ 2566859804 Stub_Ofs 8191;
BA_ "CI_ParId" SG_ 2566859804 MsgType_FF2C1C "AS001";
BA_ "CI_SigId" SG_ 2566859804 MsgType_FF2C1C 10192;
BA_ "CI_SigName" SG_ 2566859804 MsgType_FF2C1C "Message Type";
BA_ "GenSigStartValue" SG_ 2566859804 MsgType_FF2C1C 6;
BA_ "CI_ParId" SG_ 2566860060 ProfShort_Val1_1_Curv "AS111";
BA_ "CI_SigId" SG_ 2566860060 ProfShort_Val1_1_Curv 10232;
BA_ "CI_SigName" SG_ 2566860060 ProfShort_Val1_1_Curv "Profile Short � Value 1�1 � Curvature";
BA_ "GenSigStartValue" SG_ 2566860060 ProfShort_Val1_1_Curv 1023;
BA_ "CI_ParId" SG_ 2566860060 ProfShort_Val1_2_RouteNumTypes "AS112";
BA_ "CI_SigId" SG_ 2566860060 ProfShort_Val1_2_RouteNumTypes 10233;
BA_ "CI_SigName" SG_ 2566860060 ProfShort_Val1_2_RouteNumTypes "Profile Short � Value 1�2 � Route Number Types";
BA_ "GenSigStartValue" SG_ 2566860060 ProfShort_Val1_2_RouteNumTypes 1023;
BA_ "CI_ParId" SG_ 2566860060 ProfShort_Val1_3_Slope "AS113";
BA_ "CI_SigId" SG_ 2566860060 ProfShort_Val1_3_Slope 10234;
BA_ "CI_SigName" SG_ 2566860060 ProfShort_Val1_3_Slope "Profile Short � Value 1�3 � Slope";
BA_ "GenSigStartValue" SG_ 2566860060 ProfShort_Val1_3_Slope 1023;
BA_ "CI_ParId" SG_ 2566860060 ProfShort_Val1_4_Slope "AS114";
BA_ "CI_SigId" SG_ 2566860060 ProfShort_Val1_4_Slope 10235;
BA_ "CI_SigName" SG_ 2566860060 ProfShort_Val1_4_Slope "Profile Short � Value 1�4 � Slope";
BA_ "GenSigStartValue" SG_ 2566860060 ProfShort_Val1_4_Slope 1023;
BA_ "CI_ParId" SG_ 2566860060 ProfShort_Val1_5_RoadAcc "AS115";
BA_ "CI_SigId" SG_ 2566860060 ProfShort_Val1_5_RoadAcc 10236;
BA_ "CI_SigName" SG_ 2566860060 ProfShort_Val1_5_RoadAcc "Profile Short � Value 1�5 � Road accessibility";
BA_ "GenSigStartValue" SG_ 2566860060 ProfShort_Val1_5_RoadAcc 1023;
BA_ "CI_ParId" SG_ 2566860060 ProfShort_Val1_6_RoadCond "AS116";
BA_ "CI_SigId" SG_ 2566860060 ProfShort_Val1_6_RoadCond 10237;
BA_ "CI_SigName" SG_ 2566860060 ProfShort_Val1_6_RoadCond "Profile Short � Value 1�6 � Road condition";
BA_ "GenSigStartValue" SG_ 2566860060 ProfShort_Val1_6_RoadCond 1023;
BA_ "CI_ParId" SG_ 2566860060 ProfShort_Val1_7_VarSpeedSignPos "AS117";
BA_ "CI_SigId" SG_ 2566860060 ProfShort_Val1_7_VarSpeedSignPos 10238;
BA_ "CI_SigName" SG_ 2566860060 ProfShort_Val1_7_VarSpeedSignPos "Profile Short � Value 1�7 � Variable Speed Sign Position";
BA_ "GenSigStartValue" SG_ 2566860060 ProfShort_Val1_7_VarSpeedSignPos 1023;
BA_ "CI_ParId" SG_ 2566860060 ProfShort_Val1_8_HeadChg "AS118";
BA_ "CI_SigId" SG_ 2566860060 ProfShort_Val1_8_HeadChg 10239;
BA_ "CI_SigName" SG_ 2566860060 ProfShort_Val1_8_HeadChg "Profile Short � Value 1�8 � Heading Change";
BA_ "GenSigStartValue" SG_ 2566860060 ProfShort_Val1_8_HeadChg 1023;
BA_ "CI_ParId" SG_ 2566860060 ProfShort_Val1_9_RsvdForStdTypes "AS119";
BA_ "CI_SigId" SG_ 2566860060 ProfShort_Val1_9_RsvdForStdTypes 10240;
BA_ "CI_SigName" SG_ 2566860060 ProfShort_Val1_9_RsvdForStdTypes "Profile Short � Value 1�9 � Reserved for standard types";
BA_ "GenSigStartValue" SG_ 2566860060 ProfShort_Val1_9_RsvdForStdTypes 1023;
BA_ "CI_ParId" SG_ 2566860060 ProfShort_Val1_16_RsvdForSysSpec "AS120";
BA_ "CI_SigId" SG_ 2566860060 ProfShort_Val1_16_RsvdForSysSpec 10241;
BA_ "CI_SigName" SG_ 2566860060 ProfShort_Val1_16_RsvdForSysSpec "Profile Short � Value 1�16 � Reserved for system specific types";
BA_ "GenSigStartValue" SG_ 2566860060 ProfShort_Val1_16_RsvdForSysSpec 1023;
BA_ "CI_ParId" SG_ 2566860060 ProfShort_Val0_1_Curv "AS101";
BA_ "CI_SigId" SG_ 2566860060 ProfShort_Val0_1_Curv 10221;
BA_ "CI_SigName" SG_ 2566860060 ProfShort_Val0_1_Curv "Profile Short � Value 0�1 � Curvature";
BA_ "GenSigStartValue" SG_ 2566860060 ProfShort_Val0_1_Curv 1023;
BA_ "CI_ParId" SG_ 2566860060 ProfShort_Val0_2_RouteNumTypes "AS102";
BA_ "CI_SigId" SG_ 2566860060 ProfShort_Val0_2_RouteNumTypes 10222;
BA_ "CI_SigName" SG_ 2566860060 ProfShort_Val0_2_RouteNumTypes "Profile Short � Value 0�2 � Route Number Types";
BA_ "CI_ParId" SG_ 2566860060 ProfShort_Val0_3_Slope "AS103";
BA_ "CI_SigId" SG_ 2566860060 ProfShort_Val0_3_Slope 10223;
BA_ "CI_SigName" SG_ 2566860060 ProfShort_Val0_3_Slope "Profile Short � Value 0�3 � Slope";
BA_ "GenSigStartValue" SG_ 2566860060 ProfShort_Val0_3_Slope 1023;
BA_ "CI_ParId" SG_ 2566860060 ProfShort_Val0_4_Slope "AS104";
BA_ "CI_SigId" SG_ 2566860060 ProfShort_Val0_4_Slope 10224;
BA_ "CI_SigName" SG_ 2566860060 ProfShort_Val0_4_Slope "Profile Short � Value 0�4 � Slope";
BA_ "GenSigStartValue" SG_ 2566860060 ProfShort_Val0_4_Slope 1023;
BA_ "CI_ParId" SG_ 2566860060 ProfShort_Val0_5_RoadAcc "AS105";
BA_ "CI_SigId" SG_ 2566860060 ProfShort_Val0_5_RoadAcc 10225;
BA_ "CI_SigName" SG_ 2566860060 ProfShort_Val0_5_RoadAcc "Profile Short � Value 0�5 � Road accessibility";
BA_ "CI_ParId" SG_ 2566860060 ProfShort_Val0_6_RoadCond "AS106";
BA_ "CI_SigId" SG_ 2566860060 ProfShort_Val0_6_RoadCond 10226;
BA_ "CI_SigName" SG_ 2566860060 ProfShort_Val0_6_RoadCond "Profile Short � Value 0�6 � Road condition";
BA_ "GenSigStartValue" SG_ 2566860060 ProfShort_Val0_6_RoadCond 1023;
BA_ "CI_ParId" SG_ 2566860060 ProfShort_Val0_7_VarSpeedSignPos "AS107";
BA_ "CI_SigId" SG_ 2566860060 ProfShort_Val0_7_VarSpeedSignPos 10227;
BA_ "CI_SigName" SG_ 2566860060 ProfShort_Val0_7_VarSpeedSignPos "Profile Short � Value 0�7 � Variable Speed Sign Position";
BA_ "CI_ParId" SG_ 2566860060 ProfShort_Val0_8_HeadChg "AS108";
BA_ "CI_SigId" SG_ 2566860060 ProfShort_Val0_8_HeadChg 10228;
BA_ "CI_SigName" SG_ 2566860060 ProfShort_Val0_8_HeadChg "Profile Short � Value 0�8 � Heading Change";
BA_ "GenSigStartValue" SG_ 2566860060 ProfShort_Val0_8_HeadChg 254;
BA_ "CI_ParId" SG_ 2566860060 ProfShort_Val0_9_RsvdForStdTypes "AS109";
BA_ "CI_SigId" SG_ 2566860060 ProfShort_Val0_9_RsvdForStdTypes 10229;
BA_ "CI_SigName" SG_ 2566860060 ProfShort_Val0_9_RsvdForStdTypes "Profile Short � Value 0�9 � Reserved for standard types";
BA_ "GenSigStartValue" SG_ 2566860060 ProfShort_Val0_9_RsvdForStdTypes 1023;
BA_ "CI_ParId" SG_ 2566860060 ProfShort_Val0_16_RsvdForSysSpec "AS110";
BA_ "CI_SigId" SG_ 2566860060 ProfShort_Val0_16_RsvdForSysSpec 10230;
BA_ "CI_SigName" SG_ 2566860060 ProfShort_Val0_16_RsvdForSysSpec "Profile Short � Value 0�16 � Reserved for system specific types";
BA_ "GenSigStartValue" SG_ 2566860060 ProfShort_Val0_16_RsvdForSysSpec 1023;
BA_ "CI_ParId" SG_ 2566860060 ProfShort_Dist1 "AS054";
BA_ "CI_SigId" SG_ 2566860060 ProfShort_Dist1 10219;
BA_ "CI_SigName" SG_ 2566860060 ProfShort_Dist1 "Profile Short � Distance 1";
BA_ "CI_ParId" SG_ 2566860060 ProfShort_Accur "AS056";
BA_ "CI_SigId" SG_ 2566860060 ProfShort_Accur 10218;
BA_ "CI_SigName" SG_ 2566860060 ProfShort_Accur "Profile Short � Accuracy";
BA_ "GenSigStartValue" SG_ 2566860060 ProfShort_Accur 3;
BA_ "SigType" SG_ 2566860060 ProfShort_Accur 4;
BA_ "CI_ParId" SG_ 2566860060 ProfShort_Update "AS050";
BA_ "CI_SigId" SG_ 2566860060 ProfShort_Update 10214;
BA_ "CI_SigName" SG_ 2566860060 ProfShort_Update "Profile Short � Update";
BA_ "CI_ParId" SG_ 2566860060 ProfShort_Retr "AS047";
BA_ "CI_SigId" SG_ 2566860060 ProfShort_Retr 10215;
BA_ "CI_SigName" SG_ 2566860060 ProfShort_Retr "Profile Short � Retransmission";
BA_ "CI_ParId" SG_ 2566860060 ProfShort_CtrlPnt "AS052";
BA_ "CI_SigId" SG_ 2566860060 ProfShort_CtrlPnt 10216;
BA_ "CI_SigName" SG_ 2566860060 ProfShort_CtrlPnt "Profile Short � Control Point";
BA_ "CI_ParId" SG_ 2566860060 ProfShort_ProfType "AS051";
BA_ "CI_SigId" SG_ 2566860060 ProfShort_ProfType 10217;
BA_ "CI_SigName" SG_ 2566860060 ProfShort_ProfType "Profile Short � Profile Type";
BA_ "CI_ParId" SG_ 2566860060 ProfShort_PathIx "AS048";
BA_ "CI_SigId" SG_ 2566860060 ProfShort_PathIx 10212;
BA_ "CI_SigName" SG_ 2566860060 ProfShort_PathIx "Profile Short � Path Index";
BA_ "GenSigStartValue" SG_ 2566860060 ProfShort_PathIx 8;
BA_ "CI_ParId" SG_ 2566860060 ProfShort_CycCnt "AS046";
BA_ "CI_SigId" SG_ 2566860060 ProfShort_CycCnt 10213;
BA_ "CI_SigName" SG_ 2566860060 ProfShort_CycCnt "Profile Short � Cyclic Counter";
BA_ "CI_ParId" SG_ 2566860060 ProfShort_Ofs "AS049";
BA_ "CI_SigId" SG_ 2566860060 ProfShort_Ofs 10211;
BA_ "CI_SigName" SG_ 2566860060 ProfShort_Ofs "Profile Short � Offset";
BA_ "GenSigStartValue" SG_ 2566860060 ProfShort_Ofs 8191;
BA_ "CI_ParId" SG_ 2566860060 MsgType_FF2D1C "AS001";
BA_ "CI_SigId" SG_ 2566860060 MsgType_FF2D1C 10210;
BA_ "CI_SigName" SG_ 2566860060 MsgType_FF2D1C "Message Type";
BA_ "GenSigStartValue" SG_ 2566860060 MsgType_FF2D1C 6;
BA_ "CI_ParId" SG_ 2566860316 ProfLong_Val96_TimeVal "AS164";
BA_ "CI_SigId" SG_ 2566860316 ProfLong_Val96_TimeVal 44230;
BA_ "CI_SigName" SG_ 2566860316 ProfLong_Val96_TimeVal "Profile Long � Value 9 - 6 � Time Valid";
BA_ "SigType" SG_ 2566860316 ProfLong_Val96_TimeVal 4;
BA_ "CI_ParId" SG_ 2566860316 ProfLong_Val97_TimeDep "AS165";
BA_ "CI_SigId" SG_ 2566860316 ProfLong_Val97_TimeDep 44231;
BA_ "CI_SigName" SG_ 2566860316 ProfLong_Val97_TimeDep "Profile Long � Value 9 - 7 � Time Dependent";
BA_ "CI_ParId" SG_ 2566860316 ProfLong_Val93_HazardousGoods "AS161";
BA_ "CI_SigId" SG_ 2566860316 ProfLong_Val93_HazardousGoods 44227;
BA_ "CI_SigName" SG_ 2566860316 ProfLong_Val93_HazardousGoods "Profile Long � Value 9 - 3 � Hazardous Goods";
BA_ "CI_ParId" SG_ 2566860316 ProfLong_Val94_WeatherRestr "AS162";
BA_ "CI_SigId" SG_ 2566860316 ProfLong_Val94_WeatherRestr 44228;
BA_ "CI_SigName" SG_ 2566860316 ProfLong_Val94_WeatherRestr "Profile Long � Value 9 - 4 � Weather Restriction";
BA_ "CI_ParId" SG_ 2566860316 ProfLong_Val95_Type "AS163";
BA_ "CI_SigId" SG_ 2566860316 ProfLong_Val95_Type 44229;
BA_ "CI_SigName" SG_ 2566860316 ProfLong_Val95_Type "Profile Long � Value 9 - 5 � Type";
BA_ "SigType" SG_ 2566860316 ProfLong_Val95_Type 4;
BA_ "CI_ParId" SG_ 2566860316 ProfLong_Val92_Wt "AS160";
BA_ "CI_SigId" SG_ 2566860316 ProfLong_Val92_Wt 44226;
BA_ "CI_SigName" SG_ 2566860316 ProfLong_Val92_Wt "Profile Long � Value 9 - 2 � Weight";
BA_ "SigType" SG_ 2566860316 ProfLong_Val92_Wt 1;
BA_ "CI_ParId" SG_ 2566860316 ProfLong_Val1_Long "AS125";
BA_ "CI_SigId" SG_ 2566860316 ProfLong_Val1_Long 10252;
BA_ "CI_SigName" SG_ 2566860316 ProfLong_Val1_Long "Profile Long � Value 1 � Longitude";
BA_ "SigType" SG_ 2566860316 ProfLong_Val1_Long 1;
BA_ "CI_ParId" SG_ 2566860316 ProfLong_Val2_Lat "AS126";
BA_ "CI_SigId" SG_ 2566860316 ProfLong_Val2_Lat 10253;
BA_ "CI_SigName" SG_ 2566860316 ProfLong_Val2_Lat "Profile Long � Value 2 � Latitude";
BA_ "SigType" SG_ 2566860316 ProfLong_Val2_Lat 1;
BA_ "CI_ParId" SG_ 2566860316 ProfLong_Val3_Altitude "AS127";
BA_ "CI_SigId" SG_ 2566860316 ProfLong_Val3_Altitude 10254;
BA_ "CI_SigName" SG_ 2566860316 ProfLong_Val3_Altitude "Profile Long � Value 3 � Altitude";
BA_ "SigType" SG_ 2566860316 ProfLong_Val3_Altitude 1;
BA_ "CI_ParId" SG_ 2566860316 ProfLong_Val4_CtrlPntLong "AS128";
BA_ "CI_SigId" SG_ 2566860316 ProfLong_Val4_CtrlPntLong 10255;
BA_ "CI_SigName" SG_ 2566860316 ProfLong_Val4_CtrlPntLong "Profile Long � Value 4 � Control Point Longitude";
BA_ "SigType" SG_ 2566860316 ProfLong_Val4_CtrlPntLong 1;
BA_ "CI_ParId" SG_ 2566860316 ProfLong_Val5_CtrlPntLat "AS129";
BA_ "CI_SigId" SG_ 2566860316 ProfLong_Val5_CtrlPntLat 10256;
BA_ "CI_SigName" SG_ 2566860316 ProfLong_Val5_CtrlPntLat "Profile Long � Value 5 � Control Point Latitude";
BA_ "SigType" SG_ 2566860316 ProfLong_Val5_CtrlPntLat 1;
BA_ "CI_ParId" SG_ 2566860316 ProfLong_Val6_CtrlPntAltitude "AS130";
BA_ "CI_SigId" SG_ 2566860316 ProfLong_Val6_CtrlPntAltitude 10257;
BA_ "CI_SigName" SG_ 2566860316 ProfLong_Val6_CtrlPntAltitude "Profile Long � Value 6 � Control Point Altitude";
BA_ "SigType" SG_ 2566860316 ProfLong_Val6_CtrlPntAltitude 1;
BA_ "CI_ParId" SG_ 2566860316 ProfLong_Val7_LinkId "AS131";
BA_ "CI_SigId" SG_ 2566860316 ProfLong_Val7_LinkId 10258;
BA_ "CI_SigName" SG_ 2566860316 ProfLong_Val7_LinkId "Profile Long � Value 7 � Link Identifier";
BA_ "CI_ParId" SG_ 2566860316 ProfLong_Val8_TrafficSign "AS132";
BA_ "CI_SigId" SG_ 2566860316 ProfLong_Val8_TrafficSign 10259;
BA_ "CI_SigName" SG_ 2566860316 ProfLong_Val8_TrafficSign "Profile Long � Value 8 � Traffic Sign";
BA_ "CI_ParId" SG_ 2566860316 ProfLong_Val91_Speed "AS159";
BA_ "CI_SigId" SG_ 2566860316 ProfLong_Val91_Speed 44225;
BA_ "CI_SigName" SG_ 2566860316 ProfLong_Val91_Speed "Profile Long � Value 9 - 1 � Speed";
BA_ "SigType" SG_ 2566860316 ProfLong_Val91_Speed 1;
BA_ "CI_ParId" SG_ 2566860316 ProfLong_Val10_ExLane "AS134";
BA_ "CI_SigId" SG_ 2566860316 ProfLong_Val10_ExLane 10261;
BA_ "CI_SigName" SG_ 2566860316 ProfLong_Val10_ExLane "Profile Long � Value 10 � Extended Lane";
BA_ "CI_ParId" SG_ 2566860316 ProfLong_Val11_RsvdForStdTypes "AS135";
BA_ "CI_SigId" SG_ 2566860316 ProfLong_Val11_RsvdForStdTypes 10262;
BA_ "CI_SigName" SG_ 2566860316 ProfLong_Val11_RsvdForStdTypes "Profile Long � Value 11 � Reserved for standard types";
BA_ "CI_ParId" SG_ 2566860316 ProfLong_Val12_RsvdForStdTypes "AS136";
BA_ "CI_SigId" SG_ 2566860316 ProfLong_Val12_RsvdForStdTypes 10263;
BA_ "CI_SigName" SG_ 2566860316 ProfLong_Val12_RsvdForStdTypes "Profile Long � Value 12 � Reserved for standard types";
BA_ "CI_ParId" SG_ 2566860316 ProfLong_Val13_RsvdForStdTypes "AS137";
BA_ "CI_SigId" SG_ 2566860316 ProfLong_Val13_RsvdForStdTypes 10264;
BA_ "CI_SigName" SG_ 2566860316 ProfLong_Val13_RsvdForStdTypes "Profile Long � Value 13 � Reserved for standard types";
BA_ "CI_ParId" SG_ 2566860316 ProfLong_Val14_RsvdForStdTypes "AS138";
BA_ "CI_SigId" SG_ 2566860316 ProfLong_Val14_RsvdForStdTypes 10265;
BA_ "CI_SigName" SG_ 2566860316 ProfLong_Val14_RsvdForStdTypes "Profile Long � Value 14 � Reserved for standard types";
BA_ "CI_ParId" SG_ 2566860316 ProfLong_Val15_RsvdForStdTypes "AS139";
BA_ "CI_SigId" SG_ 2566860316 ProfLong_Val15_RsvdForStdTypes 10266;
BA_ "CI_SigName" SG_ 2566860316 ProfLong_Val15_RsvdForStdTypes "Profile Long � Value 15 � Reserved for standard types";
BA_ "CI_ParId" SG_ 2566860316 ProfLong_Val16_RsvdForSysSpecTyp "AS140";
BA_ "CI_SigId" SG_ 2566860316 ProfLong_Val16_RsvdForSysSpecTyp 10267;
BA_ "CI_SigName" SG_ 2566860316 ProfLong_Val16_RsvdForSysSpecTyp "Profile Long � Value 16 � Reserved for system specific types";
BA_ "CI_ParId" SG_ 2566860316 ProfLong_Val17_RsvdForSysSpecTyp "AS141";
BA_ "CI_SigId" SG_ 2566860316 ProfLong_Val17_RsvdForSysSpecTyp 10268;
BA_ "CI_SigName" SG_ 2566860316 ProfLong_Val17_RsvdForSysSpecTyp "Profile Long � Value 17 � Reserved for system specific types";
BA_ "CI_ParId" SG_ 2566860316 ProfLong_Val18_RsvdForSysSpecTyp "AS142";
BA_ "CI_SigId" SG_ 2566860316 ProfLong_Val18_RsvdForSysSpecTyp 10269;
BA_ "CI_SigName" SG_ 2566860316 ProfLong_Val18_RsvdForSysSpecTyp "Profile Long � Value 18 � Reserved for system specific types";
BA_ "CI_ParId" SG_ 2566860316 ProfLong_Val19_RsvdForSysSpecTyp "AS143";
BA_ "CI_SigId" SG_ 2566860316 ProfLong_Val19_RsvdForSysSpecTyp 10270;
BA_ "CI_SigName" SG_ 2566860316 ProfLong_Val19_RsvdForSysSpecTyp "Profile Long � Value 19 � Reserved for system specific types";
BA_ "CI_ParId" SG_ 2566860316 ProfLong_Val20_RsvdForSysSpecTyp "AS144";
BA_ "CI_SigId" SG_ 2566860316 ProfLong_Val20_RsvdForSysSpecTyp 10271;
BA_ "CI_SigName" SG_ 2566860316 ProfLong_Val20_RsvdForSysSpecTyp "Profile Long � Value 20 � Reserved for system specific types";
BA_ "CI_ParId" SG_ 2566860316 ProfLong_Val21_RsvdForSysSpecTyp "AS145";
BA_ "CI_SigId" SG_ 2566860316 ProfLong_Val21_RsvdForSysSpecTyp 10272;
BA_ "CI_SigName" SG_ 2566860316 ProfLong_Val21_RsvdForSysSpecTyp "Profile Long � Value 21 � Reserved for system specific types";
BA_ "CI_ParId" SG_ 2566860316 ProfLong_Val22_RsvdForSysSpecTyp "AS146";
BA_ "CI_SigId" SG_ 2566860316 ProfLong_Val22_RsvdForSysSpecTyp 10273;
BA_ "CI_SigName" SG_ 2566860316 ProfLong_Val22_RsvdForSysSpecTyp "Profile Long � Value 22 � Reserved for system specific types";
BA_ "CI_ParId" SG_ 2566860316 ProfLong_Val23_RsvdForSysSpecTyp "AS147";
BA_ "CI_SigId" SG_ 2566860316 ProfLong_Val23_RsvdForSysSpecTyp 10274;
BA_ "CI_SigName" SG_ 2566860316 ProfLong_Val23_RsvdForSysSpecTyp "Profile Long � Value 23 � Reserved for system specific types";
BA_ "CI_ParId" SG_ 2566860316 ProfLong_Val24_RsvdForSysSpecTyp "AS148";
BA_ "CI_SigId" SG_ 2566860316 ProfLong_Val24_RsvdForSysSpecTyp 10275;
BA_ "CI_SigName" SG_ 2566860316 ProfLong_Val24_RsvdForSysSpecTyp "Profile Long � Value 24 � Reserved for system specific types";
BA_ "CI_ParId" SG_ 2566860316 ProfLong_Val25_RsvdForSysSpecTyp "AS149";
BA_ "CI_SigId" SG_ 2566860316 ProfLong_Val25_RsvdForSysSpecTyp 10276;
BA_ "CI_SigName" SG_ 2566860316 ProfLong_Val25_RsvdForSysSpecTyp "Profile Long � Value 25 � Reserved for system specific types";
BA_ "CI_ParId" SG_ 2566860316 ProfLong_Val26_RsvdForSysSpecTyp "AS150";
BA_ "CI_SigId" SG_ 2566860316 ProfLong_Val26_RsvdForSysSpecTyp 10277;
BA_ "CI_SigName" SG_ 2566860316 ProfLong_Val26_RsvdForSysSpecTyp "Profile Long � Value 26 � Reserved for system specific types";
BA_ "CI_ParId" SG_ 2566860316 ProfLong_Val27_RsvdForSysSpecTyp "AS151";
BA_ "CI_SigId" SG_ 2566860316 ProfLong_Val27_RsvdForSysSpecTyp 10278;
BA_ "CI_SigName" SG_ 2566860316 ProfLong_Val27_RsvdForSysSpecTyp "Profile Long � Value 27 � Reserved for system specific types";
BA_ "CI_ParId" SG_ 2566860316 ProfLong_Val28_RsvdForSysSpecTyp "AS152";
BA_ "CI_SigId" SG_ 2566860316 ProfLong_Val28_RsvdForSysSpecTyp 10279;
BA_ "CI_SigName" SG_ 2566860316 ProfLong_Val28_RsvdForSysSpecTyp "Profile Long � Value 28 � Reserved for system specific types";
BA_ "CI_ParId" SG_ 2566860316 ProfLong_Val29_RsvdForSysSpecTyp "AS153";
BA_ "CI_SigId" SG_ 2566860316 ProfLong_Val29_RsvdForSysSpecTyp 10280;
BA_ "CI_SigName" SG_ 2566860316 ProfLong_Val29_RsvdForSysSpecTyp "Profile Long � Value 29 � Reserved for system specific types";
BA_ "CI_ParId" SG_ 2566860316 ProfLong_Val30_RsvdForSysSpecTyp "AS154";
BA_ "CI_SigId" SG_ 2566860316 ProfLong_Val30_RsvdForSysSpecTyp 10281;
BA_ "CI_SigName" SG_ 2566860316 ProfLong_Val30_RsvdForSysSpecTyp "Profile Long � Value 30 � Reserved for system specific types";
BA_ "CI_ParId" SG_ 2566860316 ProfLong_Val31_RsvdForSysSpecTyp "AS155";
BA_ "CI_SigId" SG_ 2566860316 ProfLong_Val31_RsvdForSysSpecTyp 10282;
BA_ "CI_SigName" SG_ 2566860316 ProfLong_Val31_RsvdForSysSpecTyp "Profile Long � Value 31 � Reserved for system specific types";
BA_ "CI_ParId" SG_ 2566860316 ProfLong_Update "AS061";
BA_ "CI_SigId" SG_ 2566860316 ProfLong_Update 10247;
BA_ "CI_SigName" SG_ 2566860316 ProfLong_Update "Profile Long � Update";
BA_ "CI_ParId" SG_ 2566860316 ProfLong_Retr "AS058";
BA_ "CI_SigId" SG_ 2566860316 ProfLong_Retr 10248;
BA_ "CI_SigName" SG_ 2566860316 ProfLong_Retr "Profile Long � Retransmission";
BA_ "CI_ParId" SG_ 2566860316 ProfLong_CtrlPnt "AS063";
BA_ "CI_SigId" SG_ 2566860316 ProfLong_CtrlPnt 10249;
BA_ "CI_SigName" SG_ 2566860316 ProfLong_CtrlPnt "Profile Long � Control Point";
BA_ "CI_ParId" SG_ 2566860316 ProfLong_ProfType "AS062";
BA_ "CI_SigId" SG_ 2566860316 ProfLong_ProfType 10250;
BA_ "CI_SigName" SG_ 2566860316 ProfLong_ProfType "Profile Long � Profile Type";
BA_ "CI_ParId" SG_ 2566860316 ProfLong_PathIx "AS059";
BA_ "CI_SigId" SG_ 2566860316 ProfLong_PathIx 10245;
BA_ "CI_SigName" SG_ 2566860316 ProfLong_PathIx "Profile Long � Path Index";
BA_ "GenSigStartValue" SG_ 2566860316 ProfLong_PathIx 8;
BA_ "CI_ParId" SG_ 2566860316 ProfLong_CycCnt "AS057";
BA_ "CI_SigId" SG_ 2566860316 ProfLong_CycCnt 10246;
BA_ "CI_SigName" SG_ 2566860316 ProfLong_CycCnt "Profile Long � Cyclic Counter";
BA_ "CI_ParId" SG_ 2566860316 ProfLong_Ofs "AS060";
BA_ "CI_SigId" SG_ 2566860316 ProfLong_Ofs 10244;
BA_ "CI_SigName" SG_ 2566860316 ProfLong_Ofs "Profile Long � Offset";
BA_ "GenSigStartValue" SG_ 2566860316 ProfLong_Ofs 8191;
BA_ "CI_ParId" SG_ 2566860316 MsgType_FF2E1C "AS001";
BA_ "CI_SigId" SG_ 2566860316 MsgType_FF2E1C 10243;
BA_ "CI_SigName" SG_ 2566860316 MsgType_FF2E1C "Message Type";
BA_ "GenSigStartValue" SG_ 2566860316 MsgType_FF2E1C 6;
BA_ "CI_ParId" SG_ 2566860572 Meta_MinorProtoVer "AS075";
BA_ "CI_SigId" SG_ 2566860572 Meta_MinorProtoVer 10295;
BA_ "CI_SigName" SG_ 2566860572 Meta_MinorProtoVer "Meta-Data � Minor Protocol Version";
BA_ "GenSigTimeoutTime_SGW" SG_ 2566860572 Meta_MinorProtoVer 25000;
BA_ "CI_ParId" SG_ 2566860572 Meta_SpeedUnits "AS073";
BA_ "CI_SigId" SG_ 2566860572 Meta_SpeedUnits 10296;
BA_ "CI_SigName" SG_ 2566860572 Meta_SpeedUnits "Meta-Data � Speed Units";
BA_ "GenSigTimeoutTime_SGW" SG_ 2566860572 Meta_SpeedUnits 25000;
BA_ "CI_ParId" SG_ 2566860572 Meta_MapVerYr "AS079";
BA_ "CI_SigId" SG_ 2566860572 Meta_MapVerYr 10293;
BA_ "CI_SigName" SG_ 2566860572 Meta_MapVerYr "Meta-Data � Map Version - Year";
BA_ "GenSigTimeoutTime_SGW" SG_ 2566860572 Meta_MapVerYr 25000;
BA_ "CI_ParId" SG_ 2566860572 Meta_MapVerQtr "AS080";
BA_ "CI_SigId" SG_ 2566860572 Meta_MapVerQtr 10294;
BA_ "CI_SigName" SG_ 2566860572 Meta_MapVerQtr "Meta-Data � Map Version - Year Quarter";
BA_ "GenSigTimeoutTime_SGW" SG_ 2566860572 Meta_MapVerQtr 25000;
BA_ "CI_ParId" SG_ 2566860572 Meta_RegionCode "AS071";
BA_ "CI_SigId" SG_ 2566860572 Meta_RegionCode 10292;
BA_ "CI_SigName" SG_ 2566860572 Meta_RegionCode "Meta-Data � Region Code";
BA_ "GenSigStartValue" SG_ 2566860572 Meta_RegionCode 32767;
BA_ "GenSigTimeoutTime_SGW" SG_ 2566860572 Meta_RegionCode 25000;
BA_ "CI_ParId" SG_ 2566860572 Meta_DrivSide "AS072";
BA_ "CI_SigId" SG_ 2566860572 Meta_DrivSide 10291;
BA_ "CI_SigName" SG_ 2566860572 Meta_DrivSide "Meta-Data � Driving Side";
BA_ "GenSigStartValue" SG_ 2566860572 Meta_DrivSide 1;
BA_ "GenSigTimeoutTime_SGW" SG_ 2566860572 Meta_DrivSide 25000;
BA_ "CI_ParId" SG_ 2566860572 Meta_HwVer "AS077";
BA_ "CI_SigId" SG_ 2566860572 Meta_HwVer 10290;
BA_ "CI_SigName" SG_ 2566860572 Meta_HwVer "Meta-Data � Hardware Version";
BA_ "GenSigTimeoutTime_SGW" SG_ 2566860572 Meta_HwVer 25000;
BA_ "CI_ParId" SG_ 2566860572 Meta_MinorProtoSubVer "AS076";
BA_ "CI_SigId" SG_ 2566860572 Meta_MinorProtoSubVer 10287;
BA_ "CI_SigName" SG_ 2566860572 Meta_MinorProtoSubVer "Meta-Data � Minor Protocol Sub-Version";
BA_ "GenSigTimeoutTime_SGW" SG_ 2566860572 Meta_MinorProtoSubVer 25000;
BA_ "CI_ParId" SG_ 2566860572 Meta_MajorProtoVer "AS074";
BA_ "CI_SigId" SG_ 2566860572 Meta_MajorProtoVer 10288;
BA_ "CI_SigName" SG_ 2566860572 Meta_MajorProtoVer "Meta-Data � Major Protocol Version";
BA_ "GenSigTimeoutTime_SGW" SG_ 2566860572 Meta_MajorProtoVer 25000;
BA_ "CI_ParId" SG_ 2566860572 Meta_CycCnt "AS069";
BA_ "CI_SigId" SG_ 2566860572 Meta_CycCnt 10289;
BA_ "CI_SigName" SG_ 2566860572 Meta_CycCnt "Meta-Data � Cyclic Counter";
BA_ "GenSigTimeoutTime_SGW" SG_ 2566860572 Meta_CycCnt 25000;
BA_ "CI_ParId" SG_ 2566860572 Meta_CntryCode "AS070";
BA_ "CI_SigId" SG_ 2566860572 Meta_CntryCode 10286;
BA_ "CI_SigName" SG_ 2566860572 Meta_CntryCode "Meta-Data � Country Code";
BA_ "GenSigTimeoutTime_SGW" SG_ 2566860572 Meta_CntryCode 25000;
BA_ "CI_ParId" SG_ 2566860572 Meta_MapProvider "AS078";
BA_ "CI_SigId" SG_ 2566860572 Meta_MapProvider 10285;
BA_ "CI_SigName" SG_ 2566860572 Meta_MapProvider "Meta-Data � Map Provider";
BA_ "GenSigStartValue" SG_ 2566860572 Meta_MapProvider 7;
BA_ "GenSigTimeoutTime_SGW" SG_ 2566860572 Meta_MapProvider 25000;
BA_ "CI_ParId" SG_ 2566860572 MsgType_FF2F1C "AS001";
BA_ "CI_SigId" SG_ 2566860572 MsgType_FF2F1C 10284;
BA_ "CI_SigName" SG_ 2566860572 MsgType_FF2F1C "Message Type";
BA_ "GenSigStartValue" SG_ 2566860572 MsgType_FF2F1C 6;
BA_ "GenSigTimeoutTime_SGW" SG_ 2566860572 MsgType_FF2F1C 25000;
BA_ "CI_ParId" SG_ 2283315200 BatStsOfFunct "ID2039";
BA_ "CI_SigId" SG_ 2283315200 BatStsOfFunct 40251;
BA_ "CI_SigName" SG_ 2283315200 BatStsOfFunct "Battery State Of Function";
BA_ "GenSigTimeoutTime_PCM" SG_ 2283315200 BatStsOfFunct 2500;
BA_ "CI_ParId" SG_ 2283315200 BatRecalibration "ID2040";
BA_ "CI_SigId" SG_ 2283315200 BatRecalibration 40250;
BA_ "CI_SigName" SG_ 2283315200 BatRecalibration "Battery Recalibration";
BA_ "GenSigTimeoutTime_PCM" SG_ 2283315200 BatRecalibration 2500;
BA_ "CI_ParId" SG_ 2283315200 BcmSamFailSts "ID0202";
BA_ "CI_SigId" SG_ 2283315200 BcmSamFailSts 29673;
BA_ "CI_SigName" SG_ 2283315200 BcmSamFailSts "BCM SAM Fail Sts";
BA_ "GenSigTimeoutTime_PCM" SG_ 2283315200 BcmSamFailSts 2500;
BA_ "CI_ParId" SG_ 2283315200 IbsFail "ID0201";
BA_ "CI_SigId" SG_ 2283315200 IbsFail 29674;
BA_ "CI_SigName" SG_ 2283315200 IbsFail "IBS Fail Status";
BA_ "GenSigTimeoutTime_PCM" SG_ 2283315200 IbsFail 2500;
BA_ "CI_ParId" SG_ 2283315200 BatTemp "ID0200";
BA_ "CI_SigId" SG_ 2283315200 BatTemp 29672;
BA_ "CI_SigName" SG_ 2283315200 BatTemp "Battery Temperature";
BA_ "GenSigStartValue" SG_ 2283315200 BatTemp 55;
BA_ "GenSigTimeoutTime_PCM" SG_ 2283315200 BatTemp 2500;
BA_ "CI_ParId" SG_ 2283315200 BatCurLev "ID0199";
BA_ "CI_SigId" SG_ 2283315200 BatCurLev 29671;
BA_ "CI_SigName" SG_ 2283315200 BatCurLev "Battery Current Level";
BA_ "GenSigStartValue" SG_ 2283315200 BatCurLev 2500;
BA_ "GenSigTimeoutTime_PCM" SG_ 2283315200 BatCurLev 2500;
BA_ "CI_ParId" SG_ 2283315200 VMax "ID0198";
BA_ "CI_SigId" SG_ 2283315200 VMax 29670;
BA_ "CI_SigName" SG_ 2283315200 VMax "Voltage Max";
BA_ "GenSigStartValue" SG_ 2283315200 VMax 156;
BA_ "GenSigTimeoutTime_PCM" SG_ 2283315200 VMax 2500;
BA_ "SigType" SG_ 2283315200 VMax 1;
BA_ "CI_ParId" SG_ 2283315200 VMin "ID0197";
BA_ "CI_SigId" SG_ 2283315200 VMin 29669;
BA_ "CI_SigName" SG_ 2283315200 VMin "Voltage Min";
BA_ "GenSigStartValue" SG_ 2283315200 VMin 76;
BA_ "GenSigTimeoutTime_PCM" SG_ 2283315200 VMin 2500;
BA_ "SigType" SG_ 2283315200 VMin 1;
BA_ "CI_ParId" SG_ 2283315200 BatSoc "ID0196";
BA_ "CI_SigId" SG_ 2283315200 BatSoc 29668;
BA_ "CI_SigName" SG_ 2283315200 BatSoc "Battery State Of Charge";
BA_ "GenSigStartValue" SG_ 2283315200 BatSoc 80;
BA_ "GenSigTimeoutTime_PCM" SG_ 2283315200 BatSoc 2500;
BA_ "CI_ParId" SG_ 2283315200 BatVLevHp "ID0195";
BA_ "CI_SigId" SG_ 2283315200 BatVLevHp 29667;
BA_ "CI_SigName" SG_ 2283315200 BatVLevHp "Battery Voltage Level HP";
BA_ "GenSigStartValue" SG_ 2283315200 BatVLevHp 396;
BA_ "GenSigTimeoutTime_PCM" SG_ 2283315200 BatVLevHp 2500;
BA_ "CI_ParId" SG_ 2566886433 InternRes "ID2444";
BA_ "CI_SigId" SG_ 2566886433 InternRes 44466;
BA_ "CI_SigName" SG_ 2566886433 InternRes "Internal Resistance";
BA_ "GenSigTimeoutTime_PCM" SG_ 2566886433 InternRes 5000;
BA_ "SigType" SG_ 2566886433 InternRes 1;
BA_ "CI_ParId" SG_ 2566886433 BatSohV "ID2443";
BA_ "CI_SigId" SG_ 2566886433 BatSohV 44465;
BA_ "CI_SigName" SG_ 2566886433 BatSohV "Battery SOH V";
BA_ "GenSigTimeoutTime_PCM" SG_ 2566886433 BatSohV 5000;
BA_ "SigType" SG_ 2566886433 BatSohV 1;
BA_ "CI_ParId" SG_ 2566886433 BatSohLam "ID2442";
BA_ "CI_SigId" SG_ 2566886433 BatSohLam 44464;
BA_ "CI_SigName" SG_ 2566886433 BatSohLam "Battery SOH LAM";
BA_ "GenSigTimeoutTime_PCM" SG_ 2566886433 BatSohLam 5000;
BA_ "SigType" SG_ 2566886433 BatSohLam 1;
BA_ "CI_ParId" SG_ 2566886433 BatSoh "ID2441";
BA_ "CI_SigId" SG_ 2566886433 BatSoh 44463;
BA_ "CI_SigName" SG_ 2566886433 BatSoh "Battery SOH";
BA_ "GenSigTimeoutTime_PCM" SG_ 2566886433 BatSoh 5000;
BA_ "SigType" SG_ 2566886433 BatSoh 1;
BA_ "CI_ParId" SG_ 2566873377 MsgCks_FF6121 "4207";
BA_ "CI_SigId" SG_ 2566873377 MsgCks_FF6121 40291;
BA_ "CI_SigName" SG_ 2566873377 MsgCks_FF6121 "Message Checksum";
BA_ "GenSigTimeoutTime_PCM" SG_ 2566873377 MsgCks_FF6121 500;
BA_ "SPN" SG_ 2566873377 MsgCks_FF6121 4207;
BA_ "CI_ParId" SG_ 2566873377 MsgCnt4 "ID2047";
BA_ "CI_SigId" SG_ 2566873377 MsgCnt4 40290;
BA_ "CI_SigName" SG_ 2566873377 MsgCnt4 "Message Counter 4 bit";
BA_ "GenSigTimeoutTime_PCM" SG_ 2566873377 MsgCnt4 500;
BA_ "CI_ParId" SG_ 2566873377 HandbrakeFullyExSw "ID0976";
BA_ "CI_SigId" SG_ 2566873377 HandbrakeFullyExSw 35246;
BA_ "CI_SigName" SG_ 2566873377 HandbrakeFullyExSw "Handbrake Fully Extended Switch";
BA_ "GenSigTimeoutTime_PCM" SG_ 2566873377 HandbrakeFullyExSw 500;
BA_ "SigType" SG_ 2566873377 HandbrakeFullyExSw 4;
BA_ "CI_ParId" SG_ 2566873377 EngAuxShutdnSw "970";
BA_ "CI_SigId" SG_ 2566873377 EngAuxShutdnSw 11512;
BA_ "CI_SigName" SG_ 2566873377 EngAuxShutdnSw "Engine Auxiliary Shutdown Switch";
BA_ "GenSigTimeoutTime_PCM" SG_ 2566873377 EngAuxShutdnSw 500;
BA_ "SPN" SG_ 2566873377 EngAuxShutdnSw 970;
BA_ "SigType" SG_ 2566873377 EngAuxShutdnSw 4;
BA_ "CI_ParId" SG_ 2566873377 Vsl2Req "I003";
BA_ "CI_SigId" SG_ 2566873377 Vsl2Req 11508;
BA_ "CI_SigName" SG_ 2566873377 Vsl2Req "Second Vehicle Speed Limit Request";
BA_ "GenSigTimeoutTime_PCM" SG_ 2566873377 Vsl2Req 500;
BA_ "SigType" SG_ 2566873377 Vsl2Req 4;
BA_ "CI_ParId" SG_ 2566873377 VslaReq "I106";
BA_ "CI_SigId" SG_ 2566873377 VslaReq 11507;
BA_ "CI_SigName" SG_ 2566873377 VslaReq "Adjustable Vehicle Speed Limitation Request";
BA_ "GenSigTimeoutTime_PCM" SG_ 2566873377 VslaReq 500;
BA_ "SigType" SG_ 2566873377 VslaReq 4;
BA_ "CI_ParId" SG_ 2566873377 CltOpenSw "ID0162";
BA_ "CI_SigId" SG_ 2566873377 CltOpenSw 11506;
BA_ "CI_SigName" SG_ 2566873377 CltOpenSw "Clutch Open Switch";
BA_ "GenSigTimeoutTime_PCM" SG_ 2566873377 CltOpenSw 500;
BA_ "SigType" SG_ 2566873377 CltOpenSw 4;
BA_ "CI_ParId" SG_ 2566873377 MsgCnt_FF6121 "I899";
BA_ "CI_SigId" SG_ 2566873377 MsgCnt_FF6121 11505;
BA_ "CI_SigName" SG_ 2566873377 MsgCnt_FF6121 "Message Counter (2 bits)";
BA_ "GenSigTimeoutTime_PCM" SG_ 2566873377 MsgCnt_FF6121 500;
BA_ "SigType" SG_ 2566873377 MsgCnt_FF6121 4;
BA_ "CI_ParId" SG_ 2566873377 CltSw "598";
BA_ "CI_SigId" SG_ 2566873377 CltSw 11503;
BA_ "CI_SigName" SG_ 2566873377 CltSw "Clutch Switch";
BA_ "GenSigTimeoutTime_PCM" SG_ 2566873377 CltSw 500;
BA_ "SPN" SG_ 2566873377 CltSw 598;
BA_ "SigType" SG_ 2566873377 CltSw 4;
BA_ "CI_ParId" SG_ 2566873377 RedBrkSw "I044";
BA_ "CI_SigId" SG_ 2566873377 RedBrkSw 11500;
BA_ "CI_SigName" SG_ 2566873377 RedBrkSw "Redundant Brake Switch";
BA_ "GenSigTimeoutTime_PCM" SG_ 2566873377 RedBrkSw 500;
BA_ "SigType" SG_ 2566873377 RedBrkSw 4;
BA_ "CI_ParId" SG_ 2566722889 BatChg1OutCur "4993";
BA_ "CI_SigId" SG_ 2566722889 BatChg1OutCur 33791;
BA_ "CI_SigName" SG_ 2566722889 BatChg1OutCur "Battery Charger 1 Output Current";
BA_ "GenSigTimeoutTime_PCM" SG_ 2566722889 BatChg1OutCur 5000;
BA_ "SPN" SG_ 2566722889 BatChg1OutCur 4993;
BA_ "SigType" SG_ 2566722889 BatChg1OutCur 1;
BA_ "CI_ParId" SG_ 2566722889 BatChg1OutV "4992";
BA_ "CI_SigId" SG_ 2566722889 BatChg1OutV 33790;
BA_ "CI_SigName" SG_ 2566722889 BatChg1OutV "Battery Charger 1 Output Voltage";
BA_ "GenSigTimeoutTime_PCM" SG_ 2566722889 BatChg1OutV 5000;
BA_ "SPN" SG_ 2566722889 BatChg1OutV 4992;
BA_ "SigType" SG_ 2566722889 BatChg1OutV 1;
BA_ "CI_ParId" SG_ 2566722889 BatChg1Sts "4990";
BA_ "CI_SigId" SG_ 2566722889 BatChg1Sts 33788;
BA_ "CI_SigName" SG_ 2566722889 BatChg1Sts "Battery Charger 1 State";
BA_ "GenSigTimeoutTime_PCM" SG_ 2566722889 BatChg1Sts 5000;
BA_ "SPN" SG_ 2566722889 BatChg1Sts 4990;
BA_ "CI_ParId" SG_ 2566723351 AllAirbagDeactSwSts "ID2366";
BA_ "CI_SigId" SG_ 2566723351 AllAirbagDeactSwSts 43104;
BA_ "CI_SigName" SG_ 2566723351 AllAirbagDeactSwSts "All Airbag Deactivation Switch Status";
BA_ "GenSigSendType" SG_ 2566723351 AllAirbagDeactSwSts 3;
BA_ "GenSigTimeoutTime_PCM" SG_ 2566723351 AllAirbagDeactSwSts 1250;
BA_ "SigType" SG_ 2566723351 AllAirbagDeactSwSts 4;
BA_ "CI_ParId" SG_ 2566723351 PassAirbagDeactSwSts "4962";
BA_ "CI_SigId" SG_ 2566723351 PassAirbagDeactSwSts 4404;
BA_ "CI_SigName" SG_ 2566723351 PassAirbagDeactSwSts "Passenger Airbag Deactivation Switch Status";
BA_ "GenSigSendType" SG_ 2566723351 PassAirbagDeactSwSts 3;
BA_ "GenSigTimeoutTime_PCM" SG_ 2566723351 PassAirbagDeactSwSts 1250;
BA_ "SPN" SG_ 2566723351 PassAirbagDeactSwSts 4962;
BA_ "SigType" SG_ 2566723351 PassAirbagDeactSwSts 4;
BA_ "CI_ParId" SG_ 2566723361 PassBeltlockSts "4953";
BA_ "CI_SigId" SG_ 2566723361 PassBeltlockSts 4407;
BA_ "CI_SigName" SG_ 2566723361 PassBeltlockSts "Passenger Beltlock Status";
BA_ "GenSigSendType" SG_ 2566723361 PassBeltlockSts 3;
BA_ "GenSigTimeoutTime_PCM" SG_ 2566723361 PassBeltlockSts 1250;
BA_ "SPN" SG_ 2566723361 PassBeltlockSts 4953;
BA_ "SigType" SG_ 2566723361 PassBeltlockSts 4;
BA_ "CI_ParId" SG_ 2566723361 DrivBeltlockSts "4952";
BA_ "CI_SigId" SG_ 2566723361 DrivBeltlockSts 4406;
BA_ "CI_SigName" SG_ 2566723361 DrivBeltlockSts "Driver Beltlock Status";
BA_ "GenSigSendType" SG_ 2566723361 DrivBeltlockSts 3;
BA_ "GenSigTimeoutTime_PCM" SG_ 2566723361 DrivBeltlockSts 1250;
BA_ "SPN" SG_ 2566723361 DrivBeltlockSts 4952;
BA_ "SigType" SG_ 2566723361 DrivBeltlockSts 4;
VAL_ 2565406709 Pgn_Ack_E8FFF5 37120 "VLSI1" 40448 "DM29" 41216 "DM33" 41728 "DM31" 41984 "DM30" 47360 "PLLT (Plan List Lifetime)" 47872 "PLD (Plan List Distance)" 49408 "DM21" 49664 "DM20" 49920 "DM22" 53504 "MaintBcIc" 54016 "DM19" 60928 "ACL" 61184 "STOD" 64341 "HVESP3HIST" 64342 "HVESP3CFG" 64343 "HVESP2HIST" 64344 "HVESP2CFG" 64345 "HVESP1HIST" 64346 "HVESP1CFG" 64529 "TGFI" 64579 "TCSI" 64582 "TSIS" 64583 "MTI" 64605 "HVESSCFG" 64606 "HVESSHIST" 64653 "PII" 64701 "A1SCRSI2" 64782 "AT1OGC2" 64784 "AT1IGC2" 64839 "TML" 64879 "EEC8" 64896 "DM28" 64905 "VDS2" 64906 "J2012" 64912 "AETC" 64920 "AT1HI1" 64949 "DM23" 64950 "DM24" 64951 "DM25" 64952 "DM26" 64953 "TPRI" 64965 "ECUID" 64981 "EEC5" 65039 "LC" 65099 "TCFG2" 65109 "GFD" 65127 "CCC" 65131 "DI" 65136 "CVW" 65144 "TP1" 65145 "TP2" 65146 "TP3" 65195 "ETC6" 65196 "EBC4" 65199 "GFC" 65201 "EH" 65202 "GFI1" 65203 "LFI1" 65208 "GTFI" 65212 "CBI" 65214 "EEC4" 65216 "SERV" 65219 "ETC5" 65221 "ETC4" 65223 "ETC3" 65227 "DM02" 65228 "DM03" 65229 "DM04" 65230 "DM05" 65231 "DM06" 65234 "DM10" 65235 "DM11" 65236 "DM12" 65242 "SOFT" 65244 "IO" 65248 "VD" 65250 "TCFG" 65253 "HOURS" 65254 "TD" 65255 "VH" 65256 "VDS" 65257 "LFC1" 65258 "VW" 65259 "CI" 65260 "VI" 65261 "CCSS" 65284 "PB_DriversConsentOnPersonalData" 65340 "PB_HVESSCFG" 65376 "VehCfg" 65413 "PB_3CT" 65482 "PB_ID1" 65484 "PB_VNS" 65502 "Av2" 65520 "SCh" 65521 "DIS" 65524 "PB_IVA" ;
VAL_ 2565406709 Pgn_Nack_E8FFF5 37120 "VLSI1" 40448 "DM29" 41216 "DM33" 41728 "DM31" 41984 "DM30" 47360 "PLLT (Plan List Lifetime)" 47872 "PLD (Plan List Distance)" 49408 "DM21" 49664 "DM20" 49920 "DM22" 53504 "MaintBcIc" 54016 "DM19" 60928 "ACL" 61184 "STOD" 64341 "HVESP3HIST" 64342 "HVESP3CFG" 64343 "HVESP2HIST" 64344 "HVESP2CFG" 64345 "HVESP1HIST" 64346 "HVESP1CFG" 64529 "TGFI" 64579 "TCSI" 64582 "TSIS" 64583 "MTI" 64605 "HVESSCFG" 64606 "HVESSHIST" 64653 "PII" 64701 "A1SCRSI2" 64782 "AT1OGC2" 64784 "AT1IGC2" 64839 "TML" 64879 "EEC8" 64896 "DM28" 64905 "VDS2" 64906 "J2012" 64912 "AETC" 64920 "AT1HI1" 64949 "DM23" 64950 "DM24" 64951 "DM25" 64952 "DM26" 64953 "TPRI" 64965 "ECUID" 64981 "EEC5" 65039 "LC" 65099 "TCFG2" 65109 "GFD" 65127 "CCC" 65131 "DI" 65136 "CVW" 65144 "TP1" 65145 "TP2" 65146 "TP3" 65195 "ETC6" 65196 "EBC4" 65199 "GFC" 65201 "EH" 65202 "GFI1" 65203 "LFI1" 65208 "GTFI" 65212 "CBI" 65214 "EEC4" 65216 "SERV" 65219 "ETC5" 65221 "ETC4" 65223 "ETC3" 65227 "DM02" 65228 "DM03" 65229 "DM04" 65230 "DM05" 65231 "DM06" 65234 "DM10" 65235 "DM11" 65236 "DM12" 65242 "SOFT" 65244 "IO" 65248 "VD" 65250 "TCFG" 65253 "HOURS" 65254 "TD" 65255 "VH" 65256 "VDS" 65257 "LFC1" 65258 "VW" 65259 "CI" 65260 "VI" 65261 "CCSS" 65284 "PB_DriversConsentOnPersonalData" 65340 "PB_HVESSCFG" 65376 "VehCfg" 65413 "PB_3CT" 65482 "PB_ID1" 65484 "PB_VNS" 65502 "Av2" 65520 "SCh" 65521 "DIS" 65524 "PB_IVA" ;
VAL_ 2565406709 Pgn_Ad_E8FFF5 37120 "VLSI1" 40448 "DM29" 41216 "DM33" 41728 "DM31" 41984 "DM30" 47360 "PLLT (Plan List Lifetime)" 47872 "PLD (Plan List Distance)" 49408 "DM21" 49664 "DM20" 49920 "DM22" 53504 "MaintBcIc" 54016 "DM19" 60928 "ACL" 61184 "STOD" 64341 "HVESP3HIST" 64342 "HVESP3CFG" 64343 "HVESP2HIST" 64344 "HVESP2CFG" 64345 "HVESP1HIST" 64346 "HVESP1CFG" 64529 "TGFI" 64579 "TCSI" 64582 "TSIS" 64583 "MTI" 64605 "HVESSCFG" 64606 "HVESSHIST" 64653 "PII" 64701 "A1SCRSI2" 64782 "AT1OGC2" 64784 "AT1IGC2" 64839 "TML" 64879 "EEC8" 64896 "DM28" 64905 "VDS2" 64906 "J2012" 64912 "AETC" 64920 "AT1HI1" 64949 "DM23" 64950 "DM24" 64951 "DM25" 64952 "DM26" 64953 "TPRI" 64965 "ECUID" 64981 "EEC5" 65039 "LC" 65099 "TCFG2" 65109 "GFD" 65127 "CCC" 65131 "DI" 65136 "CVW" 65144 "TP1" 65145 "TP2" 65146 "TP3" 65195 "ETC6" 65196 "EBC4" 65199 "GFC" 65201 "EH" 65202 "GFI1" 65203 "LFI1" 65208 "GTFI" 65212 "CBI" 65214 "EEC4" 65216 "SERV" 65219 "ETC5" 65221 "ETC4" 65223 "ETC3" 65227 "DM02" 65228 "DM03" 65229 "DM04" 65230 "DM05" 65231 "DM06" 65234 "DM10" 65235 "DM11" 65236 "DM12" 65242 "SOFT" 65244 "IO" 65248 "VD" 65250 "TCFG" 65253 "HOURS" 65254 "TD" 65255 "VH" 65256 "VDS" 65257 "LFC1" 65258 "VW" 65259 "CI" 65260 "VI" 65261 "CCSS" 65284 "PB_DriversConsentOnPersonalData" 65340 "PB_HVESSCFG" 65376 "VehCfg" 65413 "PB_3CT" 65482 "PB_ID1" 65484 "PB_VNS" 65502 "Av2" 65520 "SCh" 65521 "DIS" 65524 "PB_IVA" ;
VAL_ 2565406709 Pgn_Busy_E8FFF5 37120 "VLSI1" 40448 "DM29" 41216 "DM33" 41728 "DM31" 41984 "DM30" 47360 "PLLT (Plan List Lifetime)" 47872 "PLD (Plan List Distance)" 49408 "DM21" 49664 "DM20" 49920 "DM22" 53504 "MaintBcIc" 54016 "DM19" 60928 "ACL" 61184 "STOD" 64341 "HVESP3HIST" 64342 "HVESP3CFG" 64343 "HVESP2HIST" 64344 "HVESP2CFG" 64345 "HVESP1HIST" 64346 "HVESP1CFG" 64529 "TGFI" 64579 "TCSI" 64582 "TSIS" 64583 "MTI" 64605 "HVESSCFG" 64606 "HVESSHIST" 64653 "PII" 64701 "A1SCRSI2" 64782 "AT1OGC2" 64784 "AT1IGC2" 64839 "TML" 64879 "EEC8" 64896 "DM28" 64905 "VDS2" 64906 "J2012" 64912 "AETC" 64920 "AT1HI1" 64949 "DM23" 64950 "DM24" 64951 "DM25" 64952 "DM26" 64953 "TPRI" 64965 "ECUID" 64981 "EEC5" 65039 "LC" 65099 "TCFG2" 65109 "GFD" 65127 "CCC" 65131 "DI" 65136 "CVW" 65144 "TP1" 65145 "TP2" 65146 "TP3" 65195 "ETC6" 65196 "EBC4" 65199 "GFC" 65201 "EH" 65202 "GFI1" 65203 "LFI1" 65208 "GTFI" 65212 "CBI" 65214 "EEC4" 65216 "SERV" 65219 "ETC5" 65221 "ETC4" 65223 "ETC3" 65227 "DM02" 65228 "DM03" 65229 "DM04" 65230 "DM05" 65231 "DM06" 65234 "DM10" 65235 "DM11" 65236 "DM12" 65242 "SOFT" 65244 "IO" 65248 "VD" 65250 "TCFG" 65253 "HOURS" 65254 "TD" 65255 "VH" 65256 "VDS" 65257 "LFC1" 65258 "VW" 65259 "CI" 65260 "VI" 65261 "CCSS" 65284 "PB_DriversConsentOnPersonalData" 65340 "PB_HVESSCFG" 65376 "VehCfg" 65413 "PB_3CT" 65482 "PB_ID1" 65484 "PB_VNS" 65502 "Av2" 65520 "SCh" 65521 "DIS" 65524 "PB_IVA" ;
VAL_ 2565406710 Pgn_Ack_E8FFF6 37120 "VLSI1" 40448 "DM29" 41216 "DM33" 41728 "DM31" 41984 "DM30" 47360 "PLLT (Plan List Lifetime)" 47872 "PLD (Plan List Distance)" 49408 "DM21" 49664 "DM20" 49920 "DM22" 53504 "MaintBcIc" 54016 "DM19" 60928 "ACL" 61184 "STOD" 64341 "HVESP3HIST" 64342 "HVESP3CFG" 64343 "HVESP2HIST" 64344 "HVESP2CFG" 64345 "HVESP1HIST" 64346 "HVESP1CFG" 64529 "TGFI" 64579 "TCSI" 64582 "TSIS" 64583 "MTI" 64605 "HVESSCFG" 64606 "HVESSHIST" 64653 "PII" 64701 "A1SCRSI2" 64782 "AT1OGC2" 64784 "AT1IGC2" 64839 "TML" 64879 "EEC8" 64896 "DM28" 64905 "VDS2" 64906 "J2012" 64912 "AETC" 64920 "AT1HI1" 64949 "DM23" 64950 "DM24" 64951 "DM25" 64952 "DM26" 64953 "TPRI" 64965 "ECUID" 64981 "EEC5" 65039 "LC" 65099 "TCFG2" 65109 "GFD" 65127 "CCC" 65131 "DI" 65136 "CVW" 65144 "TP1" 65145 "TP2" 65146 "TP3" 65195 "ETC6" 65196 "EBC4" 65199 "GFC" 65201 "EH" 65202 "GFI1" 65203 "LFI1" 65208 "GTFI" 65212 "CBI" 65214 "EEC4" 65216 "SERV" 65219 "ETC5" 65221 "ETC4" 65223 "ETC3" 65227 "DM02" 65228 "DM03" 65229 "DM04" 65230 "DM05" 65231 "DM06" 65234 "DM10" 65235 "DM11" 65236 "DM12" 65242 "SOFT" 65244 "IO" 65248 "VD" 65250 "TCFG" 65253 "HOURS" 65254 "TD" 65255 "VH" 65256 "VDS" 65257 "LFC1" 65258 "VW" 65259 "CI" 65260 "VI" 65261 "CCSS" 65284 "PB_DriversConsentOnPersonalData" 65340 "PB_HVESSCFG" 65376 "VehCfg" 65413 "PB_3CT" 65482 "PB_ID1" 65484 "PB_VNS" 65502 "Av2" 65520 "SCh" 65521 "DIS" 65524 "PB_IVA" ;
VAL_ 2565406710 Pgn_Nack_E8FFF6 37120 "VLSI1" 40448 "DM29" 41216 "DM33" 41728 "DM31" 41984 "DM30" 47360 "PLLT (Plan List Lifetime)" 47872 "PLD (Plan List Distance)" 49408 "DM21" 49664 "DM20" 49920 "DM22" 53504 "MaintBcIc" 54016 "DM19" 60928 "ACL" 61184 "STOD" 64341 "HVESP3HIST" 64342 "HVESP3CFG" 64343 "HVESP2HIST" 64344 "HVESP2CFG" 64345 "HVESP1HIST" 64346 "HVESP1CFG" 64529 "TGFI" 64579 "TCSI" 64582 "TSIS" 64583 "MTI" 64605 "HVESSCFG" 64606 "HVESSHIST" 64653 "PII" 64701 "A1SCRSI2" 64782 "AT1OGC2" 64784 "AT1IGC2" 64839 "TML" 64879 "EEC8" 64896 "DM28" 64905 "VDS2" 64906 "J2012" 64912 "AETC" 64920 "AT1HI1" 64949 "DM23" 64950 "DM24" 64951 "DM25" 64952 "DM26" 64953 "TPRI" 64965 "ECUID" 64981 "EEC5" 65039 "LC" 65099 "TCFG2" 65109 "GFD" 65127 "CCC" 65131 "DI" 65136 "CVW" 65144 "TP1" 65145 "TP2" 65146 "TP3" 65195 "ETC6" 65196 "EBC4" 65199 "GFC" 65201 "EH" 65202 "GFI1" 65203 "LFI1" 65208 "GTFI" 65212 "CBI" 65214 "EEC4" 65216 "SERV" 65219 "ETC5" 65221 "ETC4" 65223 "ETC3" 65227 "DM02" 65228 "DM03" 65229 "DM04" 65230 "DM05" 65231 "DM06" 65234 "DM10" 65235 "DM11" 65236 "DM12" 65242 "SOFT" 65244 "IO" 65248 "VD" 65250 "TCFG" 65253 "HOURS" 65254 "TD" 65255 "VH" 65256 "VDS" 65257 "LFC1" 65258 "VW" 65259 "CI" 65260 "VI" 65261 "CCSS" 65284 "PB_DriversConsentOnPersonalData" 65340 "PB_HVESSCFG" 65376 "VehCfg" 65413 "PB_3CT" 65482 "PB_ID1" 65484 "PB_VNS" 65502 "Av2" 65520 "SCh" 65521 "DIS" 65524 "PB_IVA" ;
VAL_ 2565406710 Pgn_Ad_E8FFF6 37120 "VLSI1" 40448 "DM29" 41216 "DM33" 41728 "DM31" 41984 "DM30" 47360 "PLLT (Plan List Lifetime)" 47872 "PLD (Plan List Distance)" 49408 "DM21" 49664 "DM20" 49920 "DM22" 53504 "MaintBcIc" 54016 "DM19" 60928 "ACL" 61184 "STOD" 64341 "HVESP3HIST" 64342 "HVESP3CFG" 64343 "HVESP2HIST" 64344 "HVESP2CFG" 64345 "HVESP1HIST" 64346 "HVESP1CFG" 64529 "TGFI" 64579 "TCSI" 64582 "TSIS" 64583 "MTI" 64605 "HVESSCFG" 64606 "HVESSHIST" 64653 "PII" 64701 "A1SCRSI2" 64782 "AT1OGC2" 64784 "AT1IGC2" 64839 "TML" 64879 "EEC8" 64896 "DM28" 64905 "VDS2" 64906 "J2012" 64912 "AETC" 64920 "AT1HI1" 64949 "DM23" 64950 "DM24" 64951 "DM25" 64952 "DM26" 64953 "TPRI" 64965 "ECUID" 64981 "EEC5" 65039 "LC" 65099 "TCFG2" 65109 "GFD" 65127 "CCC" 65131 "DI" 65136 "CVW" 65144 "TP1" 65145 "TP2" 65146 "TP3" 65195 "ETC6" 65196 "EBC4" 65199 "GFC" 65201 "EH" 65202 "GFI1" 65203 "LFI1" 65208 "GTFI" 65212 "CBI" 65214 "EEC4" 65216 "SERV" 65219 "ETC5" 65221 "ETC4" 65223 "ETC3" 65227 "DM02" 65228 "DM03" 65229 "DM04" 65230 "DM05" 65231 "DM06" 65234 "DM10" 65235 "DM11" 65236 "DM12" 65242 "SOFT" 65244 "IO" 65248 "VD" 65250 "TCFG" 65253 "HOURS" 65254 "TD" 65255 "VH" 65256 "VDS" 65257 "LFC1" 65258 "VW" 65259 "CI" 65260 "VI" 65261 "CCSS" 65284 "PB_DriversConsentOnPersonalData" 65340 "PB_HVESSCFG" 65376 "VehCfg" 65413 "PB_3CT" 65482 "PB_ID1" 65484 "PB_VNS" 65502 "Av2" 65520 "SCh" 65521 "DIS" 65524 "PB_IVA" ;
VAL_ 2565406710 Pgn_Busy_E8FFF6 37120 "VLSI1" 40448 "DM29" 41216 "DM33" 41728 "DM31" 41984 "DM30" 47360 "PLLT (Plan List Lifetime)" 47872 "PLD (Plan List Distance)" 49408 "DM21" 49664 "DM20" 49920 "DM22" 53504 "MaintBcIc" 54016 "DM19" 60928 "ACL" 61184 "STOD" 64341 "HVESP3HIST" 64342 "HVESP3CFG" 64343 "HVESP2HIST" 64344 "HVESP2CFG" 64345 "HVESP1HIST" 64346 "HVESP1CFG" 64529 "TGFI" 64579 "TCSI" 64582 "TSIS" 64583 "MTI" 64605 "HVESSCFG" 64606 "HVESSHIST" 64653 "PII" 64701 "A1SCRSI2" 64782 "AT1OGC2" 64784 "AT1IGC2" 64839 "TML" 64879 "EEC8" 64896 "DM28" 64905 "VDS2" 64906 "J2012" 64912 "AETC" 64920 "AT1HI1" 64949 "DM23" 64950 "DM24" 64951 "DM25" 64952 "DM26" 64953 "TPRI" 64965 "ECUID" 64981 "EEC5" 65039 "LC" 65099 "TCFG2" 65109 "GFD" 65127 "CCC" 65131 "DI" 65136 "CVW" 65144 "TP1" 65145 "TP2" 65146 "TP3" 65195 "ETC6" 65196 "EBC4" 65199 "GFC" 65201 "EH" 65202 "GFI1" 65203 "LFI1" 65208 "GTFI" 65212 "CBI" 65214 "EEC4" 65216 "SERV" 65219 "ETC5" 65221 "ETC4" 65223 "ETC3" 65227 "DM02" 65228 "DM03" 65229 "DM04" 65230 "DM05" 65231 "DM06" 65234 "DM10" 65235 "DM11" 65236 "DM12" 65242 "SOFT" 65244 "IO" 65248 "VD" 65250 "TCFG" 65253 "HOURS" 65254 "TD" 65255 "VH" 65256 "VDS" 65257 "LFC1" 65258 "VW" 65259 "CI" 65260 "VI" 65261 "CCSS" 65284 "PB_DriversConsentOnPersonalData" 65340 "PB_HVESSCFG" 65376 "VehCfg" 65413 "PB_3CT" 65482 "PB_ID1" 65484 "PB_VNS" 65502 "Av2" 65520 "SCh" 65521 "DIS" 65524 "PB_IVA" ;
VAL_ 2364550954 RelvObjDetForAebs 0 "Not monitored" 1 "Detected - Pedestrian" 2 "Not detected reliably - Obstacle" 3 "Detected - Vehicle" 4 "Detected-PWT Motorcycle/Cyclist" 5 "Not Used" 6 "Error indication" 7 "Not Available / not installed" ;
VAL_ 2364550954 CollWarnLev 0 "No warning" 1 "Warning level 1, Lowest" 2 "Warning level 2" 3 "Warning level 3" 4 "Warning level 4" 5 "Warning level 5" 6 "Warning level 6" 7 "Warning level 7, Highest" 8 "Reserved1" 9 "Reserved2" 10 "Reserved3" 11 "Reserved4" 12 "Reserved5" 13 "Reserved6" 14 "Reserved7" 15 "Don�t care / take no action" ;
VAL_ 2364550954 AebsSts 0 "Not ready" 1 "Temporarily not available" 2 "Deactivated by driver" 3 "Ready" 4 "Driver overrides system" 5 "Collision warning active" 6 "Collision warning with braking" 7 "Emergency braking active" 8 "Perf. / sensitivity limited" 9 "Res / Distance Warning" 10 "Reserved1" 11 "Reserved2" 12 "Reserved3" 13 "Reserved4" 14 "Error indication" 15 "Not Available / Not installed" ;
VAL_ 2349541911 AebsSens 0 "Mode #1, Lowest" 1 "Mode #2" 2 "Mode #3" 3 "Mode #4" 4 "Mode #5, Highest" 6 "Error condition" 7 "Not Available / Not valid" ;
VAL_ 2349541911 DistWarnCfg 0 "Distance Warning Off" 1 "Distance Warning On" 2 "Error" 3 "Not Available" ;
VAL_ 2349541911 DrivActvDemForAebs 0 "Deactivation of system" 1 "No deactivation of system" 2 "Reserved" 3 "Don�t' care / Take no action" ;
VAL_ 2349537098 AebsSens_B174A 0 "Mode #1, Lowest" 1 "Mode #2" 2 "Mode #3" 3 "Mode #4" 4 "Mode #5, Highest" 6 "Error condition" 7 "Not Available / Not valid" ;
VAL_ 2349537098 DistWarnCfg_B174A 0 "Distance Warning Off" 1 "Distance Warning On" 2 "Error" 3 "Not Available" ;
VAL_ 2349537098 DrivActvDemForAebs_B174A 0 "Deactivation of system" 1 "No deactivation of system" 2 "Reserved" 3 "Don�t' care / Take no action" ;
VAL_ 2566837537 Altern1Sts 0 "Not charging" 1 "Charging" 2 "Error" 3 "Not Available" ;
VAL_ 2365479471 SuspCtrlRefusalInfo 0 "Actual request not refused" 1 "Axle load limit reached" 2 "Would exceed limit, tag axle" 3 "Bogie differential not locked" 4 "Above speed limit" 5 "Below speed limit" 6 "Reject, No specified reason" 7 "Requested level not available" 8 "Not defined" 9 "Not defined" 10 "Not defined" 11 "Not defined" 12 "Not defined" 13 "Not defined" 14 "Error" 15 "Not Available" ;
VAL_ 2365479471 SpeedDepLevCtrlSts 0 "Inactive" 1 "Active" 2 "Reserved" 3 "Don�t' care/take no action" ;
VAL_ 2365479471 AllowLevCtrlDurBrkSts 0 "Deactivate" 1 "Activate" 2 "Reserved" 3 "Don�t Care / Take no action" ;
VAL_ 2365479471 SuspRemCtrl2 0 "Not active" 1 "Active" 2 "Error" 3 "Not Available" ;
VAL_ 2365479471 SuspRemCtrl1 0 "Not active" 1 "Active" 2 "Error" 3 "Not Available" ;
VAL_ 2365479471 LiftA2Pos 0 "Down / tag axle laden" 1 "Up / tag axle unladen" 2 "Error" 3 "Not Available" ;
VAL_ 2365479471 RaInBumperRng 0 "Out of bumper range" 1 "Within bumper range" 2 "Error" 3 "Not Available" ;
VAL_ 2365479471 FaInBumperRng 0 "Out of bumper range" 1 "Within bumper range" 2 "Error" 3 "Not Available" ;
VAL_ 2365479471 LiftA1Pos 0 "Down / tag axle laden" 1 "Up / tag axle unladen" 2 "Error" 3 "Not Available" ;
VAL_ 2365479471 DoorRels 0 "Doors may not be opened" 1 "Doors may be opened" 2 "Error" 3 "Not Available" ;
VAL_ 2365479471 VehMotInh 0 "Vehicle may be moved" 1 "Vehicle motion is inhibited" 2 "Error" 3 "Not Available" ;
VAL_ 2365479471 SecurDev 0 "Not active" 1 "Active" 2 "Error" 3 "Not Available" ;
VAL_ 2365479471 LevCtrlMode 0 "Normal operation" 1 "Traction help, load transfer" 2 "Load fixing" 3 "Pressure ratio 1" 4 "Pressure ratio 2" 5 "Optimum traction 1" 6 "Optimum traction 2" 7 "Traction help, load reduce" 8 "Exhausting bellow function" 9 "Control prohibited, hold press" 10 "Automatic control prohibited" 11 "Force to bumper level in effect" 12 "Not defined" 13 "Not defined" 14 "Error" 15 "Not Available" ;
VAL_ 2365479471 KneelInfo 0 "Not active" 1 "Lowering active" 2 "Kneeling level reached" 3 "Lifting active" 4 "Kneeling aborted" 5 "Not defined" 6 "Not defined" 13 "Not defined" 14 "Error" 15 "Not Available" ;
VAL_ 2365479471 LiftCtrlModeRa 0 "Lifting not active" 1 "Lifting active" 2 "Error" 3 "Not Available" ;
VAL_ 2365479471 LiftCtrlModeFa 0 "Lifting not active" 1 "Lifting active" 2 "Error" 3 "Not Available" ;
VAL_ 2365479471 LowCtrlModeRa 0 "Lowering not active" 1 "Lowering active" 2 "Error" 3 "Not Available" ;
VAL_ 2365479471 LowCtrlModeFa 0 "Lowering not active" 1 "Lowering active" 2 "Error" 3 "Not Available" ;
VAL_ 2365479471 AbvNomLevRa 0 "Not above" 1 "Above" 2 "Error" 3 "Not Available" ;
VAL_ 2365479471 AbvNomLevFa 0 "Not above" 1 "Above" 2 "Error" 3 "Not Available" ;
VAL_ 2365479471 BlwNomLevRa 0 "Not below" 1 "Below" 2 "Error" 3 "Not Available" ;
VAL_ 2365479471 BlwNomLevFa 0 "Not below" 1 "Below" 2 "Error" 3 "Not Available" ;
VAL_ 2365479471 NomLevRa 0 "Level not specified" 1 "Normal level 1" 2 "Normal level 2" 3 "Normal level 3" 4 "Preset Level" 5 "Customer Level" 6 "Upper Level" 7 "Lower Level" 8 "Level change stopped" 9 "Raising" 10 "Lowering" 11 "Reserved" 12 "Reserved" 13 "Reserved" 14 "Error" 15 "Not Available" ;
VAL_ 2365479471 NomLevFa 0 "Level not specified" 1 "Normal level 1" 2 "Normal level 2" 3 "Normal level 3" 4 "Preset Level" 5 "Customer Level" 6 "Upper Level" 7 "Lower Level" 8 "Level change stopped" 9 "Raising" 10 "Lowering" 11 "Reserved" 12 "Reserved" 13 "Reserved" 15 "Not Available" ;
VAL_ 2362584906 ProhibitAirSuspCtrl 0 "No request" 1 "Request prohibit air susp. ctrl" 2 "Error indicator" 3 "Not Available" ;
VAL_ 2362584906 KneelCmdRa 0 "Deactivate kneeling" 1 "Activate kneeling" 2 "Reserved" 3 "Don�t Care / Take no action" ;
VAL_ 2362584906 KneelCmdFa 0 "Deactivate kneeling" 1 "Activate kneeling" 2 "Reserved" 3 "Don�t Care / Take no action" ;
VAL_ 2362584906 LiftA2PosCmd 0 "Down, tag axle laden" 1 "Up, tag axle unladen" 2 "Reserved" 3 "Don�t Care / Take no action" ;
VAL_ 2362584906 LiftA1PosCmd 0 "Down / tag axle laden" 1 "Up / tag axle unladen" 2 "Reserved" 3 "Don�t Care / Take no action" ;
VAL_ 2362584906 LevCtrlModeReq 0 "Normal oper., pure height ctrl" 1 "Traction help, load transfer" 2 "Load fixing, driver def. value" 3 "Pressure ratio 1" 4 "Pressure ratio 2" 5 "Optimum traction, prs 1" 6 "Optimum traction, prs 2" 7 "Traction help, load reduce" 8 "Exhaust bellows" 9 "Force to bumper level" 10 "Not defined" 11 "Not defined" 12 "Not defined" 13 "Not defined" 14 "Reserved" 15 "Don�t Care / Take no action" ;
VAL_ 2362584906 NomLevReqRa 0 "No request" 1 "Normal 1, normal driving" 2 "Normal 2, permitted for driving" 3 "Normal 3, permitted for driving" 4 "Preset Level, via CAN" 5 "Customer Level, via param set" 6 "Upper Level, highest level" 7 "Lower Level,lowest level" 8 "Stop level change" 9 "Raise Request, Continuously" 10 "Lower Request, Continuously" 11 "Not defined" 12 "Not defined" 13 "Not defined" 14 "Reserved" 15 "Don�t Care / Take no action" ;
VAL_ 2362584906 NomLevReqFa 0 "No request" 1 "Normal 1, normal driving" 2 "Normal 2, permitted for driving" 3 "Normal 3, permitted for driving" 4 "Preset Level, via CAN" 5 "Customer Level, via param set" 6 "Upper Level, highest level" 7 "Lower Level,lowest level" 8 "Stop level change" 9 "Raise Request, Continuously" 10 "Lower Request, Continuously" 11 "Not defined" 12 "Not defined" 13 "Not defined" 14 "Reserved" 15 "Don�t Care / Take no action" ;
VAL_ 2362584906 KneelCtrlModeReq 0 "Automatically actuated" 1 "Manually actuated" 2 "Reserved" 3 "Don�t Care / Take no action" ;
VAL_ 2362584906 KneelReqRh 0 "No kneeling request" 1 "Kneeling request" 2 "Reserved" 3 "Don�t Care / Take no action" ;
VAL_ 2362584906 KneelReqLh 0 "No kneeling request" 1 "Kneeling request" 2 "Reserved" 3 "Don�t Care / Take no action" ;
VAL_ 2362584906 AutoTractHelp 0 "Disable automatic traction help" 1 "Enable automatic traction help" 2 "Reserved" 3 "Don't Care" ;
VAL_ 2148573190 PrefillActv 0 "Not Active" 1 "Active" ;
VAL_ 2148573190 HbaActv 0 "Not Active" 1 "Active" ;
VAL_ 2148573190 TtcActv 0 "Not Active" 1 "Active" ;
VAL_ 2148573190 HhActv 0 "Not Active" 1 "Active" ;
VAL_ 2148573190 GearShiftReq 0 "D Request" 1 "P Request" 2 "R Request" 3 "N Request" 4 "Downshift Request" 5 "Upshift Request" 6 "Error" 7 "Not Available/No Request" ;
VAL_ 2148573190 MasterCylPrsValData 0 "Valid" 1 "Not valid" ;
VAL_ 2148573190 VdcShiftInterf 0 "Shift allowed" 1 "Shift not allowed" ;
VAL_ 2148573190 VdcShiftInterfValData 0 "Valid" 1 "Not valid" ;
VAL_ 2148573190 AsrCtrlSts 0 "On" 1 "Disabled" ;
VAL_ 2566804992 AtScrOpInducSev 0 "No Inducement Active" 1 "Level 1" 2 "Level 2" 3 "Level 3" 4 "Level 4" 5 "Level 5" 6 "Temporary Override of Inducement" 7 "Not Available / Not Supported" ;
VAL_ 2566804992 AtDefTankLowLevInd 0 "Off" 1 "On, solid" 2 "Reserved" 3 "Reserved" 4 "On, fast blink (1 Hz)" 5 "Reserved" 6 "Reserved" 7 "Not Available" ;
VAL_ 2566804992 At1DefTankVol 251 "No valid measurement" ;
VAL_ 2564685591 AntiTheftCmdSts 0 "Add Password" 1 "Delete Password" 2 "Change Password" 3 "Lock or Unlock" 4 "Check Status" 5 "Login" 6 "Not defined" 7 "Not defined" ;
VAL_ 2565144605 AntiTheftCmdSts_E5001D 0 "Add Password" 1 "Delete Password" 2 "Change Password" 3 "Lock or Unlock" 4 "Check Status" 5 "Login" 6 "Not defined" 7 "Not defined" ;
VAL_ 2565144605 AntiTheftDesExitModeSts 0 "Lock Upon Operator Request" 1 "Lock When Key Off" 2 "Not defined" 3 "Not Available" ;
VAL_ 2565144605 AntiTheftEncrIndSts 0 "Encryption Seed Request" 1 "Encrypted Code Present" 2 "Not defined" 3 "Not Available" ;
VAL_ 2565152000 AntiTheftModPswSts 0 "Ok" 1 "Full of Passwords" 2 "Empty ofPasswords" 3 "Not valid" ;
VAL_ 2565152000 AntiTheftCompStsSts 0 "Unlocked" 1 "Locked" 2 "Blocked" 3 "Not defined" ;
VAL_ 2565152000 AntiTheftPswValInd 0 "Not a validated password" 1 "Validated password" 2 "Error" 3 "Not Available" ;
VAL_ 2565152000 AntiTheftEncrSeedPresInd 0 "Random number is not present" 1 "Random number is present" 2 "Error" 3 "Not Available" ;
VAL_ 2561146657 MsgCks 15 "Not Available, request honored" ;
VAL_ 2561146657 MsgCnt 8 "Reserved1" 9 "Reserved2" 10 "Reserved3" 11 "Reserved4" 12 "Reserved5" 13 "Reserved6" 14 "Reserved7" 15 "Not Available, request honored" ;
VAL_ 2561146657 RightStackBtn 0 "Not pressed" 1 "Pressed" 2 "Error" 3 "Not Available" ;
VAL_ 2561146657 Sw8_Vsla_IcMenuRtn 0 "Off" 1 "On" 2 "Error Indicator" 3 "Not Available" ;
VAL_ 2561146657 Sw7_AccDist_IcMenu2 0 "Off" 1 "On" 2 "Error Indicator" 3 "Not Available" ;
VAL_ 2561146657 Sw6_AccEna_IcMenu1 0 "Off" 1 "On" 2 "Error Indicator" 3 "Not Available / Take no action" ;
VAL_ 2561146657 Sw2_CcEna_AccEna 0 "Off" 1 "On" 2 "Error Indicator" 3 "Not Available" ;
VAL_ 2561146657 Sw3_CcRes_Canc 0 "Off" 1 "On" 2 "Error Indicator" 3 "Not Available" ;
VAL_ 2561146657 Sw5_CcCanc_Vsla 0 "Off" 1 "On" 2 "Error Indicator" 3 "Not Available" ;
VAL_ 2561146657 Sw4_CcSetDec 0 "Off" 1 "On" 2 "Error Indicator" 3 "Not Available" ;
VAL_ 2561146657 Sw1_CcSetAcc 0 "Off" 1 "On" 2 "Error Indicator" 3 "Not Available" ;
VAL_ 2561146657 SwB_NextSrc 0 "Off" 1 "On" 2 "Error Indicator" 3 "Not Available" ;
VAL_ 2561146657 SwC_ScanDw 0 "Off" 1 "On" 2 "Error Indicator" 3 "Not Available" ;
VAL_ 2561146657 SwA_ScanUp 0 "Off" 1 "On" 2 "Error Indicator" 3 "Not Available" ;
VAL_ 2561146657 SwE_Mute 0 "Off" 1 "On" 2 "Error Indicator" 3 "Not Available" ;
VAL_ 2561146657 SwF_VolDw 0 "Off" 1 "On" 2 "Error Indicator" 3 "Not Available" ;
VAL_ 2561146657 SwD_VolUp 0 "Off" 1 "On" 2 "Error Indicator" 3 "Not Available" ;
VAL_ 2561146657 SwR_IcMenu_Hwa 0 "Off" 1 "On" 2 "Error Indicator" 3 "Not Available" ;
VAL_ 2561146657 SwQ_VoiceRec 0 "Off" 1 "On" 2 "Error Indicator" 3 "Not Available" ;
VAL_ 2561146657 SwP_PhoneCall 0 "Off" 1 "On" 2 "Error Indicator" 3 "Not Available" ;
VAL_ 2561146657 SwN_Ok 0 "Off" 1 "On" 2 "Error Indicator" 3 "Not Available" ;
VAL_ 2561146657 SwH_Right 0 "Off" 1 "On" 2 "Error Indicator" 3 "Not Available" ;
VAL_ 2561146657 SwM_Left 0 "Off" 1 "On" 2 "Error Indicator" 3 "Not Available" ;
VAL_ 2561146657 SwL_Dw 0 "Off" 1 "On" 2 "Error Indicator" 3 "Not Available" ;
VAL_ 2561146657 SwG_Up 0 "Off" 1 "On" 2 "Error Indicator" 3 "Not Available" ;
VAL_ 2566859292 Pos_RelHead 0 "In path direction" 1 "1.417� right from path dir" 2 "2.835� right from path dir" 3 "4.252� right from path dir" 4 "5.669� right from path dir" 5 "7.087� right from path dir" 6 "8.504� right from path dir" 7 "9.921� right from path dir" 8 "11.339� right from path dir" 9 "12.756� right from path dir" 10 "14.173� right from path dir" 11 "15.591� right from path dir" 12 "17.008� right from path dir" 13 "18.425� right from path dir" 14 "19.843� right from path dir" 15 "21.26� right from path dir" 16 "22.677� right from path dir" 17 "24.094� right from path dir" 18 "25.512� right from path dir" 19 "26.929� right from path dir" 20 "28.346� right from path dir" 21 "29.764� right from path dir" 22 "31.181� right from path dir" 23 "32.598� right from path dir" 24 "34.016� right from path dir" 25 "35.433� right from path dir" 26 "36.85� right from path dir" 27 "38.268� right from path dir" 28 "39.685� right from path dir" 29 "41.102� right from path dir" 30 "42.52� right from path dir" 31 "43.937� right from path dir" 32 "45.354� right from path dir" 33 "46.772� right from path dir" 34 "48.189� right from path dir" 35 "49.606� right from path dir" 36 "51.024� right from path dir" 37 "52.441� right from path dir" 38 "53.858� right from path dir" 39 "55.276� right from path dir" 40 "56.693� right from path dir" 41 "58.11� right from path dir" 42 "59.528� right from path dir" 43 "60.945� right from path dir" 44 "62.362� right from path dir" 45 "63.78� right from path dir" 46 "65.197� right from path dir" 47 "66.614� right from path dir" 48 "68.031� right from path dir" 49 "69.449� right from path dir" 50 "70.866� right from path dir" 51 "72.283� right from path dir" 52 "73.701� right from path dir" 53 "75.118� right from path dir" 54 "76.535� right from path dir" 55 "77.953� right from path dir" 56 "79.37� right from path dir" 57 "80.787� right from path dir" 58 "82.205� right from path dir" 59 "83.622� right from path dir" 60 "85.039� right from path dir" 61 "86.457� right from path dir" 62 "87.874� right from path dir" 63 "89.291� right from path dir" 64 "90.709� right from path dir" 65 "92.126� right from path dir" 66 "93.543� right from path dir" 67 "94.961� right from path dir" 68 "96.378� right from path dir" 69 "97.795� right from path dir" 70 "99.213� right from path dir" 71 "100.63� right from path dir" 72 "102.047� right from path dir" 73 "103.465� right from path dir" 74 "104.882� right from path dir" 75 "106.299� right from path dir" 76 "107.717� right from path dir" 77 "109.134� right from path dir" 78 "110.551� right from path dir" 79 "111.969� right from path dir" 80 "113.386� right from path dir" 81 "114.803� right from path dir" 82 "116.22� right from path dir" 83 "117.638� right from path dir" 84 "119.055� right from path dir" 85 "120.472� right from path dir" 86 "121.89� right from path dir" 87 "123.307� right from path dir" 88 "124.724� right from path dir" 89 "126.142� right from path dir" 90 "127.559� right from path dir" 91 "128.976� right from path dir" 92 "130.394� right from path dir" 93 "131.811� right from path dir" 94 "133.228� right from path dir" 95 "134.646� right from path dir" 96 "136.063� right from path dir" 97 "137.48� right from path dir" 98 "138.898� right from path dir" 99 "140.315� right from path dir" 100 "141.732� right from path dir" 101 "143.15� right from path dir" 102 "144.567� right from path dir" 103 "145.984� right from path dir" 104 "147.402� right from path dir" 105 "148.819� right from path dir" 106 "150.236� right from path dir" 107 "151.654� right from path dir" 108 "153.071� right from path dir" 109 "154.488� right from path dir" 110 "155.906� right from path dir" 111 "157.323� right from path dir" 112 "158.74� right from path dir" 113 "160.157� right from path dir" 114 "161.575� right from path dir" 115 "162.992� right from path dir" 116 "164.409� right from path dir" 117 "165.827� right from path dir" 118 "167.244� right from path dir" 119 "168.661� right from path dir" 120 "170.079� right from path dir" 121 "171.496� right from path dir" 122 "172.913� right from path dir" 123 "174.331� right from path dir" 124 "175.748� right from path dir" 125 "177.165� right from path dir" 126 "178.583� right from path dir" 127 "Opposite direction" 128 "178.583� left from path dir" 129 "177.165� left from path dir" 130 "175.748� left from path dir" 131 "174.331� left from path dir" 132 "172.913� left from path dir" 133 "171.496� left from path dir" 134 "170.079� left from path dir" 135 "168.661� left from path dir" 136 "167.244� left from path dir" 137 "165.827� left from path dir" 138 "164.409� left from path dir" 139 "162.992� left from path dir" 140 "161.575� left from path dir" 141 "160.157� left from path dir" 142 "158.74� left from path dir" 143 "157.323� left from path dir" 144 "155.906� left from path dir" 145 "154.488� left from path dir" 146 "153.071� left from path dir" 147 "151.654� left from path dir" 148 "150.236� left from path dir" 149 "148.819� left from path dir" 150 "147.402� left from path dir" 151 "145.984� left from path dir" 152 "144.567� left from path dir" 153 "143.15� left from path dir" 154 "141.732� left from path dir" 155 "140.315� left from path dir" 156 "138.898� left from path dir" 157 "137.48� left from path dir" 158 "136.063� left from path dir" 159 "134.646� left from path dir" 160 "133.228� left from path dir" 161 "131.811� left from path dir" 162 "130.394� left from path dir" 163 "128.976� left from path dir" 164 "127.559� left from path dir" 165 "126.142� left from path dir" 166 "124.724� left from path dir" 167 "123.307� left from path dir" 168 "121.89� left from path dir" 169 "120.472� left from path dir" 170 "119.055� left from path dir" 171 "117.638� left from path dir" 172 "116.22� left from path dir" 173 "114.803� left from path dir" 174 "113.386� left from path dir" 175 "111.969� left from path dir" 176 "110.551� left from path dir" 177 "109.134� left from path dir" 178 "107.717� left from path dir" 179 "106.299� left from path dir" 180 "104.882� left from path dir" 181 "103.465� left from path dir" 182 "102.047� left from path dir" 183 "100.63� left from path dir" 184 "99.213� left from path dir" 185 "97.795� left from path dir" 186 "96.378� left from path dir" 187 "94.961� left from path dir" 188 "93.543� left from path dir" 189 "92.126� left from path dir" 190 "90.709� left from path dir" 191 "89.291� left from path dir" 192 "87.874� left from path dir" 193 "86.457� left from path dir" 194 "85.039� left from path dir" 195 "83.622� left from path dir" 196 "82.205� left from path dir" 197 "80.787� left from path dir" 198 "79.37� left from path dir" 199 "77.953� left from path dir" 200 "76.535� left from path dir" 201 "75.118� left from path dir" 202 "73.701� left from path dir" 203 "72.283� left from path dir" 204 "70.866� left from path dir" 205 "69.449� left from path dir" 206 "68.031� left from path dir" 207 "66.614� left from path dir" 208 "65.197� left from path dir" 209 "63.78� left from path dir" 210 "62.362� left from path dir" 211 "60.945� left from path dir" 212 "59.528� left from path dir" 213 "58.11� left from path dir" 214 "56.693� left from path dir" 215 "55.276� left from path dir" 216 "53.858� left from path dir" 217 "52.441� left from path dir" 218 "51.024� left from path dir" 219 "49.606� left from path dir" 220 "48.189� left from path dir" 221 "46.772� left from path dir" 222 "45.354� left from path dir" 223 "43.937� left from path dir" 224 "42.52� left from path dir" 225 "41.102� left from path dir" 226 "39.685� left from path dir" 227 "38.268� left from path dir" 228 "36.85� left from path dir" 229 "35.433� left from path dir" 230 "34.016� left from path dir" 231 "32.598� left from path dir" 232 "31.181� left from path dir" 233 "29.764� left from path dir" 234 "28.346� left from path dir" 235 "26.929� left from path dir" 236 "25.512� left from path dir" 237 "24.094� left from path dir" 238 "22.677� left from path dir" 239 "21.26� left from path dir" 240 "19.843� left from path dir" 241 "18.425� left from path dir" 242 "17.008� left from path dir" 243 "15.591� left from path dir" 244 "14.173� left from path dir" 245 "12.756� left from path dir" 246 "11.339� left from path dir" 247 "9.921� left from path dir" 248 "8.504� left from path dir" 249 "7.087� left from path dir" 250 "5.669� left from path dir" 251 "4.252� left from path dir" 252 "2.835� left from path dir" 253 "1.417� left from path dir" 254 "Unknown" 255 "N/A" ;
VAL_ 2566859292 Pos_Speed 510 "=+89.2 m/s" 511 "N/A" ;
VAL_ 2566859292 Pos_CurLane 0 "Unknown" 1 "Emergency lane" 2 "Single-lane road" 3 "Left-most lane" 4 "Right-most lane" 5 "Middle (road with >3 lanes)" 6 "Reserved" 7 "N/A" ;
VAL_ 2566859292 Pos_PosConf 7 "N/A" ;
VAL_ 2566859292 Pos_PosAge 510 "2545 ms" 511 "N/A" ;
VAL_ 2566859292 Pos_PosProb 0 "Unknown" 31 "N/A" ;
VAL_ 2566859292 Pos_PathIx 0 "Unknown" 1 "Not in Digitized Area" 2 "Not on-road" 3 "Av2HP not calibrated" 7 "Reserved" ;
VAL_ 2566859292 Pos_Ofs 8191 "Invalid" ;
VAL_ 2566859292 MsgType 0 "Reserved1" 1 "POSITION" 2 "SEGMENT" 3 "STUB" 4 "PROFILE SHORT" 5 "PROFILE LONG" 6 "META-DATA" 7 "Reserved2" ;
VAL_ 2566859548 Seg_NumOfLanesInDrivDir 0 "One-direction road in wrong dir" 1 "1 lane" 2 "2 lanes" 3 "3 lanes" 4 "4 lanes" 5 "5 lanes" 6 "6 or more lanes" 7 "N/A" ;
VAL_ 2566859548 Seg_NumOfLanesInOppDir 0 "One-direction road" 1 "1 lane only" 2 "2 or more lanes" 3 "N/A" ;
VAL_ 2566859548 Seg_DividedRoad 0 "Not part of a divided/dual road" 1 "Part of a divided/dual road" 2 "Unknown" 3 "N/A" ;
VAL_ 2566859548 Seg_EffSpeedLimType 0 "Implicit" 1 "Explicit, on traffic sign" 2 "Explicit, by night" 3 "Explicit, by day" 4 "Explicit, time of day" 5 "Explicit, rain" 6 "Explicit, snow" 7 "Unknown" ;
VAL_ 2566859548 Seg_EffSpeedLim 0 "Unknown" 1 "= 5km/h(mph)" 2 "7km/h(mph)" 3 "10km/h(mph)" 4 "15km/h(mph)" 5 "20km/h(mph)" 6 "25km/h(mph)" 7 "30km/h(mph)" 8 "35km/h(mph)" 9 "40km/h(mph)" 10 "45km/h(mph)" 11 "50km/h(mph)" 12 "55km/h(mph)" 13 "60km/h(mph)" 14 "65km/h(mph)" 15 "70km/h(mph)" 16 "75km/h(mph)" 17 "80km/h(mph)" 18 "85km/h(mph)" 19 "90km/h(mph)" 20 "95km/h(mph)" 21 "100km/h(mph)" 22 "105km/h(mph)" 23 "110km/h(mph)" 24 "115km/h(mph)" 25 "120km/h(mph)" 26 "130km/h(mph)" 27 "140km/h(mph)" 28 "150km/h(mph)" 29 "160km/h(mph)" 30 "Unlimited" 31 "N/A" ;
VAL_ 2566859548 Seg_FormOfWay 0 "Unknown" 1 "Freeway/CntrldAccess Rd" 2 "Multiple Carriageway/Digitized" 3 "Single Carriageway (default)" 4 "Roundabout Circle" 5 "Traffic Square/Special Traffic" 6 "Reserved1" 7 "Reserved2" 8 "Parallel Road" 9 "Freeway/CntrldAccess SlipRd" 10 "SlipRd, not on Freeway/CntrldAcc" 11 "Service/Frontage Rd" 12 "CarPark Entrance/Exit" 13 "Service Entrance/Exit" 14 "Pedestrian Zone" ;
VAL_ 2566859548 Seg_ComplexInters 0 "Not part of complex intersection" 1 "Part of a complex intersection" 2 "Unknown" 3 "N/A" ;
VAL_ 2566859548 Seg_PartOfCalcRoute 0 "Not part of Calculated Route" 1 "Part of Calculated Route" 2 "Unknown" 3 "N/A" ;
VAL_ 2566859548 Seg_FunctRoadClass 0 "Unknown" 1 "Class 1" 2 "Class 2" 3 "Class 3" 4 "Class 4" 5 "Class 5" 6 "Class 6" 7 "N/A" ;
VAL_ 2566859548 Seg_RelProb 0 "Driving not allowed on this segm" 31 "Unknown or N/A" ;
VAL_ 2566859548 Seg_Update 0 "False" 1 "True" ;
VAL_ 2566859548 Seg_Retr 0 "False" 1 "True" ;
VAL_ 2566859548 Seg_BuiltUpArea 0 "Not part of a built-up area" 1 "Part of a built-up area" 2 "Unknown" 3 "N/A" ;
VAL_ 2566859548 Seg_Bridge 0 "Not part of a bridge" 1 "Part of a bridge" 2 "Unknown" 3 "N/A" ;
VAL_ 2566859548 Seg_Tunnel 0 "Not part of a tunnel" 1 "Part of a tunnel" 2 "Unknown" 3 "N/A" ;
VAL_ 2566859548 Seg_PathIx 0 "Unknown" 4 "Msg refer to cur.pos. segm" 7 "Reserved" ;
VAL_ 2566859548 Seg_Ofs 8191 "Invalid" ;
VAL_ 2566859548 MsgType_FF2B1C 0 "Reserved1" 1 "POSITION" 2 "SEGMENT" 3 "STUB" 4 "PROFILE SHORT" 5 "PROFILE LONG" 6 "META-DATA" 7 "Reserved2" ;
VAL_ 2566859804 Stub_NumOfLanesInDrivDir 0 "One-direction road in wrong dir" 1 "1 lane" 2 "2 lanes" 3 "3 lanes" 4 "4 lanes" 5 "5 lanes" 6 "6 or more lanes" 7 "N/A" ;
VAL_ 2566859804 Stub_NumOfLanesInOppDir 0 "One-direction road" 1 "1 lane only" 2 "2 or more lanes" 3 "N/A" ;
VAL_ 2566859804 Stub_RightOfWay 0 "Parent path has right-of-way" 1 "Sub-path has right-of-way" 2 "Unknown" 3 "N/A" ;
VAL_ 2566859804 Stub_LastStubAtOfs 0 "False" 1 "True" ;
VAL_ 2566859804 Stub_TurnAngle 0 "In path direction" 1 "1.417� right from path dir" 2 "2.835� right from path dir" 3 "4.252� right from path dir" 4 "5.669� right from path dir" 5 "7.087� right from path dir" 6 "8.504� right from path dir" 7 "9.921� right from path dir" 8 "11.339� right from path dir" 9 "12.756� right from path dir" 10 "14.173� right from path dir" 11 "15.591� right from path dir" 12 "17.008� right from path dir" 13 "18.425� right from path dir" 14 "19.843� right from path dir" 15 "21.26� right from path dir" 16 "22.677� right from path dir" 17 "24.094� right from path dir" 18 "25.512� right from path dir" 19 "26.929� right from path dir" 20 "28.346� right from path dir" 21 "29.764� right from path dir" 22 "31.181� right from path dir" 23 "32.598� right from path dir" 24 "34.016� right from path dir" 25 "35.433� right from path dir" 26 "36.85� right from path dir" 27 "38.268� right from path dir" 28 "39.685� right from path dir" 29 "41.102� right from path dir" 30 "42.52� right from path dir" 31 "43.937� right from path dir" 32 "45.354� right from path dir" 33 "46.772� right from path dir" 34 "48.189� right from path dir" 35 "49.606� right from path dir" 36 "51.024� right from path dir" 37 "52.441� right from path dir" 38 "53.858� right from path dir" 39 "55.276� right from path dir" 40 "56.693� right from path dir" 41 "58.11� right from path dir" 42 "59.528� right from path dir" 43 "60.945� right from path dir" 44 "62.362� right from path dir" 45 "63.78� right from path dir" 46 "65.197� right from path dir" 47 "66.614� right from path dir" 48 "68.031� right from path dir" 49 "69.449� right from path dir" 50 "70.866� right from path dir" 51 "72.283� right from path dir" 52 "73.701� right from path dir" 53 "75.118� right from path dir" 54 "76.535� right from path dir" 55 "77.953� right from path dir" 56 "79.37� right from path dir" 57 "80.787� right from path dir" 58 "82.205� right from path dir" 59 "83.622� right from path dir" 60 "85.039� right from path dir" 61 "86.457� right from path dir" 62 "87.874� right from path dir" 63 "89.291� right from path dir" 64 "90.709� right from path dir" 65 "92.126� right from path dir" 66 "93.543� right from path dir" 67 "94.961� right from path dir" 68 "96.378� right from path dir" 69 "97.795� right from path dir" 70 "99.213� right from path dir" 71 "100.63� right from path dir" 72 "102.047� right from path dir" 73 "103.465� right from path dir" 74 "104.882� right from path dir" 75 "106.299� right from path dir" 76 "107.717� right from path dir" 77 "109.134� right from path dir" 78 "110.551� right from path dir" 79 "111.969� right from path dir" 80 "113.386� right from path dir" 81 "114.803� right from path dir" 82 "116.22� right from path dir" 83 "117.638� right from path dir" 84 "119.055� right from path dir" 85 "120.472� right from path dir" 86 "121.89� right from path dir" 87 "123.307� right from path dir" 88 "124.724� right from path dir" 89 "126.142� right from path dir" 90 "127.559� right from path dir" 91 "128.976� right from path dir" 92 "130.394� right from path dir" 93 "131.811� right from path dir" 94 "133.228� right from path dir" 95 "134.646� right from path dir" 96 "136.063� right from path dir" 97 "137.48� right from path dir" 98 "138.898� right from path dir" 99 "140.315� right from path dir" 100 "141.732� right from path dir" 101 "143.15� right from path dir" 102 "144.567� right from path dir" 103 "145.984� right from path dir" 104 "147.402� right from path dir" 105 "148.819� right from path dir" 106 "150.236� right from path dir" 107 "151.654� right from path dir" 108 "153.071� right from path dir" 109 "154.488� right from path dir" 110 "155.906� right from path dir" 111 "157.323� right from path dir" 112 "158.74� right from path dir" 113 "160.157� right from path dir" 114 "161.575� right from path dir" 115 "162.992� right from path dir" 116 "164.409� right from path dir" 117 "165.827� right from path dir" 118 "167.244� right from path dir" 119 "168.661� right from path dir" 120 "170.079� right from path dir" 121 "171.496� right from path dir" 122 "172.913� right from path dir" 123 "174.331� right from path dir" 124 "175.748� right from path dir" 125 "177.165� right from path dir" 126 "178.583� right from path dir" 127 "Opposite direction" 128 "178.583� left from path dir" 129 "177.165� left from path dir" 130 "175.748� left from path dir" 131 "174.331� left from path dir" 132 "172.913� left from path dir" 133 "171.496� left from path dir" 134 "170.079� left from path dir" 135 "168.661� left from path dir" 136 "167.244� left from path dir" 137 "165.827� left from path dir" 138 "164.409� left from path dir" 139 "162.992� left from path dir" 140 "161.575� left from path dir" 141 "160.157� left from path dir" 142 "158.74� left from path dir" 143 "157.323� left from path dir" 144 "155.906� left from path dir" 145 "154.488� left from path dir" 146 "153.071� left from path dir" 147 "151.654� left from path dir" 148 "150.236� left from path dir" 149 "148.819� left from path dir" 150 "147.402� left from path dir" 151 "145.984� left from path dir" 152 "144.567� left from path dir" 153 "143.15� left from path dir" 154 "141.732� left from path dir" 155 "140.315� left from path dir" 156 "138.898� left from path dir" 157 "137.48� left from path dir" 158 "136.063� left from path dir" 159 "134.646� left from path dir" 160 "133.228� left from path dir" 161 "131.811� left from path dir" 162 "130.394� left from path dir" 163 "128.976� left from path dir" 164 "127.559� left from path dir" 165 "126.142� left from path dir" 166 "124.724� left from path dir" 167 "123.307� left from path dir" 168 "121.89� left from path dir" 169 "120.472� left from path dir" 170 "119.055� left from path dir" 171 "117.638� left from path dir" 172 "116.22� left from path dir" 173 "114.803� left from path dir" 174 "113.386� left from path dir" 175 "111.969� left from path dir" 176 "110.551� left from path dir" 177 "109.134� left from path dir" 178 "107.717� left from path dir" 179 "106.299� left from path dir" 180 "104.882� left from path dir" 181 "103.465� left from path dir" 182 "102.047� left from path dir" 183 "100.63� left from path dir" 184 "99.213� left from path dir" 185 "97.795� left from path dir" 186 "96.378� left from path dir" 187 "94.961� left from path dir" 188 "93.543� left from path dir" 189 "92.126� left from path dir" 190 "90.709� left from path dir" 191 "89.291� left from path dir" 192 "87.874� left from path dir" 193 "86.457� left from path dir" 194 "85.039� left from path dir" 195 "83.622� left from path dir" 196 "82.205� left from path dir" 197 "80.787� left from path dir" 198 "79.37� left from path dir" 199 "77.953� left from path dir" 200 "76.535� left from path dir" 201 "75.118� left from path dir" 202 "73.701� left from path dir" 203 "72.283� left from path dir" 204 "70.866� left from path dir" 205 "69.449� left from path dir" 206 "68.031� left from path dir" 207 "66.614� left from path dir" 208 "65.197� left from path dir" 209 "63.78� left from path dir" 210 "62.362� left from path dir" 211 "60.945� left from path dir" 212 "59.528� left from path dir" 213 "58.11� left from path dir" 214 "56.693� left from path dir" 215 "55.276� left from path dir" 216 "53.858� left from path dir" 217 "52.441� left from path dir" 218 "51.024� left from path dir" 219 "49.606� left from path dir" 220 "48.189� left from path dir" 221 "46.772� left from path dir" 222 "45.354� left from path dir" 223 "43.937� left from path dir" 224 "42.52� left from path dir" 225 "41.102� left from path dir" 226 "39.685� left from path dir" 227 "38.268� left from path dir" 228 "36.85� left from path dir" 229 "35.433� left from path dir" 230 "34.016� left from path dir" 231 "32.598� left from path dir" 232 "31.181� left from path dir" 233 "29.764� left from path dir" 234 "28.346� left from path dir" 235 "26.929� left from path dir" 236 "25.512� left from path dir" 237 "24.094� left from path dir" 238 "22.677� left from path dir" 239 "21.26� left from path dir" 240 "19.843� left from path dir" 241 "18.425� left from path dir" 242 "17.008� left from path dir" 243 "15.591� left from path dir" 244 "14.173� left from path dir" 245 "12.756� left from path dir" 246 "11.339� left from path dir" 247 "9.921� left from path dir" 248 "8.504� left from path dir" 249 "7.087� left from path dir" 250 "5.669� left from path dir" 251 "4.252� left from path dir" 252 "2.835� left from path dir" 253 "1.417� left from path dir" 254 "Unknown" 255 "N/A" ;
VAL_ 2566859804 Stub_ComplexInters 0 "Not part of complex intersection" 1 "Part of a complex intersection" 2 "Unknown" 3 "N/A" ;
VAL_ 2566859804 Stub_PartOfCalcRoute 0 "Not part from this point on" 1 "Part from this point on" 2 "Unknown" 3 "N/A" ;
VAL_ 2566859804 Stub_FunctRoadClass 0 "Unknown" 1 "Class 1" 2 "Class 2" 3 "Class 3" 4 "Class 4" 5 "Class 5" 6 "Class 6" 7 "N/A" ;
VAL_ 2566859804 Stub_RelProb 0 "Turn is not allowed" 31 "Unknown or N/A" ;
VAL_ 2566859804 Stub_Update 0 "False" 1 "True" ;
VAL_ 2566859804 Stub_Retr 0 "False" 1 "True" ;
VAL_ 2566859804 Stub_SubPathIx 0 "Unknown" 7 "Reserved" ;
VAL_ 2566859804 Stub_PathIx 0 "Unknown" 5 "Not further appended" 6 "HEADING CHANGE" 7 "Reserved" ;
VAL_ 2566859804 Stub_Ofs 8191 "Invalid" ;
VAL_ 2566859804 MsgType_FF2C1C 0 "Reserved1" 1 "POSITION" 2 "SEGMENT" 3 "STUB" 4 "PROFILE SHORT" 5 "PROFILE LONG" 6 "META-DATA" 7 "Reserved2" ;
VAL_ 2566860060 ProfShort_Val1_1_Curv 0 "< -0.16192" 510 "-0.00001" 511 "0.00000" 512 "0.00001" 513 "0.00002" 573 "0.00062" 574 "0.00063" 575 "0.00064" 576 "0.00066" 637 "0.00188" 638 "0.00190" 639 "0.00192" 640 "0.00196" 701 "0.00440" 702 "0.00444" 703 "0.00448" 704 "0.00456" 765 "0.00944" 766 "0.00952" 767 "0.00960" 768 "0.00976" 830 "0.01968" 831 "0.01984" 832 "0.02016" 833 "0.02048" 893 "0.03968" 894 "0.04000" 895 "0.04032" 896 "0.04096" 957 "0.08000" 958 "0.08064" 959 "0.08128" 960 "0.08256" 1021 "0.16064" 1022 "> 0.16192" 1023 "Unknown" ;
VAL_ 2566860060 ProfShort_Val1_2_RouteNumTypes 0 "N/A" 1023 "Unknown or N/A" ;
VAL_ 2566860060 ProfShort_Val1_3_Slope 1023 "Unknown" ;
VAL_ 2566860060 ProfShort_Val1_4_Slope 1023 "Unknown" ;
VAL_ 2566860060 ProfShort_Val1_5_RoadAcc 0 "No access" 1023 "Unknown or N/A" ;
VAL_ 2566860060 ProfShort_Val1_6_RoadCond 1023 "Unknown" ;
VAL_ 2566860060 ProfShort_Val1_7_VarSpeedSignPos 0 "Unknown1" 1023 "Unknown2" ;
VAL_ 2566860060 ProfShort_Val1_8_HeadChg 0 "In path direction" 1 "1.417� right from path dir" 2 "2.835� right from path dir" 3 "4.252� right from path dir" 4 "5.669� right from path dir" 5 "7.087� right from path dir" 6 "8.504� right from path dir" 7 "9.921� right from path dir" 8 "11.339� right from path dir" 9 "12.756� right from path dir" 10 "14.173� right from path dir" 11 "15.591� right from path dir" 12 "17.008� right from path dir" 13 "18.425� right from path dir" 14 "19.843� right from path dir" 15 "21.26� right from path dir" 16 "22.677� right from path dir" 17 "24.094� right from path dir" 18 "25.512� right from path dir" 19 "26.929� right from path dir" 20 "28.346� right from path dir" 21 "29.764� right from path dir" 22 "31.181� right from path dir" 23 "32.598� right from path dir" 24 "34.016� right from path dir" 25 "35.433� right from path dir" 26 "36.85� right from path dir" 27 "38.268� right from path dir" 28 "39.685� right from path dir" 29 "41.102� right from path dir" 30 "42.52� right from path dir" 31 "43.937� right from path dir" 32 "45.354� right from path dir" 33 "46.772� right from path dir" 34 "48.189� right from path dir" 35 "49.606� right from path dir" 36 "51.024� right from path dir" 37 "52.441� right from path dir" 38 "53.858� right from path dir" 39 "55.276� right from path dir" 40 "56.693� right from path dir" 41 "58.11� right from path dir" 42 "59.528� right from path dir" 43 "60.945� right from path dir" 44 "62.362� right from path dir" 45 "63.78� right from path dir" 46 "65.197� right from path dir" 47 "66.614� right from path dir" 48 "68.031� right from path dir" 49 "69.449� right from path dir" 50 "70.866� right from path dir" 51 "72.283� right from path dir" 52 "73.701� right from path dir" 53 "75.118� right from path dir" 54 "76.535� right from path dir" 55 "77.953� right from path dir" 56 "79.37� right from path dir" 57 "80.787� right from path dir" 58 "82.205� right from path dir" 59 "83.622� right from path dir" 60 "85.039� right from path dir" 61 "86.457� right from path dir" 62 "87.874� right from path dir" 63 "89.291� right from path dir" 64 "90.709� right from path dir" 65 "92.126� right from path dir" 66 "93.543� right from path dir" 67 "94.961� right from path dir" 68 "96.378� right from path dir" 69 "97.795� right from path dir" 70 "99.213� right from path dir" 71 "100.63� right from path dir" 72 "102.047� right from path dir" 73 "103.465� right from path dir" 74 "104.882� right from path dir" 75 "106.299� right from path dir" 76 "107.717� right from path dir" 77 "109.134� right from path dir" 78 "110.551� right from path dir" 79 "111.969� right from path dir" 80 "113.386� right from path dir" 81 "114.803� right from path dir" 82 "116.22� right from path dir" 83 "117.638� right from path dir" 84 "119.055� right from path dir" 85 "120.472� right from path dir" 86 "121.89� right from path dir" 87 "123.307� right from path dir" 88 "124.724� right from path dir" 89 "126.142� right from path dir" 90 "127.559� right from path dir" 91 "128.976� right from path dir" 92 "130.394� right from path dir" 93 "131.811� right from path dir" 94 "133.228� right from path dir" 95 "134.646� right from path dir" 96 "136.063� right from path dir" 97 "137.48� right from path dir" 98 "138.898� right from path dir" 99 "140.315� right from path dir" 100 "141.732� right from path dir" 101 "143.15� right from path dir" 102 "144.567� right from path dir" 103 "145.984� right from path dir" 104 "147.402� right from path dir" 105 "148.819� right from path dir" 106 "150.236� right from path dir" 107 "151.654� right from path dir" 108 "153.071� right from path dir" 109 "154.488� right from path dir" 110 "155.906� right from path dir" 111 "157.323� right from path dir" 112 "158.74� right from path dir" 113 "160.157� right from path dir" 114 "161.575� right from path dir" 115 "162.992� right from path dir" 116 "164.409� right from path dir" 117 "165.827� right from path dir" 118 "167.244� right from path dir" 119 "168.661� right from path dir" 120 "170.079� right from path dir" 121 "171.496� right from path dir" 122 "172.913� right from path dir" 123 "174.331� right from path dir" 124 "175.748� right from path dir" 125 "177.165� right from path dir" 126 "178.583� right from path dir" 127 "Opposite direction" 128 "178.583� left from path dir" 129 "177.165� left from path dir" 130 "175.748� left from path dir" 131 "174.331� left from path dir" 132 "172.913� left from path dir" 133 "171.496� left from path dir" 134 "170.079� left from path dir" 135 "168.661� left from path dir" 136 "167.244� left from path dir" 137 "165.827� left from path dir" 138 "164.409� left from path dir" 139 "162.992� left from path dir" 140 "161.575� left from path dir" 141 "160.157� left from path dir" 142 "158.74� left from path dir" 143 "157.323� left from path dir" 144 "155.906� left from path dir" 145 "154.488� left from path dir" 146 "153.071� left from path dir" 147 "151.654� left from path dir" 148 "150.236� left from path dir" 149 "148.819� left from path dir" 150 "147.402� left from path dir" 151 "145.984� left from path dir" 152 "144.567� left from path dir" 153 "143.15� left from path dir" 154 "141.732� left from path dir" 155 "140.315� left from path dir" 156 "138.898� left from path dir" 157 "137.48� left from path dir" 158 "136.063� left from path dir" 159 "134.646� left from path dir" 160 "133.228� left from path dir" 161 "131.811� left from path dir" 162 "130.394� left from path dir" 163 "128.976� left from path dir" 164 "127.559� left from path dir" 165 "126.142� left from path dir" 166 "124.724� left from path dir" 167 "123.307� left from path dir" 168 "121.89� left from path dir" 169 "120.472� left from path dir" 170 "119.055� left from path dir" 171 "117.638� left from path dir" 172 "116.22� left from path dir" 173 "114.803� left from path dir" 174 "113.386� left from path dir" 175 "111.969� left from path dir" 176 "110.551� left from path dir" 177 "109.134� left from path dir" 178 "107.717� left from path dir" 179 "106.299� left from path dir" 180 "104.882� left from path dir" 181 "103.465� left from path dir" 182 "102.047� left from path dir" 183 "100.63� left from path dir" 184 "99.213� left from path dir" 185 "97.795� left from path dir" 186 "96.378� left from path dir" 187 "94.961� left from path dir" 188 "93.543� left from path dir" 189 "92.126� left from path dir" 190 "90.709� left from path dir" 191 "89.291� left from path dir" 192 "87.874� left from path dir" 193 "86.457� left from path dir" 194 "85.039� left from path dir" 195 "83.622� left from path dir" 196 "82.205� left from path dir" 197 "80.787� left from path dir" 198 "79.37� left from path dir" 199 "77.953� left from path dir" 200 "76.535� left from path dir" 201 "75.118� left from path dir" 202 "73.701� left from path dir" 203 "72.283� left from path dir" 204 "70.866� left from path dir" 205 "69.449� left from path dir" 206 "68.031� left from path dir" 207 "66.614� left from path dir" 208 "65.197� left from path dir" 209 "63.78� left from path dir" 210 "62.362� left from path dir" 211 "60.945� left from path dir" 212 "59.528� left from path dir" 213 "58.11� left from path dir" 214 "56.693� left from path dir" 215 "55.276� left from path dir" 216 "53.858� left from path dir" 217 "52.441� left from path dir" 218 "51.024� left from path dir" 219 "49.606� left from path dir" 220 "48.189� left from path dir" 221 "46.772� left from path dir" 222 "45.354� left from path dir" 223 "43.937� left from path dir" 224 "42.52� left from path dir" 225 "41.102� left from path dir" 226 "39.685� left from path dir" 227 "38.268� left from path dir" 228 "36.85� left from path dir" 229 "35.433� left from path dir" 230 "34.016� left from path dir" 231 "32.598� left from path dir" 232 "31.181� left from path dir" 233 "29.764� left from path dir" 234 "28.346� left from path dir" 235 "26.929� left from path dir" 236 "25.512� left from path dir" 237 "24.094� left from path dir" 238 "22.677� left from path dir" 239 "21.26� left from path dir" 240 "19.843� left from path dir" 241 "18.425� left from path dir" 242 "17.008� left from path dir" 243 "15.591� left from path dir" 244 "14.173� left from path dir" 245 "12.756� left from path dir" 246 "11.339� left from path dir" 247 "9.921� left from path dir" 248 "8.504� left from path dir" 249 "7.087� left from path dir" 250 "5.669� left from path dir" 251 "4.252� left from path dir" 252 "2.835� left from path dir" 253 "1.417� left from path dir" 254 "Unknown" 255 "N/A" 1023 "N/A" ;
VAL_ 2566860060 ProfShort_Val1_9_RsvdForStdTypes 1023 "Unknown or N/A" ;
VAL_ 2566860060 ProfShort_Val1_16_RsvdForSysSpec 1023 "Unknown or N/A" ;
VAL_ 2566860060 ProfShort_Val0_1_Curv 0 "< -0.16192" 510 "-0.00001" 511 "0.00000" 512 "0.00001" 513 "0.00002" 573 "0.00062" 574 "0.00063" 575 "0.00064" 576 "0.00066" 637 "0.00188" 638 "0.00190" 639 "0.00192" 640 "0.00196" 701 "0.00440" 702 "0.00444" 703 "0.00448" 704 "0.00456" 765 "0.00944" 766 "0.00952" 767 "0.00960" 768 "0.00976" 830 "0.01968" 831 "0.01984" 832 "0.02016" 833 "0.02048" 893 "0.03968" 894 "0.04000" 895 "0.04032" 896 "0.04096" 957 "0.08000" 958 "0.08064" 959 "0.08128" 960 "0.08256" 1021 "0.16064" 1022 "> 0.16192" 1023 "Unknown" ;
VAL_ 2566860060 ProfShort_Val0_2_RouteNumTypes 0 "N/A" 1023 "Unknown or N/A" ;
VAL_ 2566860060 ProfShort_Val0_3_Slope 1023 "Unknown" ;
VAL_ 2566860060 ProfShort_Val0_4_Slope 1023 "Unknown" ;
VAL_ 2566860060 ProfShort_Val0_5_RoadAcc 0 "No access" 1023 "Unknown or N/A" ;
VAL_ 2566860060 ProfShort_Val0_6_RoadCond 1023 "Unknown" ;
VAL_ 2566860060 ProfShort_Val0_7_VarSpeedSignPos 0 "Unknown1" 1023 "Unknown2" ;
VAL_ 2566860060 ProfShort_Val0_8_HeadChg 0 "In path direction" 1 "1.417� right from path dir" 2 "2.835� right from path dir" 3 "4.252� right from path dir" 4 "5.669� right from path dir" 5 "7.087� right from path dir" 6 "8.504� right from path dir" 7 "9.921� right from path dir" 8 "11.339� right from path dir" 9 "12.756� right from path dir" 10 "14.173� right from path dir" 11 "15.591� right from path dir" 12 "17.008� right from path dir" 13 "18.425� right from path dir" 14 "19.843� right from path dir" 15 "21.26� right from path dir" 16 "22.677� right from path dir" 17 "24.094� right from path dir" 18 "25.512� right from path dir" 19 "26.929� right from path dir" 20 "28.346� right from path dir" 21 "29.764� right from path dir" 22 "31.181� right from path dir" 23 "32.598� right from path dir" 24 "34.016� right from path dir" 25 "35.433� right from path dir" 26 "36.85� right from path dir" 27 "38.268� right from path dir" 28 "39.685� right from path dir" 29 "41.102� right from path dir" 30 "42.52� right from path dir" 31 "43.937� right from path dir" 32 "45.354� right from path dir" 33 "46.772� right from path dir" 34 "48.189� right from path dir" 35 "49.606� right from path dir" 36 "51.024� right from path dir" 37 "52.441� right from path dir" 38 "53.858� right from path dir" 39 "55.276� right from path dir" 40 "56.693� right from path dir" 41 "58.11� right from path dir" 42 "59.528� right from path dir" 43 "60.945� right from path dir" 44 "62.362� right from path dir" 45 "63.78� right from path dir" 46 "65.197� right from path dir" 47 "66.614� right from path dir" 48 "68.031� right from path dir" 49 "69.449� right from path dir" 50 "70.866� right from path dir" 51 "72.283� right from path dir" 52 "73.701� right from path dir" 53 "75.118� right from path dir" 54 "76.535� right from path dir" 55 "77.953� right from path dir" 56 "79.37� right from path dir" 57 "80.787� right from path dir" 58 "82.205� right from path dir" 59 "83.622� right from path dir" 60 "85.039� right from path dir" 61 "86.457� right from path dir" 62 "87.874� right from path dir" 63 "89.291� right from path dir" 64 "90.709� right from path dir" 65 "92.126� right from path dir" 66 "93.543� right from path dir" 67 "94.961� right from path dir" 68 "96.378� right from path dir" 69 "97.795� right from path dir" 70 "99.213� right from path dir" 71 "100.63� right from path dir" 72 "102.047� right from path dir" 73 "103.465� right from path dir" 74 "104.882� right from path dir" 75 "106.299� right from path dir" 76 "107.717� right from path dir" 77 "109.134� right from path dir" 78 "110.551� right from path dir" 79 "111.969� right from path dir" 80 "113.386� right from path dir" 81 "114.803� right from path dir" 82 "116.22� right from path dir" 83 "117.638� right from path dir" 84 "119.055� right from path dir" 85 "120.472� right from path dir" 86 "121.89� right from path dir" 87 "123.307� right from path dir" 88 "124.724� right from path dir" 89 "126.142� right from path dir" 90 "127.559� right from path dir" 91 "128.976� right from path dir" 92 "130.394� right from path dir" 93 "131.811� right from path dir" 94 "133.228� right from path dir" 95 "134.646� right from path dir" 96 "136.063� right from path dir" 97 "137.48� right from path dir" 98 "138.898� right from path dir" 99 "140.315� right from path dir" 100 "141.732� right from path dir" 101 "143.15� right from path dir" 102 "144.567� right from path dir" 103 "145.984� right from path dir" 104 "147.402� right from path dir" 105 "148.819� right from path dir" 106 "150.236� right from path dir" 107 "151.654� right from path dir" 108 "153.071� right from path dir" 109 "154.488� right from path dir" 110 "155.906� right from path dir" 111 "157.323� right from path dir" 112 "158.74� right from path dir" 113 "160.157� right from path dir" 114 "161.575� right from path dir" 115 "162.992� right from path dir" 116 "164.409� right from path dir" 117 "165.827� right from path dir" 118 "167.244� right from path dir" 119 "168.661� right from path dir" 120 "170.079� right from path dir" 121 "171.496� right from path dir" 122 "172.913� right from path dir" 123 "174.331� right from path dir" 124 "175.748� right from path dir" 125 "177.165� right from path dir" 126 "178.583� right from path dir" 127 "Opposite direction" 128 "178.583� left from path dir" 129 "177.165� left from path dir" 130 "175.748� left from path dir" 131 "174.331� left from path dir" 132 "172.913� left from path dir" 133 "171.496� left from path dir" 134 "170.079� left from path dir" 135 "168.661� left from path dir" 136 "167.244� left from path dir" 137 "165.827� left from path dir" 138 "164.409� left from path dir" 139 "162.992� left from path dir" 140 "161.575� left from path dir" 141 "160.157� left from path dir" 142 "158.74� left from path dir" 143 "157.323� left from path dir" 144 "155.906� left from path dir" 145 "154.488� left from path dir" 146 "153.071� left from path dir" 147 "151.654� left from path dir" 148 "150.236� left from path dir" 149 "148.819� left from path dir" 150 "147.402� left from path dir" 151 "145.984� left from path dir" 152 "144.567� left from path dir" 153 "143.15� left from path dir" 154 "141.732� left from path dir" 155 "140.315� left from path dir" 156 "138.898� left from path dir" 157 "137.48� left from path dir" 158 "136.063� left from path dir" 159 "134.646� left from path dir" 160 "133.228� left from path dir" 161 "131.811� left from path dir" 162 "130.394� left from path dir" 163 "128.976� left from path dir" 164 "127.559� left from path dir" 165 "126.142� left from path dir" 166 "124.724� left from path dir" 167 "123.307� left from path dir" 168 "121.89� left from path dir" 169 "120.472� left from path dir" 170 "119.055� left from path dir" 171 "117.638� left from path dir" 172 "116.22� left from path dir" 173 "114.803� left from path dir" 174 "113.386� left from path dir" 175 "111.969� left from path dir" 176 "110.551� left from path dir" 177 "109.134� left from path dir" 178 "107.717� left from path dir" 179 "106.299� left from path dir" 180 "104.882� left from path dir" 181 "103.465� left from path dir" 182 "102.047� left from path dir" 183 "100.63� left from path dir" 184 "99.213� left from path dir" 185 "97.795� left from path dir" 186 "96.378� left from path dir" 187 "94.961� left from path dir" 188 "93.543� left from path dir" 189 "92.126� left from path dir" 190 "90.709� left from path dir" 191 "89.291� left from path dir" 192 "87.874� left from path dir" 193 "86.457� left from path dir" 194 "85.039� left from path dir" 195 "83.622� left from path dir" 196 "82.205� left from path dir" 197 "80.787� left from path dir" 198 "79.37� left from path dir" 199 "77.953� left from path dir" 200 "76.535� left from path dir" 201 "75.118� left from path dir" 202 "73.701� left from path dir" 203 "72.283� left from path dir" 204 "70.866� left from path dir" 205 "69.449� left from path dir" 206 "68.031� left from path dir" 207 "66.614� left from path dir" 208 "65.197� left from path dir" 209 "63.78� left from path dir" 210 "62.362� left from path dir" 211 "60.945� left from path dir" 212 "59.528� left from path dir" 213 "58.11� left from path dir" 214 "56.693� left from path dir" 215 "55.276� left from path dir" 216 "53.858� left from path dir" 217 "52.441� left from path dir" 218 "51.024� left from path dir" 219 "49.606� left from path dir" 220 "48.189� left from path dir" 221 "46.772� left from path dir" 222 "45.354� left from path dir" 223 "43.937� left from path dir" 224 "42.52� left from path dir" 225 "41.102� left from path dir" 226 "39.685� left from path dir" 227 "38.268� left from path dir" 228 "36.85� left from path dir" 229 "35.433� left from path dir" 230 "34.016� left from path dir" 231 "32.598� left from path dir" 232 "31.181� left from path dir" 233 "29.764� left from path dir" 234 "28.346� left from path dir" 235 "26.929� left from path dir" 236 "25.512� left from path dir" 237 "24.094� left from path dir" 238 "22.677� left from path dir" 239 "21.26� left from path dir" 240 "19.843� left from path dir" 241 "18.425� left from path dir" 242 "17.008� left from path dir" 243 "15.591� left from path dir" 244 "14.173� left from path dir" 245 "12.756� left from path dir" 246 "11.339� left from path dir" 247 "9.921� left from path dir" 248 "8.504� left from path dir" 249 "7.087� left from path dir" 250 "5.669� left from path dir" 251 "4.252� left from path dir" 252 "2.835� left from path dir" 253 "1.417� left from path dir" 254 "Unknown" 255 "N/A" 1023 "N/A" ;
VAL_ 2566860060 ProfShort_Val0_9_RsvdForStdTypes 1023 "Unknown or N/A" ;
VAL_ 2566860060 ProfShort_Val0_16_RsvdForSysSpec 1023 "Unknown or N/A" ;
VAL_ 2566860060 ProfShort_Dist1 1023 "Invalid" ;
VAL_ 2566860060 ProfShort_Accur 0 "Highest" 2 "Lowest" 3 "Unknown" ;
VAL_ 2566860060 ProfShort_Update 0 "False" 1 "True" ;
VAL_ 2566860060 ProfShort_Retr 0 "False" 1 "True" ;
VAL_ 2566860060 ProfShort_CtrlPnt 0 "False" 1 "True" ;
VAL_ 2566860060 ProfShort_PathIx 0 "Unknown" 7 "Reserved" ;
VAL_ 2566860060 ProfShort_Ofs 8191 "Invalid" ;
VAL_ 2566860060 MsgType_FF2D1C 0 "Reserved1" 1 "POSITION" 2 "SEGMENT" 3 "STUB" 4 "PROFILE SHORT" 5 "PROFILE LONG" 6 "META-DATA" 7 "Reserved2" ;
VAL_ 2566860316 ProfLong_Val96_TimeVal 0 "not valid at this moment" 1 "valid at this moment" 2 "Unknown if valid at this moment" 3 "N/A" ;
VAL_ 2566860316 ProfLong_Val97_TimeDep 0 "Speed limit not time dependent" 1 "Speed limit time dependent" ;
VAL_ 2566860316 ProfLong_Val93_HazardousGoods 0 "Applies to all vehicles" 1 "explosive goods only" 2 "goods harmful for water" 3 "Reserved1" 4 "Reserved2" 5 "Reserved3" 6 "unknown" 7 "N/A" ;
VAL_ 2566860316 ProfLong_Val94_WeatherRestr 0 "No weather restriction" 1 "Speed limit only valid if snow" 2 "Speed limit only valid if fog" 3 "Speed limit only valid if rain" 4 "Reserved1" 5 "Reserved2" 6 "Unknown" 7 "N/A" ;
VAL_ 2566860316 ProfLong_Val95_Type 0 "Explicit SL given by a sign" 1 "Implicit SL given by reg" 2 "unknown if explicit or implicit" 3 "unknown or N/A" ;
VAL_ 2566860316 ProfLong_Val92_Wt 254 "w > 62.5 tons" 255 "N/A" ;
VAL_ 2566860316 ProfLong_Val1_Long -1 "Unknown or N/A" ;
VAL_ 2566860316 ProfLong_Val2_Lat -1 "Unknown or N/A" ;
VAL_ 2566860316 ProfLong_Val3_Altitude -1 "Unknown or N/A" ;
VAL_ 2566860316 ProfLong_Val4_CtrlPntLong -1 "Unknown or N/A" ;
VAL_ 2566860316 ProfLong_Val5_CtrlPntLat -1 "Unknown or N/A" ;
VAL_ 2566860316 ProfLong_Val6_CtrlPntAltitude -1 "Unknown or N/A" ;
VAL_ 2566860316 ProfLong_Val7_LinkId -1 "Unknown or N/A" ;
VAL_ 2566860316 ProfLong_Val8_TrafficSign -1 "Unknown or N/A" ;
VAL_ 2566860316 ProfLong_Val91_Speed 254 "Speed > 253" 255 "N/A" ;
VAL_ 2566860316 ProfLong_Val10_ExLane -1 "Unknown or N/A" ;
VAL_ 2566860316 ProfLong_Val11_RsvdForStdTypes -1 "Unknown or N/A" ;
VAL_ 2566860316 ProfLong_Val12_RsvdForStdTypes -1 "Unknown or N/A" ;
VAL_ 2566860316 ProfLong_Val13_RsvdForStdTypes -1 "Unknown or N/A" ;
VAL_ 2566860316 ProfLong_Val14_RsvdForStdTypes -1 "Unknown or N/A" ;
VAL_ 2566860316 ProfLong_Val15_RsvdForStdTypes -1 "Unknown or N/A" ;
VAL_ 2566860316 ProfLong_Val16_RsvdForSysSpecTyp -1 "Unknown or N/A" ;
VAL_ 2566860316 ProfLong_Val17_RsvdForSysSpecTyp -1 "Unknown or N/A" ;
VAL_ 2566860316 ProfLong_Val18_RsvdForSysSpecTyp -1 "Unknown or N/A" ;
VAL_ 2566860316 ProfLong_Val19_RsvdForSysSpecTyp -1 "Unknown or N/A" ;
VAL_ 2566860316 ProfLong_Val20_RsvdForSysSpecTyp -1 "Unknown or N/A" ;
VAL_ 2566860316 ProfLong_Val21_RsvdForSysSpecTyp -1 "Unknown or N/A" ;
VAL_ 2566860316 ProfLong_Val22_RsvdForSysSpecTyp -1 "Unknown or N/A" ;
VAL_ 2566860316 ProfLong_Val23_RsvdForSysSpecTyp -1 "Unknown or N/A" ;
VAL_ 2566860316 ProfLong_Val24_RsvdForSysSpecTyp -1 "Unknown or N/A" ;
VAL_ 2566860316 ProfLong_Val25_RsvdForSysSpecTyp -1 "Unknown or N/A" ;
VAL_ 2566860316 ProfLong_Val26_RsvdForSysSpecTyp -1 "Unknown or N/A" ;
VAL_ 2566860316 ProfLong_Val27_RsvdForSysSpecTyp -1 "Unknown or N/A" ;
VAL_ 2566860316 ProfLong_Val28_RsvdForSysSpecTyp -1 "Unknown or N/A" ;
VAL_ 2566860316 ProfLong_Val29_RsvdForSysSpecTyp -1 "Unknown or N/A" ;
VAL_ 2566860316 ProfLong_Val30_RsvdForSysSpecTyp -1 "Unknown or N/A" ;
VAL_ 2566860316 ProfLong_Val31_RsvdForSysSpecTyp -1 "Unknown or N/A" ;
VAL_ 2566860316 ProfLong_Update 0 "False" 1 "True" ;
VAL_ 2566860316 ProfLong_Retr 0 "False" 1 "True" ;
VAL_ 2566860316 ProfLong_CtrlPnt 0 "False" 1 "True" ;
VAL_ 2566860316 ProfLong_PathIx 0 "Unknown" 7 "Reserved" ;
VAL_ 2566860316 ProfLong_Ofs 8191 "Invalid" ;
VAL_ 2566860316 MsgType_FF2E1C 0 "Reserved1" 1 "POSITION" 2 "SEGMENT" 3 "STUB" 4 "PROFILE SHORT" 5 "PROFILE LONG" 6 "META-DATA" 7 "Reserved2" ;
VAL_ 2566860572 Meta_SpeedUnits 0 "km/h" 1 "mph" ;
VAL_ 2566860572 Meta_MapVerYr 63 "N/A" ;
VAL_ 2566860572 Meta_RegionCode 0 "Unknown" 32767 "N/A" ;
VAL_ 2566860572 Meta_DrivSide 0 "Left." 1 "Right" ;
VAL_ 2566860572 Meta_HwVer 0 "Unknown" ;
VAL_ 2566860572 Meta_CntryCode 0 "Unknown" ;
VAL_ 2566860572 Meta_MapProvider 0 "Unknown" 1 "NAVTEQ" 2 "TeleAtlas" 3 "Zenrin" 4 "Reserved1" 5 "Reserved2" 6 "Reserved3" 7 "N/A." ;
VAL_ 2566860572 MsgType_FF2F1C 0 "Reserved1" 1 "POSITION" 2 "SEGMENT" 3 "STUB" 4 "PROFILE SHORT" 5 "PROFILE LONG" 6 "META-DATA" 7 "Reserved2" ;
VAL_ 2283315200 BatRecalibration 0 ": False" 1 ": True" ;
VAL_ 2283315200 BcmSamFailSts 0 "No fault present" 1 "Fault present" ;
VAL_ 2283315200 IbsFail 0 "No fault present" 1 "Fault present" ;
VAL_ 2566873377 MsgCks_FF6121 15 "Not Available, request honored" ;
VAL_ 2566873377 MsgCnt4 8 "Reserved" 9 "Reserved" 10 "Reserved" 11 "Reserved" 12 "Reserved" 13 "Reserved" 14 "Reserved" 15 "Not Available, request honored" ;
VAL_ 2566873377 HandbrakeFullyExSw 0 "Not Set" 1 "Set" 2 "Error" 3 "Not Available" ;
VAL_ 2566873377 EngAuxShutdnSw 0 "Off" 1 "On" 2 "Error" 3 "Not Available" ;
VAL_ 2566873377 Vsl2Req 0 "Off" 1 "On" 2 "Reserved" 3 "No Action" ;
VAL_ 2566873377 VslaReq 0 "Off" 1 "On" 2 "Error" 3 "No Action" ;
VAL_ 2566873377 CltOpenSw 0 "Not fully pressed" 1 "Fully pressed" 2 "Error" 3 "Not Available" ;
VAL_ 2566873377 MsgCnt_FF6121 3 "Not Available" ;
VAL_ 2566873377 CltSw 0 "Released" 1 "Depressed" 2 "Error" 3 "Not Available" ;
VAL_ 2566873377 RedBrkSw 0 "Released" 1 "Depressed" 2 "Error" 3 "Not Available" ;
VAL_ 2566722889 BatChg1Sts 0 "Idling, disconn. from charger." 1 "Charging the battery." 2 "StandBy or maintaining charge" 13 "Battery failure (high temp, ...)" 14 "Charger failure" 15 "Not Available." ;
VAL_ 2566723351 AllAirbagDeactSwSts 0 "Activated" 1 "Deactivated" 2 "Error, cannot be determined" 3 "Not Available" ;
VAL_ 2566723351 PassAirbagDeactSwSts 0 "Activated" 1 "Deactivated" 2 "Error, cannot be determined" 3 "Not Available" ;
VAL_ 2566723361 PassBeltlockSts 0 "Unlocked" 1 "Locked" 2 "Error,State cannot be determined" 3 "Not Available" ;
VAL_ 2566723361 DrivBeltlockSts 0 "Unlocked" 1 "Locked" 2 "Error,State cannot be determined" 3 "Not Available" ;
